VERSION ""

NS_ :

BS_:

BU_:

BO_ 2566587390 NTEHEA: 200 Vector__XXX
 SG_ NOxTEAtvtLtERTB1Tt : 0|32@1+ (1,0) [0|4211081215] "s" Vector__XXX
 SG_ NOxTrkngEngnAtvtLftmEngnRnTmBn2 : 32|32@1+ (1,0) [0|4211081215] "s" Vector__XXX
 SG_ NOxTrkngEngnAtvtLftmEngnRnTmBn3 : 64|32@1+ (1,0) [0|4211081215] "s" Vector__XXX
 SG_ NOxTrkngEngnAtvtLftmEngnRnTmBn4 : 96|32@1+ (1,0) [0|4211081215] "s" Vector__XXX
 SG_ NOxTrkngEngnAtvtLftmEngnRnTmBn5 : 128|32@1+ (1,0) [0|4211081215] "s" Vector__XXX
 SG_ NOxTrkngEngnAtvtLftmEngnRnTmBn6 : 160|32@1+ (1,0) [0|4211081215] "s" Vector__XXX
 SG_ NOxTrkngEngnAtvtLftmEngnRnTmBn7 : 192|32@1+ (1,0) [0|4211081215] "s" Vector__XXX
 SG_ NOxTrkngEngnAtvtLftmEngnRnTmBn8 : 224|32@1+ (1,0) [0|4211081215] "s" Vector__XXX
 SG_ NOxTrkngEngnAtvtLftmEngnRnTmBn9 : 256|32@1+ (1,0) [0|4211081215] "s" Vector__XXX
 SG_ NOxTEAtvtLtERTB10 : 288|32@1+ (1,0) [0|4211081215] "s" Vector__XXX
 SG_ NOxTEAtvtLtERTB11 : 320|32@1+ (1,0) [0|4211081215] "s" Vector__XXX
 SG_ NOxTEAtvtLtERTB12 : 352|32@1+ (1,0) [0|4211081215] "s" Vector__XXX
 SG_ NOxTEAtvtLtERTB13 : 384|32@1+ (1,0) [0|4211081215] "s" Vector__XXX
 SG_ NOxTEAtvtLtERTB14 : 416|32@1+ (1,0) [0|4211081215] "s" Vector__XXX
 SG_ NOxTEAtvtLtERTB15NTEBIN : 448|32@1+ (1,0) [0|4211081215] "s" Vector__XXX
 SG_ NOxTEAtvtLtERTB16RB : 480|32@1+ (1,0) [0|4211081215] "s" Vector__XXX
 SG_ NOxTEAtvtLtERTB17MILOB : 512|32@1+ (1,0) [0|4211081215] "s" Vector__XXX

BO_ 2566587646 NTVMEA: 200 Vector__XXX
 SG_ NOxTEAtvtLtVDstB1Tt : 0|32@1+ (5,0) [0|21055406075] "m" Vector__XXX
 SG_ NOxTrkngEngnAtvtLftmVhlDstnBn2 : 32|32@1+ (5,0) [0|21055406075] "m" Vector__XXX
 SG_ NOxTrkngEngnAtvtLftmVhlDstnBn3 : 64|32@1+ (5,0) [0|21055406075] "m" Vector__XXX
 SG_ NOxTrkngEngnAtvtLftmVhlDstnBn4 : 96|32@1+ (5,0) [0|21055406075] "m" Vector__XXX
 SG_ NOxTrkngEngnAtvtLftmVhlDstnBn5 : 128|32@1+ (5,0) [0|21055406075] "m" Vector__XXX
 SG_ NOxTrkngEngnAtvtLftmVhlDstnBn6 : 160|32@1+ (5,0) [0|21055406075] "m" Vector__XXX
 SG_ NOxTrkngEngnAtvtLftmVhlDstnBn7 : 192|32@1+ (5,0) [0|21055406075] "m" Vector__XXX
 SG_ NOxTrkngEngnAtvtLftmVhlDstnBn8 : 224|32@1+ (5,0) [0|21055406075] "m" Vector__XXX
 SG_ NOxTrkngEngnAtvtLftmVhlDstnBn9 : 256|32@1+ (5,0) [0|21055406075] "m" Vector__XXX
 SG_ NOxTrkngEngnAtvtLftmVhlDstnBn10 : 288|32@1+ (5,0) [0|21055406075] "m" Vector__XXX
 SG_ NOxTrkngEngnAtvtLftmVhlDstnBn11 : 320|32@1+ (5,0) [0|21055406075] "m" Vector__XXX
 SG_ NOxTrkngEngnAtvtLftmVhlDstnBn12 : 352|32@1+ (5,0) [0|21055406075] "m" Vector__XXX
 SG_ NOxTrkngEngnAtvtLftmVhlDstnBn13 : 384|32@1+ (5,0) [0|21055406075] "m" Vector__XXX
 SG_ NOxTrkngEngnAtvtLftmVhlDstnBn14 : 416|32@1+ (5,0) [0|21055406075] "m" Vector__XXX
 SG_ NOxTEAtvtLtVDstB15NTEBIN : 448|32@1+ (5,0) [0|21055406075] "m" Vector__XXX
 SG_ NOxTEAtvtLtVDstB16RB : 480|32@1+ (5,0) [0|21055406075] "m" Vector__XXX
 SG_ NOxTEAtvtLtVDstB17MILOB : 512|32@1+ (5,0) [0|21055406075] "m" Vector__XXX

BO_ 2566587902 NTEEEA: 200 Vector__XXX
 SG_ NOxTEAtvtLtEOtptEB1Tt : 0|32@1+ (1,0) [0|4211081215] "kWh" Vector__XXX
 SG_ NOxTEAtvtLtEOtptEB2 : 32|32@1+ (1,0) [0|4211081215] "kWh" Vector__XXX
 SG_ NOxTEAtvtLtEOtptEB3 : 64|32@1+ (1,0) [0|4211081215] "kWh" Vector__XXX
 SG_ NOxTEAtvtLtEOtptEB4 : 96|32@1+ (1,0) [0|4211081215] "kWh" Vector__XXX
 SG_ NOxTEAtvtLtEOtptEB5 : 128|32@1+ (1,0) [0|4211081215] "kWh" Vector__XXX
 SG_ NOxTEAtvtLtEOtptEB6 : 160|32@1+ (1,0) [0|4211081215] "kWh" Vector__XXX
 SG_ NOxTEAtvtLtEOtptEB7 : 192|32@1+ (1,0) [0|4211081215] "kWh" Vector__XXX
 SG_ NOxTEAtvtLtEOtptEB8 : 224|32@1+ (1,0) [0|4211081215] "kWh" Vector__XXX
 SG_ NOxTEAtvtLtEOtptEB9 : 256|32@1+ (1,0) [0|4211081215] "kWh" Vector__XXX
 SG_ NOxTEAtvtLtEOtptEB10 : 288|32@1+ (1,0) [0|4211081215] "kWh" Vector__XXX
 SG_ NOxTEAtvtLtEOtptEB11 : 320|32@1+ (1,0) [0|4211081215] "kWh" Vector__XXX
 SG_ NOxTEAtvtLtEOtptEB12 : 352|32@1+ (1,0) [0|4211081215] "kWh" Vector__XXX
 SG_ NOxTEAtvtLtEOtptEB13 : 384|32@1+ (1,0) [0|4211081215] "kWh" Vector__XXX
 SG_ NOxTEAtvtLtEOtptEB14 : 416|32@1+ (1,0) [0|4211081215] "kWh" Vector__XXX
 SG_ NOxTEAtvtLtEOtptEB15NTEBIN : 448|32@1+ (1,0) [0|4211081215] "kWh" Vector__XXX
 SG_ NOxTEAtvtLtEOtptEB16RB : 480|32@1+ (1,0) [0|4211081215] "kWh" Vector__XXX
 SG_ NOxTEAtvtLtEOtptEB17MILOB : 512|32@1+ (1,0) [0|4211081215] "kWh" Vector__XXX

BO_ 2566588158 NTFCV: 200 Vector__XXX
 SG_ NOxTVdNOxLtFCsptB1Tt : 0|32@1+ (0.05,0) [0|210554060.75] "l" Vector__XXX
 SG_ NOxTrkngVldNOxLftmFlCnsmptnBn2 : 32|32@1+ (0.05,0) [0|210554060.75] "l" Vector__XXX
 SG_ NOxTrkngVldNOxLftmFlCnsmptnBn3 : 64|32@1+ (0.05,0) [0|210554060.75] "l" Vector__XXX
 SG_ NOxTrkngVldNOxLftmFlCnsmptnBn4 : 96|32@1+ (0.05,0) [0|210554060.75] "l" Vector__XXX
 SG_ NOxTrkngVldNOxLftmFlCnsmptnBn5 : 128|32@1+ (0.05,0) [0|210554060.75] "l" Vector__XXX
 SG_ NOxTrkngVldNOxLftmFlCnsmptnBn6 : 160|32@1+ (0.05,0) [0|210554060.75] "l" Vector__XXX
 SG_ NOxTrkngVldNOxLftmFlCnsmptnBn7 : 192|32@1+ (0.05,0) [0|210554060.75] "l" Vector__XXX
 SG_ NOxTrkngVldNOxLftmFlCnsmptnBn8 : 224|32@1+ (0.05,0) [0|210554060.75] "l" Vector__XXX
 SG_ NOxTrkngVldNOxLftmFlCnsmptnBn9 : 256|32@1+ (0.05,0) [0|210554060.75] "l" Vector__XXX
 SG_ NOxTrkngVldNOxLftmFlCnsmptnBn10 : 288|32@1+ (0.05,0) [0|210554060.75] "l" Vector__XXX
 SG_ NOxTrkngVldNOxLftmFlCnsmptnBn11 : 320|32@1+ (0.05,0) [0|210554060.75] "l" Vector__XXX
 SG_ NOxTrkngVldNOxLftmFlCnsmptnBn12 : 352|32@1+ (0.05,0) [0|210554060.75] "l" Vector__XXX
 SG_ NOxTrkngVldNOxLftmFlCnsmptnBn13 : 384|32@1+ (0.05,0) [0|210554060.75] "l" Vector__XXX
 SG_ NOxTrkngVldNOxLftmFlCnsmptnBn14 : 416|32@1+ (0.05,0) [0|210554060.75] "l" Vector__XXX
 SG_ NOxTVdNOxLtFCsptB15NTEBIN : 448|32@1+ (0.05,0) [0|210554060.75] "l" Vector__XXX
 SG_ NOxTVdNOxLtFCsptB16RB : 480|32@1+ (0.05,0) [0|210554060.75] "l" Vector__XXX
 SG_ NOxTVdNOxLtFCsptB17MILOB : 512|32@1+ (0.05,0) [0|210554060.75] "l" Vector__XXX

BO_ 2566588414 NTEHV: 200 Vector__XXX
 SG_ NOxTVdNOxLtERTB1Tt : 0|32@1+ (1,0) [0|4211081215] "s" Vector__XXX
 SG_ NOxTrkngVldNOxLftmEngnRnTmBn2 : 32|32@1+ (1,0) [0|4211081215] "s" Vector__XXX
 SG_ NOxTrkngVldNOxLftmEngnRnTmBn3 : 64|32@1+ (1,0) [0|4211081215] "s" Vector__XXX
 SG_ NOxTrkngVldNOxLftmEngnRnTmBn4 : 96|32@1+ (1,0) [0|4211081215] "s" Vector__XXX
 SG_ NOxTrkngVldNOxLftmEngnRnTmBn5 : 128|32@1+ (1,0) [0|4211081215] "s" Vector__XXX
 SG_ NOxTrkngVldNOxLftmEngnRnTmBn6 : 160|32@1+ (1,0) [0|4211081215] "s" Vector__XXX
 SG_ NOxTrkngVldNOxLftmEngnRnTmBn7 : 192|32@1+ (1,0) [0|4211081215] "s" Vector__XXX
 SG_ NOxTrkngVldNOxLftmEngnRnTmBn8 : 224|32@1+ (1,0) [0|4211081215] "s" Vector__XXX
 SG_ NOxTrkngVldNOxLftmEngnRnTmBn9 : 256|32@1+ (1,0) [0|4211081215] "s" Vector__XXX
 SG_ NOxTrkngVldNOxLftmEngnRnTmBn10 : 288|32@1+ (1,0) [0|4211081215] "s" Vector__XXX
 SG_ NOxTrkngVldNOxLftmEngnRnTmBn11 : 320|32@1+ (1,0) [0|4211081215] "s" Vector__XXX
 SG_ NOxTrkngVldNOxLftmEngnRnTmBn12 : 352|32@1+ (1,0) [0|4211081215] "s" Vector__XXX
 SG_ NOxTrkngVldNOxLftmEngnRnTmBn13 : 384|32@1+ (1,0) [0|4211081215] "s" Vector__XXX
 SG_ NOxTrkngVldNOxLftmEngnRnTmBn14 : 416|32@1+ (1,0) [0|4211081215] "s" Vector__XXX
 SG_ NOxTVdNOxLtERTB15NTEBIN : 448|32@1+ (1,0) [0|4211081215] "s" Vector__XXX
 SG_ NOxTVdNOxLtERTB16RB : 480|32@1+ (1,0) [0|4211081215] "s" Vector__XXX
 SG_ NOxTVdNOxLtERTB17MILOB : 512|32@1+ (1,0) [0|4211081215] "s" Vector__XXX

BO_ 2566588670 NTVMV: 200 Vector__XXX
 SG_ NOxTrkngVldNOxLftmVhlDstnBn1Ttl : 0|32@1+ (5,0) [0|21055406075] "m" Vector__XXX
 SG_ NOxTrkngVldNOxLftmVhlDstnBn2 : 32|32@1+ (5,0) [0|21055406075] "m" Vector__XXX
 SG_ NOxTrkngVldNOxLftmVhlDstnBn3 : 64|32@1+ (5,0) [0|21055406075] "m" Vector__XXX
 SG_ NOxTrkngVldNOxLftmVhlDstnBn4 : 96|32@1+ (5,0) [0|21055406075] "m" Vector__XXX
 SG_ NOxTrkngVldNOxLftmVhlDstnBn5 : 128|32@1+ (5,0) [0|21055406075] "m" Vector__XXX
 SG_ NOxTrkngVldNOxLftmVhlDstnBn6 : 160|32@1+ (5,0) [0|21055406075] "m" Vector__XXX
 SG_ NOxTrkngVldNOxLftmVhlDstnBn7 : 192|32@1+ (5,0) [0|21055406075] "m" Vector__XXX
 SG_ NOxTrkngVldNOxLftmVhlDstnBn8 : 224|32@1+ (5,0) [0|21055406075] "m" Vector__XXX
 SG_ NOxTrkngVldNOxLftmVhlDstnBn9 : 256|32@1+ (5,0) [0|21055406075] "m" Vector__XXX
 SG_ NOxTrkngVldNOxLftmVhlDstnBn10 : 288|32@1+ (5,0) [0|21055406075] "m" Vector__XXX
 SG_ NOxTrkngVldNOxLftmVhlDstnBn11 : 320|32@1+ (5,0) [0|21055406075] "m" Vector__XXX
 SG_ NOxTrkngVldNOxLftmVhlDstnBn12 : 352|32@1+ (5,0) [0|21055406075] "m" Vector__XXX
 SG_ NOxTrkngVldNOxLftmVhlDstnBn13 : 384|32@1+ (5,0) [0|21055406075] "m" Vector__XXX
 SG_ NOxTrkngVldNOxLftmVhlDstnBn14 : 416|32@1+ (5,0) [0|21055406075] "m" Vector__XXX
 SG_ NOxTVdNOxLtVDstB15NTEBIN : 448|32@1+ (5,0) [0|21055406075] "m" Vector__XXX
 SG_ NOxTVdNOxLtVDstB16RB : 480|32@1+ (5,0) [0|21055406075] "m" Vector__XXX
 SG_ NOxTVdNOxLtVDstB17MILOB : 512|32@1+ (5,0) [0|21055406075] "m" Vector__XXX

BO_ 2566588926 NTEEV: 200 Vector__XXX
 SG_ NOxTVdNOxLtEOtptEB1Tt : 0|32@1+ (1,0) [0|4211081215] "kWh" Vector__XXX
 SG_ NOxTVdNOxLtEOtptEB2 : 32|32@1+ (1,0) [0|4211081215] "kWh" Vector__XXX
 SG_ NOxTVdNOxLtEOtptEB3 : 64|32@1+ (1,0) [0|4211081215] "kWh" Vector__XXX
 SG_ NOxTVdNOxLtEOtptEB4 : 96|32@1+ (1,0) [0|4211081215] "kWh" Vector__XXX
 SG_ NOxTVdNOxLtEOtptEB5 : 128|32@1+ (1,0) [0|4211081215] "kWh" Vector__XXX
 SG_ NOxTVdNOxLtEOtptEB6 : 160|32@1+ (1,0) [0|4211081215] "kWh" Vector__XXX
 SG_ NOxTVdNOxLtEOtptEB7 : 192|32@1+ (1,0) [0|4211081215] "kWh" Vector__XXX
 SG_ NOxTVdNOxLtEOtptEB8 : 224|32@1+ (1,0) [0|4211081215] "kWh" Vector__XXX
 SG_ NOxTVdNOxLtEOtptEB9 : 256|32@1+ (1,0) [0|4211081215] "kWh" Vector__XXX
 SG_ NOxTVdNOxLtEOtptEB10 : 288|32@1+ (1,0) [0|4211081215] "kWh" Vector__XXX
 SG_ NOxTVdNOxLtEOtptEB11 : 320|32@1+ (1,0) [0|4211081215] "kWh" Vector__XXX
 SG_ NOxTVdNOxLtEOtptEB12 : 352|32@1+ (1,0) [0|4211081215] "kWh" Vector__XXX
 SG_ NOxTVdNOxLtEOtptEB13 : 384|32@1+ (1,0) [0|4211081215] "kWh" Vector__XXX
 SG_ NOxTVdNOxLtEOtptEB14 : 416|32@1+ (1,0) [0|4211081215] "kWh" Vector__XXX
 SG_ NOxTVdNOxLtEOtptEB15NTEBIN : 448|32@1+ (1,0) [0|4211081215] "kWh" Vector__XXX
 SG_ NOxTVdNOxLtEOtptEB16RB : 480|32@1+ (1,0) [0|4211081215] "kWh" Vector__XXX
 SG_ NOxTVdNOxLtEOtptEB17MILOB : 512|32@1+ (1,0) [0|4211081215] "kWh" Vector__XXX

BO_ 2566589182 NTENV: 200 Vector__XXX
 SG_ NOxTVdNOxLtEOtNOxMssB1Tt : 0|32@1+ (1,0) [0|4211081215] "g" Vector__XXX
 SG_ NOxTVdNOxLtEOtNOxMssB2 : 32|32@1+ (1,0) [0|4211081215] "g" Vector__XXX
 SG_ NOxTVdNOxLtEOtNOxMssB3 : 64|32@1+ (1,0) [0|4211081215] "g" Vector__XXX
 SG_ NOxTVdNOxLtEOtNOxMssB4 : 96|32@1+ (1,0) [0|4211081215] "g" Vector__XXX
 SG_ NOxTVdNOxLtEOtNOxMssB5 : 128|32@1+ (1,0) [0|4211081215] "g" Vector__XXX
 SG_ NOxTVdNOxLtEOtNOxMssB6 : 160|32@1+ (1,0) [0|4211081215] "g" Vector__XXX
 SG_ NOxTVdNOxLtEOtNOxMssB7 : 192|32@1+ (1,0) [0|4211081215] "g" Vector__XXX
 SG_ NOxTVdNOxLtEOtNOxMssB8 : 224|32@1+ (1,0) [0|4211081215] "g" Vector__XXX
 SG_ NOxTVdNOxLtEOtNOxMssB9 : 256|32@1+ (1,0) [0|4211081215] "g" Vector__XXX
 SG_ NOxTVdNOxLtEOtNOxMssB10 : 288|32@1+ (1,0) [0|4211081215] "g" Vector__XXX
 SG_ NOxTVdNOxLtEOtNOxMssB11 : 320|32@1+ (1,0) [0|4211081215] "g" Vector__XXX
 SG_ NOxTVdNOxLtEOtNOxMssB12 : 352|32@1+ (1,0) [0|4211081215] "g" Vector__XXX
 SG_ NOxTVdNOxLtEOtNOxMssB13 : 384|32@1+ (1,0) [0|4211081215] "g" Vector__XXX
 SG_ NOxTVdNOxLtEOtNOxMssB14 : 416|32@1+ (1,0) [0|4211081215] "g" Vector__XXX
 SG_ NOxTVdNOxLtEOtNOxMssB15NTEBIN : 448|32@1+ (1,0) [0|4211081215] "g" Vector__XXX
 SG_ NOxTVdNOxLtEOtNOxMssB16RB : 480|32@1+ (1,0) [0|4211081215] "g" Vector__XXX
 SG_ NOxTVdNOxLtEOtNOxMssB17MILOB : 512|32@1+ (1,0) [0|4211081215] "g" Vector__XXX

BO_ 2566589438 NTSNV: 200 Vector__XXX
 SG_ NOxTVdNOxLtSstOtNOxMssB1Tt : 0|32@1+ (1,0) [0|4211081215] "g" Vector__XXX
 SG_ NOxTVdNOxLtSstOtNOxMssB2 : 32|32@1+ (1,0) [0|4211081215] "g" Vector__XXX
 SG_ NOxTVdNOxLtSstOtNOxMssB3 : 64|32@1+ (1,0) [0|4211081215] "g" Vector__XXX
 SG_ NOxTVdNOxLtSstOtNOxMssB4 : 96|32@1+ (1,0) [0|4211081215] "g" Vector__XXX
 SG_ NOxTVdNOxLtSstOtNOxMssB5 : 128|32@1+ (1,0) [0|4211081215] "g" Vector__XXX
 SG_ NOxTVdNOxLtSstOtNOxMssB6 : 160|32@1+ (1,0) [0|4211081215] "g" Vector__XXX
 SG_ NOxTVdNOxLtSstOtNOxMssB7 : 192|32@1+ (1,0) [0|4211081215] "g" Vector__XXX
 SG_ NOxTVdNOxLtSstOtNOxMssB8 : 224|32@1+ (1,0) [0|4211081215] "g" Vector__XXX
 SG_ NOxTVdNOxLtSstOtNOxMssB9 : 256|32@1+ (1,0) [0|4211081215] "g" Vector__XXX
 SG_ NOxTVdNOxLtSstOtNOxMssB10 : 288|32@1+ (1,0) [0|4211081215] "g" Vector__XXX
 SG_ NOxTVdNOxLtSstOtNOxMssB11 : 320|32@1+ (1,0) [0|4211081215] "g" Vector__XXX
 SG_ NOxTVdNOxLtSstOtNOxMssB12 : 352|32@1+ (1,0) [0|4211081215] "g" Vector__XXX
 SG_ NOxTVdNOxLtSstOtNOxMssB13 : 384|32@1+ (1,0) [0|4211081215] "g" Vector__XXX
 SG_ NOxTVdNOxLtSstOtNOxMssB14 : 416|32@1+ (1,0) [0|4211081215] "g" Vector__XXX
 SG_ NOxTVdNOxLtSstOtNOxMssB15NTEBIN : 448|32@1+ (1,0) [0|4211081215] "g" Vector__XXX
 SG_ NOxTVdNOxLtSstOtNOxMssB16RB : 480|32@1+ (1,0) [0|4211081215] "g" Vector__XXX
 SG_ NOxTVdNOxLtSstOtNOxMssB17MILOB : 512|32@1+ (1,0) [0|4211081215] "g" Vector__XXX

BO_ 2566589694 NTFCS: 200 Vector__XXX
 SG_ NOxTStd100HFCsptB1Tt : 0|16@1+ (0.5,0) [0|32127.5] "l" Vector__XXX
 SG_ NOxTrkngStrd100HrFlCnsmptnBn2 : 16|16@1+ (0.5,0) [0|32127.5] "l" Vector__XXX
 SG_ NOxTrkngStrd100HrFlCnsmptnBn3 : 32|16@1+ (0.5,0) [0|32127.5] "l" Vector__XXX
 SG_ NOxTrkngStrd100HrFlCnsmptnBn4 : 48|16@1+ (0.5,0) [0|32127.5] "l" Vector__XXX
 SG_ NOxTrkngStrd100HrFlCnsmptnBn5 : 64|16@1+ (0.5,0) [0|32127.5] "l" Vector__XXX
 SG_ NOxTrkngStrd100HrFlCnsmptnBn6 : 80|16@1+ (0.5,0) [0|32127.5] "l" Vector__XXX
 SG_ NOxTrkngStrd100HrFlCnsmptnBn7 : 96|16@1+ (0.5,0) [0|32127.5] "l" Vector__XXX
 SG_ NOxTrkngStrd100HrFlCnsmptnBn8 : 112|16@1+ (0.5,0) [0|32127.5] "l" Vector__XXX
 SG_ NOxTrkngStrd100HrFlCnsmptnBn9 : 128|16@1+ (0.5,0) [0|32127.5] "l" Vector__XXX
 SG_ NOxTrkngStrd100HrFlCnsmptnBn10 : 144|16@1+ (0.5,0) [0|32127.5] "l" Vector__XXX
 SG_ NOxTrkngStrd100HrFlCnsmptnBn11 : 160|16@1+ (0.5,0) [0|32127.5] "l" Vector__XXX
 SG_ NOxTrkngStrd100HrFlCnsmptnBn12 : 176|16@1+ (0.5,0) [0|32127.5] "l" Vector__XXX
 SG_ NOxTrkngStrd100HrFlCnsmptnBn13 : 192|16@1+ (0.5,0) [0|32127.5] "l" Vector__XXX
 SG_ NOxTrkngStrd100HrFlCnsmptnBn14 : 208|16@1+ (0.5,0) [0|32127.5] "l" Vector__XXX
 SG_ NOxTStd100HFCsptB15NTEBIN : 224|16@1+ (0.5,0) [0|32127.5] "l" Vector__XXX
 SG_ NOxTStd100HFCsptB16RB : 240|16@1+ (0.5,0) [0|32127.5] "l" Vector__XXX
 SG_ NOxTStd100HFCsptB17MILOB : 256|16@1+ (0.5,0) [0|32127.5] "l" Vector__XXX

BO_ 2566589950 NTEHS: 200 Vector__XXX
 SG_ NOxTrkngStrd100HrEngnRnTmBn1Ttl : 0|16@1+ (10,0) [0|642550] "s" Vector__XXX
 SG_ NOxTrkngStrd100HrEngnRnTmBn2 : 16|16@1+ (10,0) [0|642550] "s" Vector__XXX
 SG_ NOxTrkngStrd100HrEngnRnTmBn3 : 32|16@1+ (10,0) [0|642550] "s" Vector__XXX
 SG_ NOxTrkngStrd100HrEngnRnTmBn4 : 48|16@1+ (10,0) [0|642550] "s" Vector__XXX
 SG_ NOxTrkngStrd100HrEngnRnTmBn5 : 64|16@1+ (10,0) [0|642550] "s" Vector__XXX
 SG_ NOxTrkngStrd100HrEngnRnTmBn6 : 80|16@1+ (10,0) [0|642550] "s" Vector__XXX
 SG_ NOxTrkngStrd100HrEngnRnTmBn7 : 96|16@1+ (10,0) [0|642550] "s" Vector__XXX
 SG_ NOxTrkngStrd100HrEngnRnTmBn8 : 112|16@1+ (10,0) [0|642550] "s" Vector__XXX
 SG_ NOxTrkngStrd100HrEngnRnTmBn9 : 128|16@1+ (10,0) [0|642550] "s" Vector__XXX
 SG_ NOxTrkngStrd100HrEngnRnTmBn10 : 144|16@1+ (10,0) [0|642550] "s" Vector__XXX
 SG_ NOxTrkngStrd100HrEngnRnTmBn11 : 160|16@1+ (10,0) [0|642550] "s" Vector__XXX
 SG_ NOxTrkngStrd100HrEngnRnTmBn12 : 176|16@1+ (10,0) [0|642550] "s" Vector__XXX
 SG_ NOxTrkngStrd100HrEngnRnTmBn13 : 192|16@1+ (10,0) [0|642550] "s" Vector__XXX
 SG_ NOxTrkngStrd100HrEngnRnTmBn14 : 208|16@1+ (10,0) [0|642550] "s" Vector__XXX
 SG_ NOxTStd100HERTB15NTEBIN : 224|16@1+ (10,0) [0|642550] "s" Vector__XXX
 SG_ NOxTStd100HERTB16RB : 240|16@1+ (10,0) [0|642550] "s" Vector__XXX
 SG_ NOxTStd100HERTB17MILOB : 256|16@1+ (10,0) [0|642550] "s" Vector__XXX

BO_ 2566590206 NTVMS: 200 Vector__XXX
 SG_ NOxTrkngStrd100HrVhlDstnBn1Ttl : 0|16@1+ (0.25,0) [0|16063.75] "km" Vector__XXX
 SG_ NOxTrkngStrd100HrVhlDstnBn2 : 16|16@1+ (0.25,0) [0|16063.75] "km" Vector__XXX
 SG_ NOxTrkngStrd100HrVhlDstnBn3 : 32|16@1+ (0.25,0) [0|16063.75] "km" Vector__XXX
 SG_ NOxTrkngStrd100HrVhlDstnBn4 : 48|16@1+ (0.25,0) [0|16063.75] "km" Vector__XXX
 SG_ NOxTrkngStrd100HrVhlDstnBn5 : 64|16@1+ (0.25,0) [0|16063.75] "km" Vector__XXX
 SG_ NOxTrkngStrd100HrVhlDstnBn6 : 80|16@1+ (0.25,0) [0|16063.75] "km" Vector__XXX
 SG_ NOxTrkngStrd100HrVhlDstnBn7 : 96|16@1+ (0.25,0) [0|16063.75] "km" Vector__XXX
 SG_ NOxTrkngStrd100HrVhlDstnBn8 : 112|16@1+ (0.25,0) [0|16063.75] "km" Vector__XXX
 SG_ NOxTrkngStrd100HrVhlDstnBn9 : 128|16@1+ (0.25,0) [0|16063.75] "km" Vector__XXX
 SG_ NOxTrkngStrd100HrVhlDstnBn10 : 144|16@1+ (0.25,0) [0|16063.75] "km" Vector__XXX
 SG_ NOxTrkngStrd100HrVhlDstnBn11 : 160|16@1+ (0.25,0) [0|16063.75] "km" Vector__XXX
 SG_ NOxTrkngStrd100HrVhlDstnBn12 : 176|16@1+ (0.25,0) [0|16063.75] "km" Vector__XXX
 SG_ NOxTrkngStrd100HrVhlDstnBn13 : 192|16@1+ (0.25,0) [0|16063.75] "km" Vector__XXX
 SG_ NOxTrkngStrd100HrVhlDstnBn14 : 208|16@1+ (0.25,0) [0|16063.75] "km" Vector__XXX
 SG_ NOxTStd100HVDstB15NTEBIN : 224|16@1+ (0.25,0) [0|16063.75] "km" Vector__XXX
 SG_ NOxTStd100HVDstB16RB : 240|16@1+ (0.25,0) [0|16063.75] "km" Vector__XXX
 SG_ NOxTStd100HVDstB17MILOB : 256|16@1+ (0.25,0) [0|16063.75] "km" Vector__XXX

BO_ 2566590462 NTEES: 200 Vector__XXX
 SG_ NOxTStd100HEOtptEB1Tt : 0|16@1+ (1,0) [0|64255] "kWh" Vector__XXX
 SG_ NOxTStd100HEOtptEB2 : 16|16@1+ (1,0) [0|64255] "kWh" Vector__XXX
 SG_ NOxTStd100HEOtptEB3 : 32|16@1+ (1,0) [0|64255] "kWh" Vector__XXX
 SG_ NOxTStd100HEOtptEB4 : 48|16@1+ (1,0) [0|64255] "kWh" Vector__XXX
 SG_ NOxTStd100HEOtptEB5 : 64|16@1+ (1,0) [0|64255] "kWh" Vector__XXX
 SG_ NOxTStd100HEOtptEB6 : 80|16@1+ (1,0) [0|64255] "kWh" Vector__XXX
 SG_ NOxTStd100HEOtptEB7 : 96|16@1+ (1,0) [0|64255] "kWh" Vector__XXX
 SG_ NOxTStd100HEOtptEB8 : 112|16@1+ (1,0) [0|64255] "kWh" Vector__XXX
 SG_ NOxTStd100HEOtptEB9 : 128|16@1+ (1,0) [0|64255] "kWh" Vector__XXX
 SG_ NOxTStd100HEOtptEB10 : 144|16@1+ (1,0) [0|64255] "kWh" Vector__XXX
 SG_ NOxTStd100HEOtptEB11 : 160|16@1+ (1,0) [0|64255] "kWh" Vector__XXX
 SG_ NOxTStd100HEOtptEB12 : 176|16@1+ (1,0) [0|64255] "kWh" Vector__XXX
 SG_ NOxTStd100HEOtptEB13 : 192|16@1+ (1,0) [0|64255] "kWh" Vector__XXX
 SG_ NOxTStd100HEOtptEB14 : 208|16@1+ (1,0) [0|64255] "kWh" Vector__XXX
 SG_ NOxTStd100HEOtptEB15NTEBIN : 224|16@1+ (1,0) [0|64255] "kWh" Vector__XXX
 SG_ NOxTStd100HEOtptEB16RB : 240|16@1+ (1,0) [0|64255] "kWh" Vector__XXX
 SG_ NOxTStd100HEOtptEB17MILOB : 256|16@1+ (1,0) [0|64255] "kWh" Vector__XXX

BO_ 2566590718 NTENS: 200 Vector__XXX
 SG_ NOxTStd100HEOtNOxMssB1Tt : 0|32@1+ (0.0005,0) [0|2105540.6075] "g" Vector__XXX
 SG_ NOxTStd100HEOtNOxMssB2 : 32|32@1+ (0.0005,0) [0|2105540.6075] "g" Vector__XXX
 SG_ NOxTStd100HEOtNOxMssB3 : 64|32@1+ (0.0005,0) [0|2105540.6075] "g" Vector__XXX
 SG_ NOxTStd100HEOtNOxMssB4 : 96|32@1+ (0.0005,0) [0|2105540.6075] "g" Vector__XXX
 SG_ NOxTStd100HEOtNOxMssB5 : 128|32@1+ (0.0005,0) [0|2105540.6075] "g" Vector__XXX
 SG_ NOxTStd100HEOtNOxMssB6 : 160|32@1+ (0.0005,0) [0|2105540.6075] "g" Vector__XXX
 SG_ NOxTStd100HEOtNOxMssB7 : 192|32@1+ (0.0005,0) [0|2105540.6075] "g" Vector__XXX
 SG_ NOxTStd100HEOtNOxMssB8 : 224|32@1+ (0.0005,0) [0|2105540.6075] "g" Vector__XXX
 SG_ NOxTStd100HEOtNOxMssB9 : 256|32@1+ (0.0005,0) [0|2105540.6075] "g" Vector__XXX
 SG_ NOxTStd100HEOtNOxMssB10 : 288|32@1+ (0.0005,0) [0|2105540.6075] "g" Vector__XXX
 SG_ NOxTStd100HEOtNOxMssB11 : 320|32@1+ (0.0005,0) [0|2105540.6075] "g" Vector__XXX
 SG_ NOxTStd100HEOtNOxMssB12 : 352|32@1+ (0.0005,0) [0|2105540.6075] "g" Vector__XXX
 SG_ NOxTStd100HEOtNOxMssB13 : 384|32@1+ (0.0005,0) [0|2105540.6075] "g" Vector__XXX
 SG_ NOxTStd100HEOtNOxMssB14 : 416|32@1+ (0.0005,0) [0|2105540.6075] "g" Vector__XXX
 SG_ NOxTStd100HEOtNOxMssB15NTEBIN : 448|32@1+ (0.0005,0) [0|2105540.6075] "g" Vector__XXX
 SG_ NOxTStd100HEOtNOxMssB16RB : 480|32@1+ (0.0005,0) [0|2105540.6075] "g" Vector__XXX
 SG_ NOxTStd100HEOtNOxMssB17MILOB : 512|32@1+ (0.0005,0) [0|2105540.6075] "g" Vector__XXX

BO_ 2566590974 NTSNS: 200 Vector__XXX
 SG_ NOxTStd100HSstOtNOxMssB1Tt : 0|32@1+ (0.0002,0) [0|842216.243] "g" Vector__XXX
 SG_ NOxTStd100HSstOtNOxMssB2 : 32|32@1+ (0.0002,0) [0|842216.243] "g" Vector__XXX
 SG_ NOxTStd100HSstOtNOxMssB3 : 64|32@1+ (0.0002,0) [0|842216.243] "g" Vector__XXX
 SG_ NOxTStd100HSstOtNOxMssB4 : 96|32@1+ (0.0002,0) [0|842216.243] "g" Vector__XXX
 SG_ NOxTStd100HSstOtNOxMssB5 : 128|32@1+ (0.0002,0) [0|842216.243] "g" Vector__XXX
 SG_ NOxTStd100HSstOtNOxMssB6 : 160|32@1+ (0.0002,0) [0|842216.243] "g" Vector__XXX
 SG_ NOxTStd100HSstOtNOxMssB7 : 192|32@1+ (0.0002,0) [0|842216.243] "g" Vector__XXX
 SG_ NOxTStd100HSstOtNOxMssB8 : 224|32@1+ (0.0002,0) [0|842216.243] "g" Vector__XXX
 SG_ NOxTStd100HSstOtNOxMssB9 : 256|32@1+ (0.0002,0) [0|842216.243] "g" Vector__XXX
 SG_ NOxTStd100HSstOtNOxMssB10 : 288|32@1+ (0.0002,0) [0|842216.243] "g" Vector__XXX
 SG_ NOxTStd100HSstOtNOxMssB11 : 320|32@1+ (0.0002,0) [0|842216.243] "g" Vector__XXX
 SG_ NOxTStd100HSstOtNOxMssB12 : 352|32@1+ (0.0002,0) [0|842216.243] "g" Vector__XXX
 SG_ NOxTStd100HSstOtNOxMssB13 : 384|32@1+ (0.0002,0) [0|842216.243] "g" Vector__XXX
 SG_ NOxTStd100HSstOtNOxMssB14 : 416|32@1+ (0.0002,0) [0|842216.243] "g" Vector__XXX
 SG_ NOxTStd100HSstOtNOxMssB15NTEBIN : 448|32@1+ (0.0002,0) [0|842216.243] "g" Vector__XXX
 SG_ NOxTStd100HSstOtNOxMssB16RB : 480|32@1+ (0.0002,0) [0|842216.243] "g" Vector__XXX
 SG_ NOxTStd100HSstOtNOxMssB17MILOB : 512|32@1+ (0.0002,0) [0|842216.243] "g" Vector__XXX

BO_ 2566591230 NTFCA: 200 Vector__XXX
 SG_ NOxTrkngAtv100HrFlCnsmptnBn1Ttl : 0|16@1+ (0.5,0) [0|32127.5] "l" Vector__XXX
 SG_ NOxTrkngAtv100HrFlCnsmptnBn2 : 16|16@1+ (0.5,0) [0|32127.5] "l" Vector__XXX
 SG_ NOxTrkngAtv100HrFlCnsmptnBn3 : 32|16@1+ (0.5,0) [0|32127.5] "l" Vector__XXX
 SG_ NOxTrkngAtv100HrFlCnsmptnBn4 : 48|16@1+ (0.5,0) [0|32127.5] "l" Vector__XXX
 SG_ NOxTrkngAtv100HrFlCnsmptnBn5 : 64|16@1+ (0.5,0) [0|32127.5] "l" Vector__XXX
 SG_ NOxTrkngAtv100HrFlCnsmptnBn6 : 80|16@1+ (0.5,0) [0|32127.5] "l" Vector__XXX
 SG_ NOxTrkngAtv100HrFlCnsmptnBn7 : 96|16@1+ (0.5,0) [0|32127.5] "l" Vector__XXX
 SG_ NOxTrkngAtv100HrFlCnsmptnBn8 : 112|16@1+ (0.5,0) [0|32127.5] "l" Vector__XXX
 SG_ NOxTrkngAtv100HrFlCnsmptnBn9 : 128|16@1+ (0.5,0) [0|32127.5] "l" Vector__XXX
 SG_ NOxTrkngAtv100HrFlCnsmptnBn10 : 144|16@1+ (0.5,0) [0|32127.5] "l" Vector__XXX
 SG_ NOxTrkngAtv100HrFlCnsmptnBn11 : 160|16@1+ (0.5,0) [0|32127.5] "l" Vector__XXX
 SG_ NOxTrkngAtv100HrFlCnsmptnBn12 : 176|16@1+ (0.5,0) [0|32127.5] "l" Vector__XXX
 SG_ NOxTrkngAtv100HrFlCnsmptnBn13 : 192|16@1+ (0.5,0) [0|32127.5] "l" Vector__XXX
 SG_ NOxTrkngAtv100HrFlCnsmptnBn14 : 208|16@1+ (0.5,0) [0|32127.5] "l" Vector__XXX
 SG_ NOxTAtv100HFCsptB15NTEBIN : 224|16@1+ (0.5,0) [0|32127.5] "l" Vector__XXX
 SG_ NOxTAtv100HFCsptB16RB : 240|16@1+ (0.5,0) [0|32127.5] "l" Vector__XXX
 SG_ NOxTAtv100HFCsptB17MILOB : 256|16@1+ (0.5,0) [0|32127.5] "l" Vector__XXX

BO_ 2566591486 NTEHA: 200 Vector__XXX
 SG_ NOxTrkngAtv100HrEngnRnTmBn1Ttl : 0|16@1+ (10,0) [0|642550] "s" Vector__XXX
 SG_ NOxTrkngAtv100HrEngnRnTmBn2 : 16|16@1+ (10,0) [0|642550] "s" Vector__XXX
 SG_ NOxTrkngAtv100HrEngnRnTmBn3 : 32|16@1+ (10,0) [0|642550] "s" Vector__XXX
 SG_ NOxTrkngAtv100HrEngnRnTmBn4 : 48|16@1+ (10,0) [0|642550] "s" Vector__XXX
 SG_ NOxTrkngAtv100HrEngnRnTmBn5 : 64|16@1+ (10,0) [0|642550] "s" Vector__XXX
 SG_ NOxTrkngAtv100HrEngnRnTmBn6 : 80|16@1+ (10,0) [0|642550] "s" Vector__XXX
 SG_ NOxTrkngAtv100HrEngnRnTmBn7 : 96|16@1+ (10,0) [0|642550] "s" Vector__XXX
 SG_ NOxTrkngAtv100HrEngnRnTmBn8 : 112|16@1+ (10,0) [0|642550] "s" Vector__XXX
 SG_ NOxTrkngAtv100HrEngnRnTmBn9 : 128|16@1+ (10,0) [0|642550] "s" Vector__XXX
 SG_ NOxTrkngAtv100HrEngnRnTmBn10 : 144|16@1+ (10,0) [0|642550] "s" Vector__XXX
 SG_ NOxTrkngAtv100HrEngnRnTmBn11 : 160|16@1+ (10,0) [0|642550] "s" Vector__XXX
 SG_ NOxTrkngAtv100HrEngnRnTmBn12 : 176|16@1+ (10,0) [0|642550] "s" Vector__XXX
 SG_ NOxTrkngAtv100HrEngnRnTmBn13 : 192|16@1+ (10,0) [0|642550] "s" Vector__XXX
 SG_ NOxTrkngAtv100HrEngnRnTmBn14 : 208|16@1+ (10,0) [0|642550] "s" Vector__XXX
 SG_ NOxTAtv100HERTB15NTEBIN : 224|16@1+ (10,0) [0|642550] "s" Vector__XXX
 SG_ NOxTAtv100HERTB16RB : 240|16@1+ (10,0) [0|642550] "s" Vector__XXX
 SG_ NOxTAtv100HERTB17MILOB : 256|16@1+ (10,0) [0|642550] "s" Vector__XXX

BO_ 2566591742 NTVMA: 200 Vector__XXX
 SG_ NOxTrkngAtv100HrVhlDstnBn1Ttl : 0|16@1+ (0.25,0) [0|16063.75] "km" Vector__XXX
 SG_ NOxTrkngAtv100HrVhlDstnBn2 : 16|16@1+ (0.25,0) [0|16063.75] "km" Vector__XXX
 SG_ NOxTrkngAtv100HrVhlDstnBn3 : 32|16@1+ (0.25,0) [0|16063.75] "km" Vector__XXX
 SG_ NOxTrkngAtv100HrVhlDstnBn4 : 48|16@1+ (0.25,0) [0|16063.75] "km" Vector__XXX
 SG_ NOxTrkngAtv100HrVhlDstnBn5 : 64|16@1+ (0.25,0) [0|16063.75] "km" Vector__XXX
 SG_ NOxTrkngAtv100HrVhlDstnBn6 : 80|16@1+ (0.25,0) [0|16063.75] "km" Vector__XXX
 SG_ NOxTrkngAtv100HrVhlDstnBn7 : 96|16@1+ (0.25,0) [0|16063.75] "km" Vector__XXX
 SG_ NOxTrkngAtv100HrVhlDstnBn8 : 112|16@1+ (0.25,0) [0|16063.75] "km" Vector__XXX
 SG_ NOxTrkngAtv100HrVhlDstnBn9 : 128|16@1+ (0.25,0) [0|16063.75] "km" Vector__XXX
 SG_ NOxTrkngAtv100HrVhlDstnBn10 : 144|16@1+ (0.25,0) [0|16063.75] "km" Vector__XXX
 SG_ NOxTrkngAtv100HrVhlDstnBn11 : 160|16@1+ (0.25,0) [0|16063.75] "km" Vector__XXX
 SG_ NOxTrkngAtv100HrVhlDstnBn12 : 176|16@1+ (0.25,0) [0|16063.75] "km" Vector__XXX
 SG_ NOxTrkngAtv100HrVhlDstnBn13 : 192|16@1+ (0.25,0) [0|16063.75] "km" Vector__XXX
 SG_ NOxTrkngAtv100HrVhlDstnBn14 : 208|16@1+ (0.25,0) [0|16063.75] "km" Vector__XXX
 SG_ NOxTAtv100HVDstB15NTEBIN : 224|16@1+ (0.25,0) [0|16063.75] "km" Vector__XXX
 SG_ NOxTAtv100HVDstB16RB : 240|16@1+ (0.25,0) [0|16063.75] "km" Vector__XXX
 SG_ NOxTAtv100HVDstB17MILOB : 256|16@1+ (0.25,0) [0|16063.75] "km" Vector__XXX

BO_ 2566591998 NTEEA: 200 Vector__XXX
 SG_ NOxTAtv100HEOtptEB1Tt : 0|16@1+ (1,0) [0|64255] "kWh" Vector__XXX
 SG_ NOxTrkngAtv100HrEngnOtptEnrgBn2 : 16|16@1+ (1,0) [0|64255] "kWh" Vector__XXX
 SG_ NOxTrkngAtv100HrEngnOtptEnrgBn3 : 32|16@1+ (1,0) [0|64255] "kWh" Vector__XXX
 SG_ NOxTrkngAtv100HrEngnOtptEnrgBn4 : 48|16@1+ (1,0) [0|64255] "kWh" Vector__XXX
 SG_ NOxTrkngAtv100HrEngnOtptEnrgBn5 : 64|16@1+ (1,0) [0|64255] "kWh" Vector__XXX
 SG_ NOxTrkngAtv100HrEngnOtptEnrgBn6 : 80|16@1+ (1,0) [0|64255] "kWh" Vector__XXX
 SG_ NOxTrkngAtv100HrEngnOtptEnrgBn7 : 96|16@1+ (1,0) [0|64255] "kWh" Vector__XXX
 SG_ NOxTrkngAtv100HrEngnOtptEnrgBn8 : 112|16@1+ (1,0) [0|64255] "kWh" Vector__XXX
 SG_ NOxTrkngAtv100HrEngnOtptEnrgBn9 : 128|16@1+ (1,0) [0|64255] "kWh" Vector__XXX
 SG_ NOxTAtv100HEOtptEB10 : 144|16@1+ (1,0) [0|64255] "kWh" Vector__XXX
 SG_ NOxTAtv100HEOtptEB11 : 160|16@1+ (1,0) [0|64255] "kWh" Vector__XXX
 SG_ NOxTAtv100HEOtptEB12 : 176|16@1+ (1,0) [0|64255] "kWh" Vector__XXX
 SG_ NOxTAtv100HEOtptEB13 : 192|16@1+ (1,0) [0|64255] "kWh" Vector__XXX
 SG_ NOxTAtv100HEOtptEB14 : 208|16@1+ (1,0) [0|64255] "kWh" Vector__XXX
 SG_ NOxTAtv100HEOtptEB15NTEBIN : 224|16@1+ (1,0) [0|64255] "kWh" Vector__XXX
 SG_ NOxTAtv100HEOtptEB16RB : 240|16@1+ (1,0) [0|64255] "kWh" Vector__XXX
 SG_ NOxTAtv100HEOtptEB17MILOB : 256|16@1+ (1,0) [0|64255] "kWh" Vector__XXX

BO_ 2566592254 NTENA: 200 Vector__XXX
 SG_ NOxTAtv100HEOtNOxMssB1Tt : 0|32@1+ (0.0005,0) [0|2105540.6075] "g" Vector__XXX
 SG_ NOxTrkngAtv100HrEngnOtNOxMssBn2 : 32|32@1+ (0.0005,0) [0|2105540.6075] "g" Vector__XXX
 SG_ NOxTrkngAtv100HrEngnOtNOxMssBn3 : 64|32@1+ (0.0005,0) [0|2105540.6075] "g" Vector__XXX
 SG_ NOxTrkngAtv100HrEngnOtNOxMssBn4 : 96|32@1+ (0.0005,0) [0|2105540.6075] "g" Vector__XXX
 SG_ NOxTrkngAtv100HrEngnOtNOxMssBn5 : 128|32@1+ (0.0005,0) [0|2105540.6075] "g" Vector__XXX
 SG_ NOxTrkngAtv100HrEngnOtNOxMssBn6 : 160|32@1+ (0.0005,0) [0|2105540.6075] "g" Vector__XXX
 SG_ NOxTrkngAtv100HrEngnOtNOxMssBn7 : 192|32@1+ (0.0005,0) [0|2105540.6075] "g" Vector__XXX
 SG_ NOxTrkngAtv100HrEngnOtNOxMssBn8 : 224|32@1+ (0.0005,0) [0|2105540.6075] "g" Vector__XXX
 SG_ NOxTrkngAtv100HrEngnOtNOxMssBn9 : 256|32@1+ (0.0005,0) [0|2105540.6075] "g" Vector__XXX
 SG_ NOxTAtv100HEOtNOxMssB10 : 288|32@1+ (0.0005,0) [0|2105540.6075] "g" Vector__XXX
 SG_ NOxTAtv100HEOtNOxMssB11 : 320|32@1+ (0.0005,0) [0|2105540.6075] "g" Vector__XXX
 SG_ NOxTAtv100HEOtNOxMssB12 : 352|32@1+ (0.0005,0) [0|2105540.6075] "g" Vector__XXX
 SG_ NOxTAtv100HEOtNOxMssB13 : 384|32@1+ (0.0005,0) [0|2105540.6075] "g" Vector__XXX
 SG_ NOxTAtv100HEOtNOxMssB14 : 416|32@1+ (0.0005,0) [0|2105540.6075] "g" Vector__XXX
 SG_ NOxTAtv100HEOtNOxMssB15NTEBIN : 448|32@1+ (0.0005,0) [0|2105540.6075] "g" Vector__XXX
 SG_ NOxTAtv100HEOtNOxMssB16RB : 480|32@1+ (0.0005,0) [0|2105540.6075] "g" Vector__XXX
 SG_ NOxTAtv100HEOtNOxMssB17MILOB : 512|32@1+ (0.0005,0) [0|2105540.6075] "g" Vector__XXX

BO_ 2566592510 NTSNA: 200 Vector__XXX
 SG_ NOxTAtv100HSstOtNOxMssB1Tt : 0|32@1+ (0.0002,0) [0|842216.243] "g" Vector__XXX
 SG_ NOxTrkngAtv100HrSstmOtNOxMssBn2 : 32|32@1+ (0.0002,0) [0|842216.243] "g" Vector__XXX
 SG_ NOxTrkngAtv100HrSstmOtNOxMssBn3 : 64|32@1+ (0.0002,0) [0|842216.243] "g" Vector__XXX
 SG_ NOxTrkngAtv100HrSstmOtNOxMssBn4 : 96|32@1+ (0.0002,0) [0|842216.243] "g" Vector__XXX
 SG_ NOxTrkngAtv100HrSstmOtNOxMssBn5 : 128|32@1+ (0.0002,0) [0|842216.243] "g" Vector__XXX
 SG_ NOxTrkngAtv100HrSstmOtNOxMssBn6 : 160|32@1+ (0.0002,0) [0|842216.243] "g" Vector__XXX
 SG_ NOxTrkngAtv100HrSstmOtNOxMssBn7 : 192|32@1+ (0.0002,0) [0|842216.243] "g" Vector__XXX
 SG_ NOxTrkngAtv100HrSstmOtNOxMssBn8 : 224|32@1+ (0.0002,0) [0|842216.243] "g" Vector__XXX
 SG_ NOxTrkngAtv100HrSstmOtNOxMssBn9 : 256|32@1+ (0.0002,0) [0|842216.243] "g" Vector__XXX
 SG_ NOxTAtv100HSstOtNOxMssB10 : 288|32@1+ (0.0002,0) [0|842216.243] "g" Vector__XXX
 SG_ NOxTAtv100HSstOtNOxMssB11 : 320|32@1+ (0.0002,0) [0|842216.243] "g" Vector__XXX
 SG_ NOxTAtv100HSstOtNOxMssB12 : 352|32@1+ (0.0002,0) [0|842216.243] "g" Vector__XXX
 SG_ NOxTAtv100HSstOtNOxMssB13 : 384|32@1+ (0.0002,0) [0|842216.243] "g" Vector__XXX
 SG_ NOxTAtv100HSstOtNOxMssB14 : 416|32@1+ (0.0002,0) [0|842216.243] "g" Vector__XXX
 SG_ NOxTAtv100HSstOtNOxMssB15NTEBIN : 448|32@1+ (0.0002,0) [0|842216.243] "g" Vector__XXX
 SG_ NOxTAtv100HSstOtNOxMssB16RB : 480|32@1+ (0.0002,0) [0|842216.243] "g" Vector__XXX
 SG_ NOxTAtv100HSstOtNOxMssB17MILOB : 512|32@1+ (0.0002,0) [0|842216.243] "g" Vector__XXX

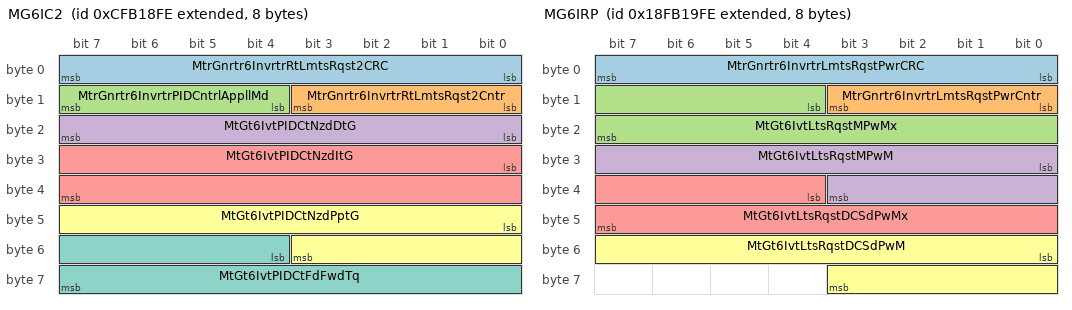
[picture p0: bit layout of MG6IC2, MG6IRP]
BO_ 2365266174 MG6IC2: 8 Vector__XXX
 SG_ MtrGnrtr6InvrtrRtLmtsRqst2CRC : 0|8@1+ (1,0) [0|255] "count" Vector__XXX
 SG_ MtrGnrtr6InvrtrRtLmtsRqst2Cntr : 8|4@1+ (1,0) [0|15] "" Vector__XXX
 SG_ MtrGnrtr6InvrtrPIDCntrlAppllMd : 12|4@1+ (1,0) [0|15] "" Vector__XXX
 SG_ MtGt6IvtPIDCtNzdDtG : 16|8@1+ (11689,0) [0|7.8125] "%/(%/s)" Vector__XXX
 SG_ MtGt6IvtPIDCtNzdItG : 24|16@1+ (23377,0) [0|1003.984375] "%/(%/s)" Vector__XXX
 SG_ MtGt6IvtPIDCtNzdPptG : 40|12@1+ (42370,0) [0|250.9375] "%/%" Vector__XXX
 SG_ MtGt6IvtPIDCtFdFwdTq : 52|12@1+ (42370,-125) [-125|125.9375] "%" Vector__XXX

BO_ 2566593022 MG6IRP: 8 Vector__XXX
 SG_ MtrGnrtr6InvrtrLmtsRqstPwrCRC : 0|8@1+ (1,0) [0|255] "count" Vector__XXX
 SG_ MtrGnrtr6InvrtrLmtsRqstPwrCntr : 8|4@1+ (1,0) [0|15] "" Vector__XXX
 SG_ MtGt6IvtLtsRqstMPwMx : 12|12@1+ (42370,-125) [-125|125.9375] "%" Vector__XXX
 SG_ MtGt6IvtLtsRqstMPwM : 24|12@1+ (42370,-125) [-125|125.9375] "%" Vector__XXX
 SG_ MtGt6IvtLtsRqstDCSdPwMx : 36|12@1+ (42370,-125) [-125|125.9375] "%" Vector__XXX
 SG_ MtGt6IvtLtsRqstDCSdPwM : 48|12@1+ (42370,-125) [-125|125.9375] "%" Vector__XXX

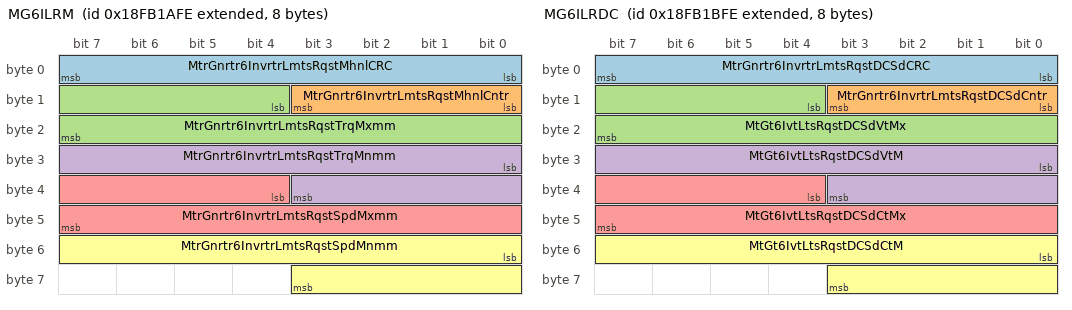
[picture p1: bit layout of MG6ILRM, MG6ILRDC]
BO_ 2566593278 MG6ILRM: 8 Vector__XXX
 SG_ MtrGnrtr6InvrtrLmtsRqstMhnlCRC : 0|8@1+ (1,0) [0|255] "count" Vector__XXX
 SG_ MtrGnrtr6InvrtrLmtsRqstMhnlCntr : 8|4@1+ (1,0) [0|15] "" Vector__XXX
 SG_ MtrGnrtr6InvrtrLmtsRqstTrqMxmm : 12|12@1+ (42370,-125) [-125|125.9375] "%" Vector__XXX
 SG_ MtrGnrtr6InvrtrLmtsRqstTrqMnmm : 24|12@1+ (42370,-125) [-125|125.9375] "%" Vector__XXX
 SG_ MtrGnrtr6InvrtrLmtsRqstSpdMxmm : 36|12@1+ (42370,-125) [-125|125.9375] "%" Vector__XXX
 SG_ MtrGnrtr6InvrtrLmtsRqstSpdMnmm : 48|12@1+ (42370,-125) [-125|125.9375] "%" Vector__XXX

BO_ 2566593534 MG6ILRDC: 8 Vector__XXX
 SG_ MtrGnrtr6InvrtrLmtsRqstDCSdCRC : 0|8@1+ (1,0) [0|255] "count" Vector__XXX
 SG_ MtrGnrtr6InvrtrLmtsRqstDCSdCntr : 8|4@1+ (1,0) [0|15] "" Vector__XXX
 SG_ MtGt6IvtLtsRqstDCSdVtMx : 12|12@1+ (42370,-125) [-125|125.9375] "%" Vector__XXX
 SG_ MtGt6IvtLtsRqstDCSdVtM : 24|12@1+ (42370,-125) [-125|125.9375] "%" Vector__XXX
 SG_ MtGt6IvtLtsRqstDCSdCtMx : 36|12@1+ (42370,-125) [-125|125.9375] "%" Vector__XXX
 SG_ MtGt6IvtLtsRqstDCSdCtM : 48|12@1+ (42370,-125) [-125|125.9375] "%" Vector__XXX

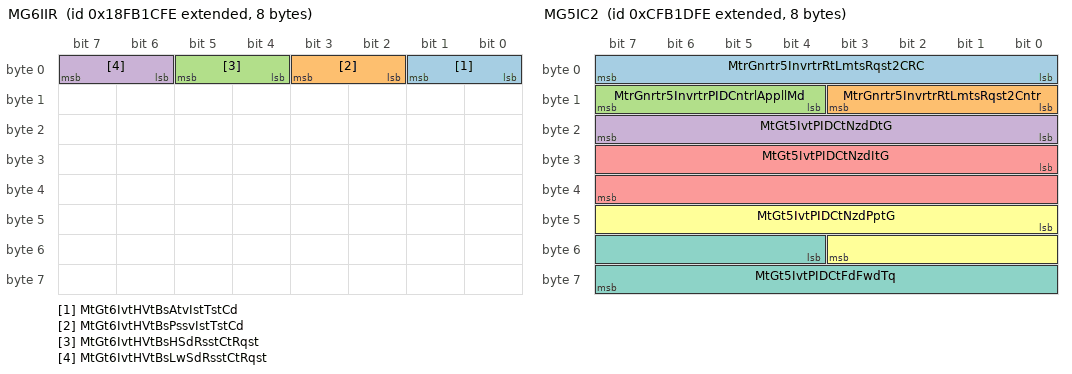
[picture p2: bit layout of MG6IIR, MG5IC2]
BO_ 2566593790 MG6IIR: 8 Vector__XXX
 SG_ MtGt6IvtHVtBsAtvIstTstCd : 0|2@1+ (1,0) [0|3] "" Vector__XXX
 SG_ MtGt6IvtHVtBsPssvIstTstCd : 2|2@1+ (1,0) [0|3] "" Vector__XXX
 SG_ MtGt6IvtHVtBsHSdRsstCtRqst : 4|2@1+ (1,0) [0|3] "" Vector__XXX
 SG_ MtGt6IvtHVtBsLwSdRsstCtRqst : 6|2@1+ (1,0) [0|3] "" Vector__XXX

BO_ 2365267454 MG5IC2: 8 Vector__XXX
 SG_ MtrGnrtr5InvrtrRtLmtsRqst2CRC : 0|8@1+ (1,0) [0|255] "count" Vector__XXX
 SG_ MtrGnrtr5InvrtrRtLmtsRqst2Cntr : 8|4@1+ (1,0) [0|15] "" Vector__XXX
 SG_ MtrGnrtr5InvrtrPIDCntrlAppllMd : 12|4@1+ (1,0) [0|15] "" Vector__XXX
 SG_ MtGt5IvtPIDCtNzdDtG : 16|8@1+ (11689,0) [0|7.8125] "%/(%/s)" Vector__XXX
 SG_ MtGt5IvtPIDCtNzdItG : 24|16@1+ (23377,0) [0|1003.984375] "%/(%/s)" Vector__XXX
 SG_ MtGt5IvtPIDCtNzdPptG : 40|12@1+ (42370,0) [0|250.9375] "%/%" Vector__XXX
 SG_ MtGt5IvtPIDCtFdFwdTq : 52|12@1+ (42370,-125) [-125|125.9375] "%" Vector__XXX

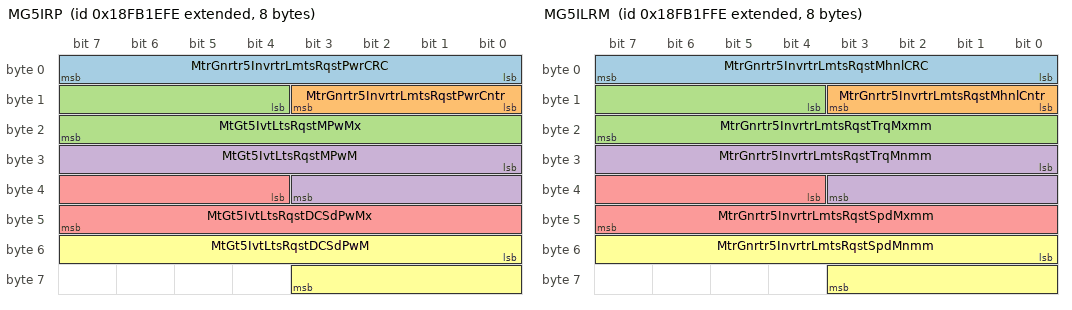
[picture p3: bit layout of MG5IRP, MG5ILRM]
BO_ 2566594302 MG5IRP: 8 Vector__XXX
 SG_ MtrGnrtr5InvrtrLmtsRqstPwrCRC : 0|8@1+ (1,0) [0|255] "count" Vector__XXX
 SG_ MtrGnrtr5InvrtrLmtsRqstPwrCntr : 8|4@1+ (1,0) [0|15] "" Vector__XXX
 SG_ MtGt5IvtLtsRqstMPwMx : 12|12@1+ (42370,-125) [-125|125.9375] "%" Vector__XXX
 SG_ MtGt5IvtLtsRqstMPwM : 24|12@1+ (42370,-125) [-125|125.9375] "%" Vector__XXX
 SG_ MtGt5IvtLtsRqstDCSdPwMx : 36|12@1+ (42370,-125) [-125|125.9375] "%" Vector__XXX
 SG_ MtGt5IvtLtsRqstDCSdPwM : 48|12@1+ (42370,-125) [-125|125.9375] "%" Vector__XXX

BO_ 2566594558 MG5ILRM: 8 Vector__XXX
 SG_ MtrGnrtr5InvrtrLmtsRqstMhnlCRC : 0|8@1+ (1,0) [0|255] "count" Vector__XXX
 SG_ MtrGnrtr5InvrtrLmtsRqstMhnlCntr : 8|4@1+ (1,0) [0|15] "" Vector__XXX
 SG_ MtrGnrtr5InvrtrLmtsRqstTrqMxmm : 12|12@1+ (42370,-125) [-125|125.9375] "%" Vector__XXX
 SG_ MtrGnrtr5InvrtrLmtsRqstTrqMnmm : 24|12@1+ (42370,-125) [-125|125.9375] "%" Vector__XXX
 SG_ MtrGnrtr5InvrtrLmtsRqstSpdMxmm : 36|12@1+ (42370,-125) [-125|125.9375] "%" Vector__XXX
 SG_ MtrGnrtr5InvrtrLmtsRqstSpdMnmm : 48|12@1+ (42370,-125) [-125|125.9375] "%" Vector__XXX

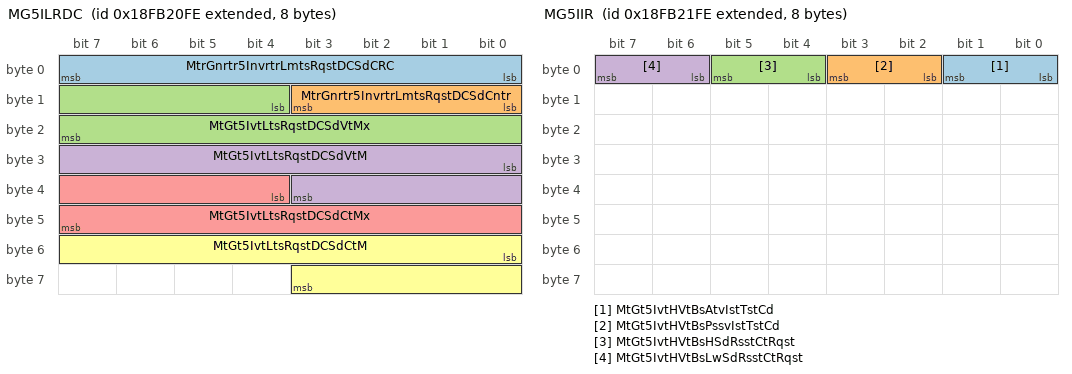
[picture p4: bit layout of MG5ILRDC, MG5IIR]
BO_ 2566594814 MG5ILRDC: 8 Vector__XXX
 SG_ MtrGnrtr5InvrtrLmtsRqstDCSdCRC : 0|8@1+ (1,0) [0|255] "count" Vector__XXX
 SG_ MtrGnrtr5InvrtrLmtsRqstDCSdCntr : 8|4@1+ (1,0) [0|15] "" Vector__XXX
 SG_ MtGt5IvtLtsRqstDCSdVtMx : 12|12@1+ (42370,-125) [-125|125.9375] "%" Vector__XXX
 SG_ MtGt5IvtLtsRqstDCSdVtM : 24|12@1+ (42370,-125) [-125|125.9375] "%" Vector__XXX
 SG_ MtGt5IvtLtsRqstDCSdCtMx : 36|12@1+ (42370,-125) [-125|125.9375] "%" Vector__XXX
 SG_ MtGt5IvtLtsRqstDCSdCtM : 48|12@1+ (42370,-125) [-125|125.9375] "%" Vector__XXX

BO_ 2566595070 MG5IIR: 8 Vector__XXX
 SG_ MtGt5IvtHVtBsAtvIstTstCd : 0|2@1+ (1,0) [0|3] "" Vector__XXX
 SG_ MtGt5IvtHVtBsPssvIstTstCd : 2|2@1+ (1,0) [0|3] "" Vector__XXX
 SG_ MtGt5IvtHVtBsHSdRsstCtRqst : 4|2@1+ (1,0) [0|3] "" Vector__XXX
 SG_ MtGt5IvtHVtBsLwSdRsstCtRqst : 6|2@1+ (1,0) [0|3] "" Vector__XXX

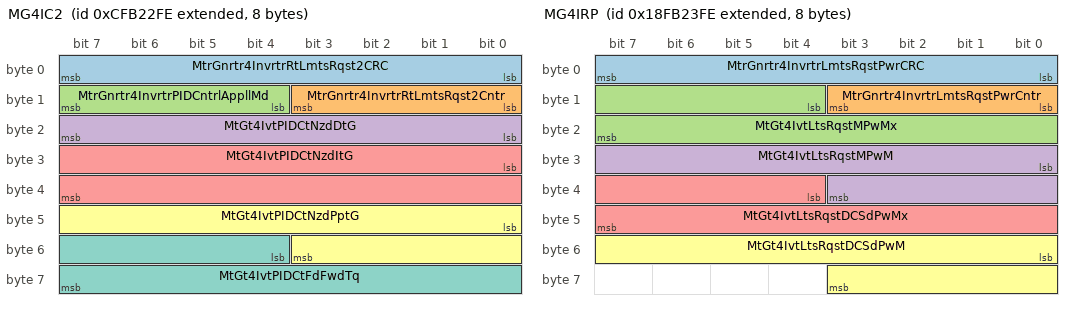
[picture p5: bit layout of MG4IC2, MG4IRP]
BO_ 2365268734 MG4IC2: 8 Vector__XXX
 SG_ MtrGnrtr4InvrtrRtLmtsRqst2CRC : 0|8@1+ (1,0) [0|255] "count" Vector__XXX
 SG_ MtrGnrtr4InvrtrRtLmtsRqst2Cntr : 8|4@1+ (1,0) [0|15] "" Vector__XXX
 SG_ MtrGnrtr4InvrtrPIDCntrlAppllMd : 12|4@1+ (1,0) [0|15] "" Vector__XXX
 SG_ MtGt4IvtPIDCtNzdDtG : 16|8@1+ (11689,0) [0|7.8125] "%/(%/s)" Vector__XXX
 SG_ MtGt4IvtPIDCtNzdItG : 24|16@1+ (23377,0) [0|1003.984375] "%/(%/s)" Vector__XXX
 SG_ MtGt4IvtPIDCtNzdPptG : 40|12@1+ (42370,0) [0|250.9375] "%/%" Vector__XXX
 SG_ MtGt4IvtPIDCtFdFwdTq : 52|12@1+ (42370,-125) [-125|125.9375] "%" Vector__XXX

BO_ 2566595582 MG4IRP: 8 Vector__XXX
 SG_ MtrGnrtr4InvrtrLmtsRqstPwrCRC : 0|8@1+ (1,0) [0|255] "count" Vector__XXX
 SG_ MtrGnrtr4InvrtrLmtsRqstPwrCntr : 8|4@1+ (1,0) [0|15] "" Vector__XXX
 SG_ MtGt4IvtLtsRqstMPwMx : 12|12@1+ (42370,-125) [-125|125.9375] "%" Vector__XXX
 SG_ MtGt4IvtLtsRqstMPwM : 24|12@1+ (42370,-125) [-125|125.9375] "%" Vector__XXX
 SG_ MtGt4IvtLtsRqstDCSdPwMx : 36|12@1+ (42370,-125) [-125|125.9375] "%" Vector__XXX
 SG_ MtGt4IvtLtsRqstDCSdPwM : 48|12@1+ (42370,-125) [-125|125.9375] "%" Vector__XXX

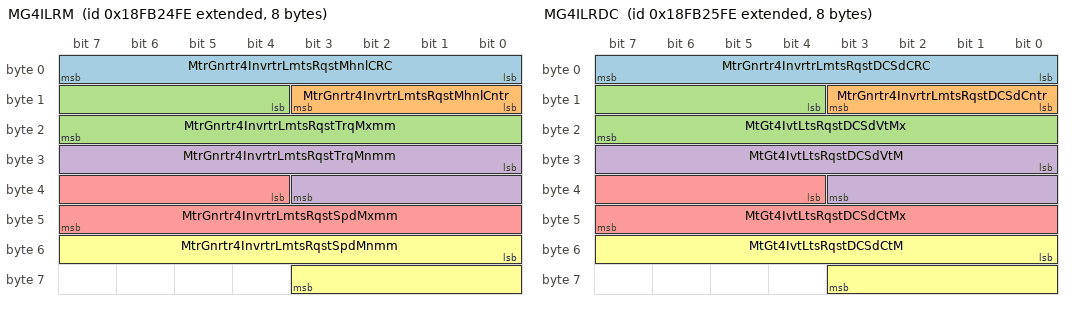
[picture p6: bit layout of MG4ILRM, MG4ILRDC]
BO_ 2566595838 MG4ILRM: 8 Vector__XXX
 SG_ MtrGnrtr4InvrtrLmtsRqstMhnlCRC : 0|8@1+ (1,0) [0|255] "count" Vector__XXX
 SG_ MtrGnrtr4InvrtrLmtsRqstMhnlCntr : 8|4@1+ (1,0) [0|15] "" Vector__XXX
 SG_ MtrGnrtr4InvrtrLmtsRqstTrqMxmm : 12|12@1+ (42370,-125) [-125|125.9375] "%" Vector__XXX
 SG_ MtrGnrtr4InvrtrLmtsRqstTrqMnmm : 24|12@1+ (42370,-125) [-125|125.9375] "%" Vector__XXX
 SG_ MtrGnrtr4InvrtrLmtsRqstSpdMxmm : 36|12@1+ (42370,-125) [-125|125.9375] "%" Vector__XXX
 SG_ MtrGnrtr4InvrtrLmtsRqstSpdMnmm : 48|12@1+ (42370,-125) [-125|125.9375] "%" Vector__XXX

BO_ 2566596094 MG4ILRDC: 8 Vector__XXX
 SG_ MtrGnrtr4InvrtrLmtsRqstDCSdCRC : 0|8@1+ (1,0) [0|255] "count" Vector__XXX
 SG_ MtrGnrtr4InvrtrLmtsRqstDCSdCntr : 8|4@1+ (1,0) [0|15] "" Vector__XXX
 SG_ MtGt4IvtLtsRqstDCSdVtMx : 12|12@1+ (42370,-125) [-125|125.9375] "%" Vector__XXX
 SG_ MtGt4IvtLtsRqstDCSdVtM : 24|12@1+ (42370,-125) [-125|125.9375] "%" Vector__XXX
 SG_ MtGt4IvtLtsRqstDCSdCtMx : 36|12@1+ (42370,-125) [-125|125.9375] "%" Vector__XXX
 SG_ MtGt4IvtLtsRqstDCSdCtM : 48|12@1+ (42370,-125) [-125|125.9375] "%" Vector__XXX

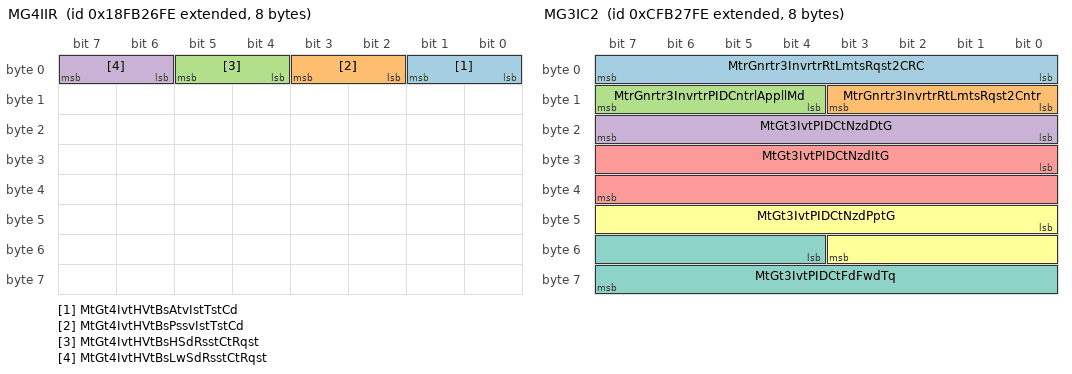
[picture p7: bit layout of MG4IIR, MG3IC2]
BO_ 2566596350 MG4IIR: 8 Vector__XXX
 SG_ MtGt4IvtHVtBsAtvIstTstCd : 0|2@1+ (1,0) [0|3] "" Vector__XXX
 SG_ MtGt4IvtHVtBsPssvIstTstCd : 2|2@1+ (1,0) [0|3] "" Vector__XXX
 SG_ MtGt4IvtHVtBsHSdRsstCtRqst : 4|2@1+ (1,0) [0|3] "" Vector__XXX
 SG_ MtGt4IvtHVtBsLwSdRsstCtRqst : 6|2@1+ (1,0) [0|3] "" Vector__XXX

BO_ 2365270014 MG3IC2: 8 Vector__XXX
 SG_ MtrGnrtr3InvrtrRtLmtsRqst2CRC : 0|8@1+ (1,0) [0|255] "count" Vector__XXX
 SG_ MtrGnrtr3InvrtrRtLmtsRqst2Cntr : 8|4@1+ (1,0) [0|15] "" Vector__XXX
 SG_ MtrGnrtr3InvrtrPIDCntrlAppllMd : 12|4@1+ (1,0) [0|15] "" Vector__XXX
 SG_ MtGt3IvtPIDCtNzdDtG : 16|8@1+ (11689,0) [0|7.8125] "%/(%/s)" Vector__XXX
 SG_ MtGt3IvtPIDCtNzdItG : 24|16@1+ (23377,0) [0|1003.984375] "%/(%/s)" Vector__XXX
 SG_ MtGt3IvtPIDCtNzdPptG : 40|12@1+ (42370,0) [0|250.9375] "%/%" Vector__XXX
 SG_ MtGt3IvtPIDCtFdFwdTq : 52|12@1+ (42370,-125) [-125|125.9375] "%" Vector__XXX

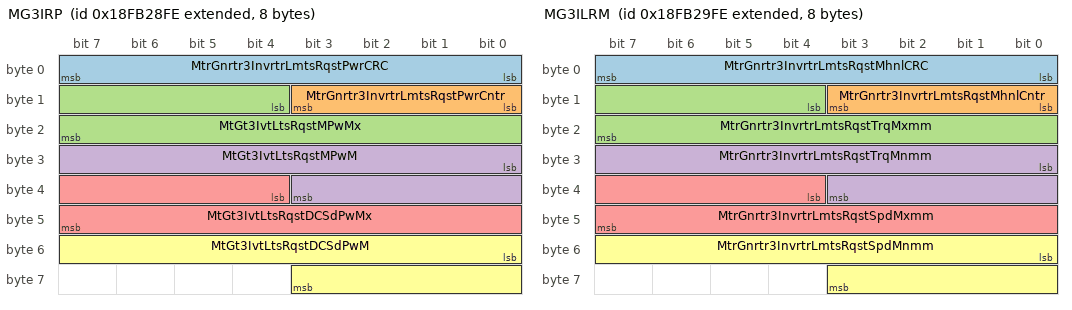
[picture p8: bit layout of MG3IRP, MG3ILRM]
BO_ 2566596862 MG3IRP: 8 Vector__XXX
 SG_ MtrGnrtr3InvrtrLmtsRqstPwrCRC : 0|8@1+ (1,0) [0|255] "count" Vector__XXX
 SG_ MtrGnrtr3InvrtrLmtsRqstPwrCntr : 8|4@1+ (1,0) [0|15] "" Vector__XXX
 SG_ MtGt3IvtLtsRqstMPwMx : 12|12@1+ (42370,-125) [-125|125.9375] "%" Vector__XXX
 SG_ MtGt3IvtLtsRqstMPwM : 24|12@1+ (42370,-125) [-125|125.9375] "%" Vector__XXX
 SG_ MtGt3IvtLtsRqstDCSdPwMx : 36|12@1+ (42370,-125) [-125|125.9375] "%" Vector__XXX
 SG_ MtGt3IvtLtsRqstDCSdPwM : 48|12@1+ (42370,-125) [-125|125.9375] "%" Vector__XXX

BO_ 2566597118 MG3ILRM: 8 Vector__XXX
 SG_ MtrGnrtr3InvrtrLmtsRqstMhnlCRC : 0|8@1+ (1,0) [0|255] "count" Vector__XXX
 SG_ MtrGnrtr3InvrtrLmtsRqstMhnlCntr : 8|4@1+ (1,0) [0|15] "" Vector__XXX
 SG_ MtrGnrtr3InvrtrLmtsRqstTrqMxmm : 12|12@1+ (42370,-125) [-125|125.9375] "%" Vector__XXX
 SG_ MtrGnrtr3InvrtrLmtsRqstTrqMnmm : 24|12@1+ (42370,-125) [-125|125.9375] "%" Vector__XXX
 SG_ MtrGnrtr3InvrtrLmtsRqstSpdMxmm : 36|12@1+ (42370,-125) [-125|125.9375] "%" Vector__XXX
 SG_ MtrGnrtr3InvrtrLmtsRqstSpdMnmm : 48|12@1+ (42370,-125) [-125|125.9375] "%" Vector__XXX

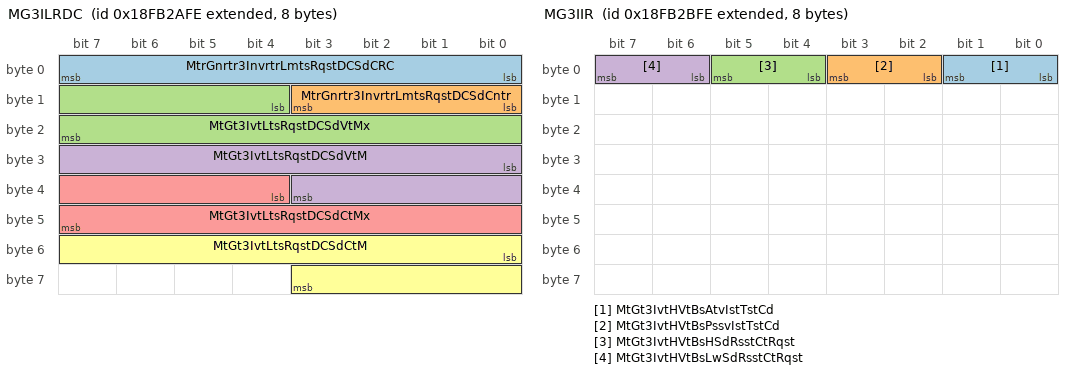
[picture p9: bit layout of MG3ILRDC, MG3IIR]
BO_ 2566597374 MG3ILRDC: 8 Vector__XXX
 SG_ MtrGnrtr3InvrtrLmtsRqstDCSdCRC : 0|8@1+ (1,0) [0|255] "count" Vector__XXX
 SG_ MtrGnrtr3InvrtrLmtsRqstDCSdCntr : 8|4@1+ (1,0) [0|15] "" Vector__XXX
 SG_ MtGt3IvtLtsRqstDCSdVtMx : 12|12@1+ (42370,-125) [-125|125.9375] "%" Vector__XXX
 SG_ MtGt3IvtLtsRqstDCSdVtM : 24|12@1+ (42370,-125) [-125|125.9375] "%" Vector__XXX
 SG_ MtGt3IvtLtsRqstDCSdCtMx : 36|12@1+ (42370,-125) [-125|125.9375] "%" Vector__XXX
 SG_ MtGt3IvtLtsRqstDCSdCtM : 48|12@1+ (42370,-125) [-125|125.9375] "%" Vector__XXX

BO_ 2566597630 MG3IIR: 8 Vector__XXX
 SG_ MtGt3IvtHVtBsAtvIstTstCd : 0|2@1+ (1,0) [0|3] "" Vector__XXX
 SG_ MtGt3IvtHVtBsPssvIstTstCd : 2|2@1+ (1,0) [0|3] "" Vector__XXX
 SG_ MtGt3IvtHVtBsHSdRsstCtRqst : 4|2@1+ (1,0) [0|3] "" Vector__XXX
 SG_ MtGt3IvtHVtBsLwSdRsstCtRqst : 6|2@1+ (1,0) [0|3] "" Vector__XXX

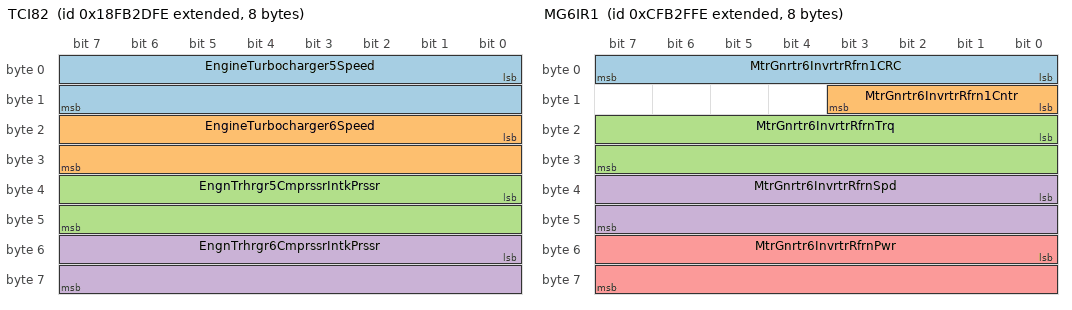
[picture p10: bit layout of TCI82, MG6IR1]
BO_ 2566598142 TCI82: 8 Vector__XXX
 SG_ EngineTurbocharger5Speed : 0|16@1+ (4,0) [0|257020] "rpm" Vector__XXX
 SG_ EngineTurbocharger6Speed : 16|16@1+ (4,0) [0|257020] "rpm" Vector__XXX
 SG_ EngnTrhrgr5CmprssrIntkPrssr : 32|16@1+ (0.0078125,-250) [-250|251.99] "kPa" Vector__XXX
 SG_ EngnTrhrgr6CmprssrIntkPrssr : 48|16@1+ (0.0078125,-250) [-250|251.99] "kPa" Vector__XXX

BO_ 2566598398 WINCH2: 8 Vector__XXX
 SG_ WinchLifetimeRevolutionCounter : 0|32@1+ (1,0) [0|4211081215] "count" Vector__XXX

BO_ 2365272062 MG6IR1: 8 Vector__XXX
 SG_ MtrGnrtr6InvrtrRfrn1CRC : 0|8@1+ (1,0) [0|255] "count" Vector__XXX
 SG_ MtrGnrtr6InvrtrRfrn1Cntr : 8|4@1+ (1,0) [0|15] "" Vector__XXX
 SG_ MtrGnrtr6InvrtrRfrnTrq : 16|16@1+ (0.5,0) [0|32127.5] "Nm" Vector__XXX
 SG_ MtrGnrtr6InvrtrRfrnSpd : 32|16@1+ (4,0) [0|257020] "rpm" Vector__XXX
 SG_ MtrGnrtr6InvrtrRfrnPwr : 48|16@1+ (0.0625,0) [0|4015.9375] "kW" Vector__XXX

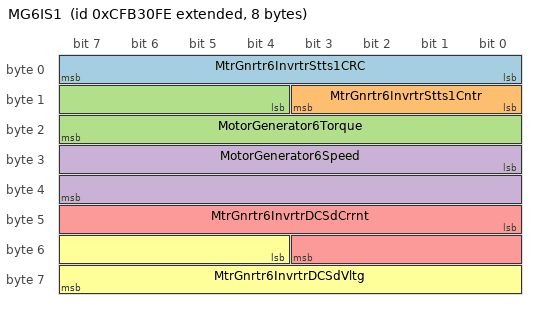
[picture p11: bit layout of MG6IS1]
BO_ 2365272318 MG6IS1: 8 Vector__XXX
 SG_ MtrGnrtr6InvrtrStts1CRC : 0|8@1+ (1,0) [0|255] "count" Vector__XXX
 SG_ MtrGnrtr6InvrtrStts1Cntr : 8|4@1+ (1,0) [0|15] "" Vector__XXX
 SG_ MotorGenerator6Torque : 12|12@1+ (42370,-125) [-125|125.9375] "%" Vector__XXX
 SG_ MotorGenerator6Speed : 24|16@1+ (0.00390625,-125) [-125|125.99609375] "%" Vector__XXX
 SG_ MtrGnrtr6InvrtrDCSdCrrnt : 40|12@1+ (42370,-125) [-125|125.9375] "%" Vector__XXX
 SG_ MtrGnrtr6InvrtrDCSdVltg : 52|12@1+ (42370,-125) [-125|125.9375] "%" Vector__XXX

CM_ BO_ 2566587390 "NOx Tracking Engine Activity Lifetime Engine Run Time Bins ";
CM_ SG_ 2566587390 NOxTEAtvtLtERTB1Tt "NOx Tracking Engine Activity Lifetime Engine Run Time Bin 1 (Total): Accumulated Engine run time regardless of NOx sensor status over the lifetime of the vehicle for Bin 1 [Note Bin 1 is the total of Bins 2-14]";
CM_ SG_ 2566587390 NOxTrkngEngnAtvtLftmEngnRnTmBn2 "NOx Tracking Engine Activity Lifetime Engine Run Time Bin 2 : Accumulated Engine run time regardless of NOx sensor status over the lifetime of the vehicle for Bin 2 [Note Bin 2 is the 'idle' bin]";
CM_ SG_ 2566587390 NOxTrkngEngnAtvtLftmEngnRnTmBn3 "NOx Tracking Engine Activity Lifetime Engine Run Time Bin 3 : Accumulated Engine run time regardless of NOx sensor status over the lifetime of the vehicle for Bin 3. ";
CM_ SG_ 2566587390 NOxTrkngEngnAtvtLftmEngnRnTmBn4 "NOx Tracking Engine Activity Lifetime Engine Run Time Bin 4: Accumulated Engine run time regardless of NOx sensor status over the lifetime of the vehicle for Bin 4.";
CM_ SG_ 2566587390 NOxTrkngEngnAtvtLftmEngnRnTmBn5 "NOx Tracking Engine Activity Lifetime Engine Run Time Bin 5: Accumulated Engine run time regardless of NOx sensor status over the lifetime of the vehicle for Bin 5.";
CM_ SG_ 2566587390 NOxTrkngEngnAtvtLftmEngnRnTmBn6 "NOx Tracking Engine Activity Lifetime Engine Run Time Bin 6: Accumulated Engine run time regardless of NOx sensor status over the lifetime of the vehicle for Bin 6. ";
CM_ SG_ 2566587390 NOxTrkngEngnAtvtLftmEngnRnTmBn7 "NOx Tracking Engine Activity Lifetime Engine Run Time Bin 7: Accumulated Engine run time regardless of NOx sensor status over the lifetime of the vehicle for Bin 7. ";
CM_ SG_ 2566587390 NOxTrkngEngnAtvtLftmEngnRnTmBn8 "NOx Tracking Engine Activity Lifetime Engine Run Time Bin 8: Accumulated Engine run time regardless of NOx sensor status over the lifetime of the vehicle for Bin 8. ";
CM_ SG_ 2566587390 NOxTrkngEngnAtvtLftmEngnRnTmBn9 "NOx Tracking Engine Activity Lifetime Engine Run Time Bin 9: Accumulated Engine run time regardless of NOx sensor status over the lifetime of the vehicle for Bin 9";
CM_ SG_ 2566587390 NOxTEAtvtLtERTB10 "NOx Tracking Engine Activity Lifetime Engine Run Time Bin 10: Accumulated Engine run time regardless of NOx sensor status over the lifetime of the vehicle for Bin 10";
CM_ SG_ 2566587390 NOxTEAtvtLtERTB11 "NOx Tracking Engine Activity Lifetime Engine Run Time Bin 11: Accumulated Engine run time regardless of NOx sensor status over the lifetime of the vehicle for Bin 11";
CM_ SG_ 2566587390 NOxTEAtvtLtERTB12 "NOx Tracking Engine Activity Lifetime Engine Run Time Bin 12: Accumulated Engine run time regardless of NOx sensor status over the lifetime of the vehicle for Bin 12";
CM_ SG_ 2566587390 NOxTEAtvtLtERTB13 "NOx Tracking Engine Activity Lifetime Engine Run Time Bin 13: Accumulated Engine run time regardless of NOx sensor status over the lifetime of the vehicle for Bin 13";
CM_ SG_ 2566587390 NOxTEAtvtLtERTB14 "NOx Tracking Engine Activity Lifetime Engine Run Time Bin 14 : Accumulated Engine run time regardless of NOx sensor status over the lifetime of the vehicle for Bin 14";
CM_ SG_ 2566587390 NOxTEAtvtLtERTB15NTEBIN "NOx Tracking Engine Activity Lifetime Engine Run Time Bin 15 (NTE BIN): Accumulated Engine run time regardless of NOx sensor status over the lifetime of the vehicle for Bin 15 [Note Bin 15 is the NTE Bin]";
CM_ SG_ 2566587390 NOxTEAtvtLtERTB16RB "NOx Tracking Engine Activity Lifetime Engine Run Time Bin 16 (Regen Bin) : Accumulated Engine run time regardless of NOx sensor status over the lifetime of the vehicle for Bin 16 [Note Bin 16 is the Regen Bin]";
CM_ SG_ 2566587390 NOxTEAtvtLtERTB17MILOB "NOx Tracking Engine Activity Lifetime Engine Run Time Bin 17 (MIL On Bin): Accumulated Engine run time regardless of NOx sensor status over the lifetime of the vehicle for Bin 17 [Note Bin 17 is the MIL On Bin].";
CM_ BO_ 2566587646 "NOx Tracking Engine Activity Lifetime Vehicle Distance Bins ";
CM_ SG_ 2566587646 NOxTEAtvtLtVDstB1Tt "NOx Tracking Engine Activity Lifetime Vehicle Distance Bin 1 (Total): Accumulated Vehicle distance regardless of NOx sensor status over the lifetime of the vehicle for Bin 1 [Note Bin 1 is the total of Bins 2-14]";
CM_ SG_ 2566587646 NOxTrkngEngnAtvtLftmVhlDstnBn2 "NOx Tracking Engine Activity Lifetime Vehicle Distance Bin 2 : Accumulated Vehicle distance regardless of NOx sensor status over the lifetime of the vehicle for Bin 2 [Note Bin 2 is the 'idle' bin]";
CM_ SG_ 2566587646 NOxTrkngEngnAtvtLftmVhlDstnBn3 "NOx Tracking Engine Activity Lifetime Vehicle Distance Bin 3 : Accumulated Vehicle distance regardless of NOx sensor status over the lifetime of the vehicle for Bin 3.";
CM_ SG_ 2566587646 NOxTrkngEngnAtvtLftmVhlDstnBn4 "NOx Tracking Engine Activity Lifetime Vehicle Distance Bin 4: Accumulated Vehicle distance regardless of NOx sensor status over the lifetime of the vehicle for Bin 4.";
CM_ SG_ 2566587646 NOxTrkngEngnAtvtLftmVhlDstnBn5 "NOx Tracking Engine Activity Lifetime Vehicle Distance Bin 5: Accumulated Vehicle distance regardless of NOx sensor status over the lifetime of the vehicle for Bin 5.";
CM_ SG_ 2566587646 NOxTrkngEngnAtvtLftmVhlDstnBn6 "NOx Tracking Engine Activity Lifetime Vehicle Distance Bin 6: Accumulated Vehicle distance regardless of NOx sensor status over the lifetime of the vehicle for Bin 6. ";
CM_ SG_ 2566587646 NOxTrkngEngnAtvtLftmVhlDstnBn7 "NOx Tracking Engine Activity Lifetime Vehicle Distance Bin 7: Accumulated Vehicle distance regardless of NOx sensor status over the lifetime of the vehicle for Bin 7. ";
CM_ SG_ 2566587646 NOxTrkngEngnAtvtLftmVhlDstnBn8 "NOx Tracking Engine Activity Lifetime Vehicle Distance Bin 8: Accumulated Vehicle distance regardless of NOx sensor status over the lifetime of the vehicle for Bin 8. ";
CM_ SG_ 2566587646 NOxTrkngEngnAtvtLftmVhlDstnBn9 "NOx Tracking Engine Activity Lifetime Vehicle Distance Bin 9: Accumulated Vehicle distance regardless of NOx sensor status over the lifetime of the vehicle for Bin 9";
CM_ SG_ 2566587646 NOxTrkngEngnAtvtLftmVhlDstnBn10 "NOx Tracking Engine Activity Lifetime Vehicle Distance Bin 10: Accumulated Vehicle distance regardless of NOx sensor status over the lifetime of the vehicle for Bin 10";
CM_ SG_ 2566587646 NOxTrkngEngnAtvtLftmVhlDstnBn11 "NOx Tracking Engine Activity Lifetime Vehicle Distance Bin 11: Accumulated Vehicle distance regardless of NOx sensor status over the lifetime of the vehicle for Bin 11";
CM_ SG_ 2566587646 NOxTrkngEngnAtvtLftmVhlDstnBn12 "NOx Tracking Engine Activity Lifetime Vehicle Distance Bin 12: Accumulated Vehicle distance regardless of NOx sensor status over the lifetime of the vehicle for Bin 12";
CM_ SG_ 2566587646 NOxTrkngEngnAtvtLftmVhlDstnBn13 "NOx Tracking Engine Activity Lifetime Vehicle Distance Bin 13: Accumulated Vehicle distance regardless of NOx sensor status over the lifetime of the vehicle for Bin 13";
CM_ SG_ 2566587646 NOxTrkngEngnAtvtLftmVhlDstnBn14 "NOx Tracking Engine Activity Lifetime Vehicle Distance Bin 14 : Accumulated Vehicle distance regardless of NOx sensor status over the lifetime of the vehicle for Bin 14";
CM_ SG_ 2566587646 NOxTEAtvtLtVDstB15NTEBIN "NOx Tracking Engine Activity Lifetime Vehicle Distance Bin 15 (NTE BIN): Accumulated Vehicle distance regardless of NOx sensor status over the lifetime of the vehicle for Bin 15 [Note Bin 15 is the NTE Bin]";
CM_ SG_ 2566587646 NOxTEAtvtLtVDstB16RB "NOx Tracking Engine Activity Lifetime Vehicle Distance Bin 16 (Regen Bin) : Accumulated Vehicle distance regardless of NOx sensor status over the lifetime of the vehicle for Bin 16 [Note Bin 16 is the Regen Bin]";
CM_ SG_ 2566587646 NOxTEAtvtLtVDstB17MILOB "NOx Tracking Engine Activity Lifetime Vehicle Distance Bin 17 (MIL On Bin): Accumulated Vehicle distance regardless of NOx sensor status over the lifetime of the vehicle for Bin 17 [Note Bin 17 is the MIL On Bin].";
CM_ BO_ 2566587902 "NOx Tracking Engine Activity Lifetime Engine Output Energy Bins ";
CM_ SG_ 2566587902 NOxTEAtvtLtEOtptEB1Tt "NOx Tracking Engine Activity Lifetime Engine Output Energy Bin 1 (Total) : Accumulated Engine output energy regardless of NOx sensor status over the lifetime of the vehicle for Bin 1 [Note Bin 1 is the total of bins 2-14]";
CM_ SG_ 2566587902 NOxTEAtvtLtEOtptEB2 "NOx Tracking Engine Activity Lifetime Engine Output Energy Bin 2 : Accumulated Engine output energy regardless of NOx sensor status over the lifetime of the vehicle for Bin 2 [Note Bin 2 is the 'idle' bin]";
CM_ SG_ 2566587902 NOxTEAtvtLtEOtptEB3 "NOx Tracking Engine Activity Lifetime Engine Output Energy Bin 3 : Accumulated Engine output energy regardless of NOx sensor status over the lifetime of the vehicle for Bin 3.";
CM_ SG_ 2566587902 NOxTEAtvtLtEOtptEB4 "NOx Tracking Engine Activity Lifetime Engine Output Energy Bin 4: Accumulated Engine output energy regardless of NOx sensor status over the lifetime of the vehicle for Bin 4. ";
CM_ SG_ 2566587902 NOxTEAtvtLtEOtptEB5 "NOx Tracking Engine Activity Lifetime Engine Output Energy Bin 5: Accumulated Engine output energy regardless of NOx sensor status over the lifetime of the vehicle for Bin 5.";
CM_ SG_ 2566587902 NOxTEAtvtLtEOtptEB6 "NOx Tracking Engine Activity Lifetime Engine Output Energy Bin 6: Accumulated Engine output energy regardless of NOx sensor status over the lifetime of the vehicle for Bin 6. ";
CM_ SG_ 2566587902 NOxTEAtvtLtEOtptEB7 "NOx Tracking Engine Activity Lifetime Engine Output Energy Bin 7: Accumulated Engine output energy regardless of NOx sensor status over the lifetime of the vehicle for Bin 7. ";
CM_ SG_ 2566587902 NOxTEAtvtLtEOtptEB8 "NOx Tracking Engine Activity Lifetime Engine Output Energy Bin 8: Accumulated Engine output energy regardless of NOx sensor status over the lifetime of the vehicle for Bin 8. ";
CM_ SG_ 2566587902 NOxTEAtvtLtEOtptEB9 "NOx Tracking Engine Activity Lifetime Engine Output Energy Bin 9: Accumulated Engine output energy regardless of NOx sensor status over the lifetime of the vehicle for Bin 9";
CM_ SG_ 2566587902 NOxTEAtvtLtEOtptEB10 "NOx Tracking Engine Activity Lifetime Engine Output Energy Bin 10: Accumulated Engine output energy regardless of NOx sensor status over the lifetime of the vehicle for Bin 10";
CM_ SG_ 2566587902 NOxTEAtvtLtEOtptEB11 "NOx Tracking Engine Activity Lifetime Engine Output Energy Bin 11: Accumulated Engine output energy regardless of NOx sensor status over the lifetime of the vehicle for Bin 11";
CM_ SG_ 2566587902 NOxTEAtvtLtEOtptEB12 "NOx Tracking Engine Activity Lifetime Engine Output Energy Bin 12: Accumulated Engine output energy regardless of NOx sensor status over the lifetime of the vehicle for Bin 12";
CM_ SG_ 2566587902 NOxTEAtvtLtEOtptEB13 "NOx Tracking Engine Activity Lifetime Engine Output Energy Bin 13: Accumulated Engine output energy regardless of NOx sensor status over the lifetime of the vehicle for Bin 13";
CM_ SG_ 2566587902 NOxTEAtvtLtEOtptEB14 "NOx Tracking Engine Activity Lifetime Engine Output Energy Bin 14 : Accumulated Engine output energy regardless of NOx sensor status over the lifetime of the vehicle for Bin 14";
CM_ SG_ 2566587902 NOxTEAtvtLtEOtptEB15NTEBIN "NOx Tracking Engine Activity Lifetime Engine Output Energy Bin 15 (NTE BIN): Accumulated Engine output energy regardless of NOx sensor status over the lifetime of the vehicle for Bin 15 [Note Bin 15 is the NTE Bin]";
CM_ SG_ 2566587902 NOxTEAtvtLtEOtptEB16RB "NOx Tracking Engine Activity Lifetime Engine Output Energy Bin 16 (Regen Bin) : Accumulated Engine output energy regardless of NOx sensor status over the lifetime of the vehicle for Bin 16 [Note Bin 16 is the Regen Bin]";
CM_ SG_ 2566587902 NOxTEAtvtLtEOtptEB17MILOB "NOx Tracking Engine Activity Lifetime Engine Output Energy Bin 17 (MIL On Bin): Accumulated Engine output energy regardless of NOx sensor status over the lifetime of the vehicle for Bin 17 [Note Bin 17 is the MIL On Bin].";
CM_ BO_ 2566588158 "NOx Tracking Valid NOx Lifetime Fuel Consumption Bins ";
CM_ SG_ 2566588158 NOxTVdNOxLtFCsptB1Tt "NOx Tracking Valid NOx Lifetime Fuel Consumption Bin 1 (Total): Accumulated Fuel consumption while all NOx sensors are active over the lifetime of the vehicle for Bin 1 [Note Bin 1 is the total of Bins 2-14]";
CM_ SG_ 2566588158 NOxTrkngVldNOxLftmFlCnsmptnBn2 "NOx Tracking Valid NOx Lifetime Fuel Consumption Bin 2 : Accumulated Fuel consumption while all NOx sensors are active over the lifetime of the vehicle for Bin 2 [Note Bin 2 is the 'idle' bin]";
CM_ SG_ 2566588158 NOxTrkngVldNOxLftmFlCnsmptnBn3 "NOx Tracking Valid NOx Lifetime Fuel Consumption Bin 3 : Accumulated Fuel consumption while all NOx sensors are active over the lifetime of the vehicle for Bin 3. ";
CM_ SG_ 2566588158 NOxTrkngVldNOxLftmFlCnsmptnBn4 "NOx Tracking Valid NOx Lifetime Fuel Consumption Bin 4: Accumulated Fuel consumption while all NOx sensors are active over the lifetime of the vehicle for Bin 4. ";
CM_ SG_ 2566588158 NOxTrkngVldNOxLftmFlCnsmptnBn5 "NOx Tracking Valid NOx Lifetime Fuel Consumption Bin 5: Accumulated Fuel consumption while all NOx sensors are active over the lifetime of the vehicle for Bin 5.";
CM_ SG_ 2566588158 NOxTrkngVldNOxLftmFlCnsmptnBn6 "NOx Tracking Valid NOx Lifetime Fuel Consumption Bin 6: Accumulated Fuel consumption while all NOx sensors are active over the lifetime of the vehicle for Bin 6. ";
CM_ SG_ 2566588158 NOxTrkngVldNOxLftmFlCnsmptnBn7 "NOx Tracking Valid NOx Lifetime Fuel Consumption Bin 7: Accumulated Fuel consumption while all NOx sensors are active over the lifetime of the vehicle for Bin 7. ";
CM_ SG_ 2566588158 NOxTrkngVldNOxLftmFlCnsmptnBn8 "NOx Tracking Valid NOx Lifetime Fuel Consumption Bin 8: Accumulated Fuel consumption while all NOx sensors are active over the lifetime of the vehicle for Bin 8. ";
CM_ SG_ 2566588158 NOxTrkngVldNOxLftmFlCnsmptnBn9 "NOx Tracking Valid NOx Lifetime Fuel Consumption Bin 9: Accumulated Fuel consumption while all NOx sensors are active over the lifetime of the vehicle for Bin 9";
CM_ SG_ 2566588158 NOxTrkngVldNOxLftmFlCnsmptnBn10 "NOx Tracking Valid NOx Lifetime Fuel Consumption Bin 10: Accumulated Fuel consumption while all NOx sensors are active over the lifetime of the vehicle for Bin 10";
CM_ SG_ 2566588158 NOxTrkngVldNOxLftmFlCnsmptnBn11 "NOx Tracking Valid NOx Lifetime Fuel Consumption Bin 11: Accumulated Fuel consumption while all NOx sensors are active over the lifetime of the vehicle for Bin 11";
CM_ SG_ 2566588158 NOxTrkngVldNOxLftmFlCnsmptnBn12 "NOx Tracking Valid NOx Lifetime Fuel Consumption Bin 12: Accumulated Fuel consumption while all NOx sensors are active over the lifetime of the vehicle for Bin 12";
CM_ SG_ 2566588158 NOxTrkngVldNOxLftmFlCnsmptnBn13 "NOx Tracking Valid NOx Lifetime Fuel Consumption Bin 13: Accumulated Fuel consumption while all NOx sensors are active over the lifetime of the vehicle for Bin 13";
CM_ SG_ 2566588158 NOxTrkngVldNOxLftmFlCnsmptnBn14 "NOx Tracking Valid NOx Lifetime Fuel Consumption Bin 14 : Accumulated Fuel consumption while all NOx sensors are active over the lifetime of the vehicle for Bin 14";
CM_ SG_ 2566588158 NOxTVdNOxLtFCsptB15NTEBIN "NOx Tracking Valid NOx Lifetime Fuel Consumption Bin 15 (NTE BIN) : Accumulated Fuel consumption while all NOx sensors are active over the lifetime of the vehicle for Bin 15 [Note Bin 15 is the NTE Bin]";
CM_ SG_ 2566588158 NOxTVdNOxLtFCsptB16RB "NOx Tracking Valid NOx Lifetime Fuel Consumption Bin 16 (Regen Bin) : Accumulated Fuel consumption while all NOx sensors are active over the lifetime of the vehicle for Bin 16 [Note Bin 16 is the Regen Bin]";
CM_ SG_ 2566588158 NOxTVdNOxLtFCsptB17MILOB "NOx Tracking Valid NOx Lifetime Fuel Consumption Bin 17 (MIL On Bin) : Accumulated Fuel consumption while all NOx sensors are active over the lifetime of the vehicle for Bin 17 [Note Bin 17 is the MIL On Bin]";
CM_ BO_ 2566588414 "NOx Tracking Valid NOx Lifetime Engine Run Time Bins ";
CM_ SG_ 2566588414 NOxTVdNOxLtERTB1Tt "NOx Tracking Valid NOx Lifetime Engine Run Time Bin 1 (Total): Accumulated Engine run time while all NOx sensors are active over the lifetime of the vehicle for Bin 1 [Note Bin 1 is the total of Bins 2-14]";
CM_ SG_ 2566588414 NOxTrkngVldNOxLftmEngnRnTmBn2 "NOx Tracking Valid NOx Lifetime Engine Run Time Bin 2 : Accumulated Engine run time while all NOx sensors are active over the lifetime of the vehicle for Bin 2 [Note Bin 2 is the 'idle' bin]";
CM_ SG_ 2566588414 NOxTrkngVldNOxLftmEngnRnTmBn3 "NOx Tracking Valid NOx Lifetime Engine Run Time Bin 3 : Accumulated Engine run time while all NOx sensors are active over the lifetime of the vehicle for Bin 3. ";
CM_ SG_ 2566588414 NOxTrkngVldNOxLftmEngnRnTmBn4 "NOx Tracking Valid NOx Lifetime Engine Run Time Bin 4: Accumulated Engine run time while all NOx sensors are active over the lifetime of the vehicle for Bin 4.";
CM_ SG_ 2566588414 NOxTrkngVldNOxLftmEngnRnTmBn5 "NOx Tracking Valid NOx Lifetime Engine Run Time Bin 5: Accumulated Engine run time while all NOx sensors are active over the lifetime of the vehicle for Bin 5.";
CM_ SG_ 2566588414 NOxTrkngVldNOxLftmEngnRnTmBn6 "NOx Tracking Valid NOx Lifetime Engine Run Time Bin 6: Accumulated Engine run time while all NOx sensors are active over the lifetime of the vehicle for Bin 6. ";
CM_ SG_ 2566588414 NOxTrkngVldNOxLftmEngnRnTmBn7 "NOx Tracking Valid NOx Lifetime Engine Run Time Bin 7: Accumulated Engine run time while all NOx sensors are active over the lifetime of the vehicle for Bin 7. ";
CM_ SG_ 2566588414 NOxTrkngVldNOxLftmEngnRnTmBn8 "NOx Tracking Valid NOx Lifetime Engine Run Time Bin 8: Accumulated Engine run time while all NOx sensors are active over the lifetime of the vehicle for Bin 8. ";
CM_ SG_ 2566588414 NOxTrkngVldNOxLftmEngnRnTmBn9 "NOx Tracking Valid NOx Lifetime Engine Run Time Bin 9: Accumulated Engine run time while all NOx sensors are active over the lifetime of the vehicle for Bin 9";
CM_ SG_ 2566588414 NOxTrkngVldNOxLftmEngnRnTmBn10 "NOx Tracking Valid NOx Lifetime Engine Run Time Bin 10: Accumulated Engine run time while all NOx sensors are active over the lifetime of the vehicle for Bin 10";
CM_ SG_ 2566588414 NOxTrkngVldNOxLftmEngnRnTmBn11 "NOx Tracking Valid NOx Lifetime Engine Run Time Bin 11: Accumulated Engine run time while all NOx sensors are active over the lifetime of the vehicle for Bin 11";
CM_ SG_ 2566588414 NOxTrkngVldNOxLftmEngnRnTmBn12 "NOx Tracking Valid NOx Lifetime Engine Run Time Bin 12: Accumulated Engine run time while all NOx sensors are active over the lifetime of the vehicle for Bin 12";
CM_ SG_ 2566588414 NOxTrkngVldNOxLftmEngnRnTmBn13 "NOx Tracking Valid NOx Lifetime Engine Run Time Bin 13: Accumulated Engine run time while all NOx sensors are active over the lifetime of the vehicle for Bin 13";
CM_ SG_ 2566588414 NOxTrkngVldNOxLftmEngnRnTmBn14 "NOx Tracking Valid NOx Lifetime Engine Run Time Bin 14 : Accumulated Engine run time while all NOx sensors are active over the lifetime of the vehicle for Bin 14";
CM_ SG_ 2566588414 NOxTVdNOxLtERTB15NTEBIN "NOx Tracking Valid NOx Lifetime Engine Run Time Bin 15 (NTE BIN) : Accumulated Engine run time while all NOx sensors are active over the lifetime of the vehicle for Bin 15 [Note Bin 15 is the NTE Bin]";
CM_ SG_ 2566588414 NOxTVdNOxLtERTB16RB "NOx Tracking Valid NOx Lifetime Engine Run Time Bin 16 (Regen Bin) : Accumulated Engine run time while all NOx sensors are active over the lifetime of the vehicle for Bin 16 [Note Bin 16 is the Regen Bin]";
CM_ SG_ 2566588414 NOxTVdNOxLtERTB17MILOB "NOx Tracking Valid NOx Lifetime Engine Run Time Bin 17 (MIL On Bin) : Accumulated Engine run time while all NOx sensors are active over the lifetime of the vehicle for Bin 17 [Note Bin 17 is the MIL On Bin]";
CM_ BO_ 2566588670 "NOx Tracking Valid NOx Lifetime Vehicle Distance Bins ";
CM_ SG_ 2566588670 NOxTrkngVldNOxLftmVhlDstnBn1Ttl "NOx Tracking Valid NOx Lifetime Vehicle Distance Bin 1 (Total): Accumulated Vehicle distance while all NOx sensors are active over the lifetime of the vehicle for Bin 1 [Note Bin 1 is the total of Bins 2-14]";
CM_ SG_ 2566588670 NOxTrkngVldNOxLftmVhlDstnBn2 "NOx Tracking Valid NOx Lifetime Vehicle Distance Bin 2 : Accumulated Vehicle distance while all NOx sensors are active over the lifetime of the vehicle for Bin 2 [Note Bin 2 is the 'idle' bin]";
CM_ SG_ 2566588670 NOxTrkngVldNOxLftmVhlDstnBn3 "NOx Tracking Valid NOx Lifetime Vehicle Distance Bin 3 : Accumulated Vehicle distance while all NOx sensors are active over the lifetime of the vehicle for Bin 3. ";
CM_ SG_ 2566588670 NOxTrkngVldNOxLftmVhlDstnBn4 "NOx Tracking Valid NOx Lifetime Vehicle Distance Bin 4: Accumulated Vehicle distance while all NOx sensors are active over the lifetime of the vehicle for Bin 4.";
CM_ SG_ 2566588670 NOxTrkngVldNOxLftmVhlDstnBn5 "NOx Tracking Valid NOx Lifetime Vehicle Distance Bin 5: Accumulated Vehicle distance while all NOx sensors are active over the lifetime of the vehicle for Bin 5.";
CM_ SG_ 2566588670 NOxTrkngVldNOxLftmVhlDstnBn6 "NOx Tracking Valid NOx Lifetime Vehicle Distance Bin 6: Accumulated Vehicle distance while all NOx sensors are active over the lifetime of the vehicle for Bin 6. ";
CM_ SG_ 2566588670 NOxTrkngVldNOxLftmVhlDstnBn7 "NOx Tracking Valid NOx Lifetime Vehicle Distance Bin 7: Accumulated Vehicle distance while all NOx sensors are active over the lifetime of the vehicle for Bin 7. ";
CM_ SG_ 2566588670 NOxTrkngVldNOxLftmVhlDstnBn8 "NOx Tracking Valid NOx Lifetime Vehicle Distance Bin 8: Accumulated Vehicle distance while all NOx sensors are active over the lifetime of the vehicle for Bin 8. ";
CM_ SG_ 2566588670 NOxTrkngVldNOxLftmVhlDstnBn9 "NOx Tracking Valid NOx Lifetime Vehicle Distance Bin 9: Accumulated Vehicle distance while all NOx sensors are active over the lifetime of the vehicle for Bin 9";
CM_ SG_ 2566588670 NOxTrkngVldNOxLftmVhlDstnBn10 "NOx Tracking Valid NOx Lifetime Vehicle Distance Bin 10: Accumulated Vehicle distance while all NOx sensors are active over the lifetime of the vehicle for Bin 10";
CM_ SG_ 2566588670 NOxTrkngVldNOxLftmVhlDstnBn11 "NOx Tracking Valid NOx Lifetime Vehicle Distance Bin 11: Accumulated Vehicle distance while all NOx sensors are active over the lifetime of the vehicle for Bin 11";
CM_ SG_ 2566588670 NOxTrkngVldNOxLftmVhlDstnBn12 "NOx Tracking Valid NOx Lifetime Vehicle Distance Bin 12: Accumulated Vehicle distance while all NOx sensors are active over the lifetime of the vehicle for Bin 12";
CM_ SG_ 2566588670 NOxTrkngVldNOxLftmVhlDstnBn13 "NOx Tracking Valid NOx Lifetime Vehicle Distance Bin 13: Accumulated Vehicle distance while all NOx sensors are active over the lifetime of the vehicle for Bin 13";
CM_ SG_ 2566588670 NOxTrkngVldNOxLftmVhlDstnBn14 "NOx Tracking Valid NOx Lifetime Vehicle Distance Bin 14 : Accumulated Vehicle distance while all NOx sensors are active over the lifetime of the vehicle for Bin 14";
CM_ SG_ 2566588670 NOxTVdNOxLtVDstB15NTEBIN "NOx Tracking Valid NOx Lifetime Vehicle Distance Bin 15 (NTE BIN) : Accumulated Vehicle distance while all NOx sensors are active over the lifetime of the vehicle for Bin 15 [Note Bin 15 is the NTE Bin]";
CM_ SG_ 2566588670 NOxTVdNOxLtVDstB16RB "NOx Tracking Valid NOx Lifetime Vehicle Distance Bin 16 (Regen Bin) : Accumulated Vehicle distance while all NOx sensors are active over the lifetime of the vehicle for Bin 16 [Note Bin 16 is the Regen Bin]";
CM_ SG_ 2566588670 NOxTVdNOxLtVDstB17MILOB "NOx Tracking Valid NOx Lifetime Vehicle Distance Bin 17 (MIL On Bin) : Accumulated Vehicle distance while all NOx sensors are active over the lifetime of the vehicle for Bin 17 [Note Bin 17 is the MIL On Bin]";
CM_ BO_ 2566588926 "NOx Tracking Valid NOx Lifetime Engine Output Energy Bins ";
CM_ SG_ 2566588926 NOxTVdNOxLtEOtptEB1Tt "NOx Tracking Valid NOx Lifetime Engine Output Energy Bin 1 (Total): Accumulated Engine output energy while all NOx sensors are active over the lifetime of the vehicle for Bin 1 [Note Bin 1 is the total of Bins 2-14]";
CM_ SG_ 2566588926 NOxTVdNOxLtEOtptEB2 "NOx Tracking Valid NOx Lifetime Engine Output Energy Bin 2 : Accumulated Engine output energy while all NOx sensors are active over the lifetime of the vehicle for Bin 2 [Note Bin 2 is the 'idle' bin]";
CM_ SG_ 2566588926 NOxTVdNOxLtEOtptEB3 "NOx Tracking Valid NOx Lifetime Engine Output Energy Bin 3 : Accumulated Engine output energy while all NOx sensors are active over the lifetime of the vehicle for Bin 3.";
CM_ SG_ 2566588926 NOxTVdNOxLtEOtptEB4 "NOx Tracking Valid NOx Lifetime Engine Output Energy Bin 4: Accumulated Engine output energy while all NOx sensors are active over the lifetime of the vehicle for Bin 4. ";
CM_ SG_ 2566588926 NOxTVdNOxLtEOtptEB5 "NOx Tracking Valid NOx Lifetime Engine Output Energy Bin 5: Accumulated Engine output energy while all NOx sensors are active over the lifetime of the vehicle for Bin 5.";
CM_ SG_ 2566588926 NOxTVdNOxLtEOtptEB6 "NOx Tracking Valid NOx Lifetime Engine Output Energy Bin 6: Accumulated Engine output energy while all NOx sensors are active over the lifetime of the vehicle for Bin 6. ";
CM_ SG_ 2566588926 NOxTVdNOxLtEOtptEB7 "NOx Tracking Valid NOx Lifetime Engine Output Energy Bin 7: Accumulated Engine output energy while all NOx sensors are active over the lifetime of the vehicle for Bin 7. ";
CM_ SG_ 2566588926 NOxTVdNOxLtEOtptEB8 "NOx Tracking Valid NOx Lifetime Engine Output Energy Bin 8: Accumulated Engine output energy while all NOx sensors are active over the lifetime of the vehicle for Bin 8. ";
CM_ SG_ 2566588926 NOxTVdNOxLtEOtptEB9 "NOx Tracking Valid NOx Lifetime Engine Output Energy Bin 9: Accumulated Engine output energy while all NOx sensors are active over the lifetime of the vehicle for Bin 9";
CM_ SG_ 2566588926 NOxTVdNOxLtEOtptEB10 "NOx Tracking Valid NOx Lifetime Engine Output Energy Bin 10: Accumulated Engine output energy while all NOx sensors are active over the lifetime of the vehicle for Bin 10";
CM_ SG_ 2566588926 NOxTVdNOxLtEOtptEB11 "NOx Tracking Valid NOx Lifetime Engine Output Energy Bin 11: Accumulated Engine output energy while all NOx sensors are active over the lifetime of the vehicle for Bin 11";
CM_ SG_ 2566588926 NOxTVdNOxLtEOtptEB12 "NOx Tracking Valid NOx Lifetime Engine Output Energy Bin 12: Accumulated Engine output energy while all NOx sensors are active over the lifetime of the vehicle for Bin 12";
CM_ SG_ 2566588926 NOxTVdNOxLtEOtptEB13 "NOx Tracking Valid NOx Lifetime Engine Output Energy Bin 13: Accumulated Engine output energy while all NOx sensors are active over the lifetime of the vehicle for Bin 13";
CM_ SG_ 2566588926 NOxTVdNOxLtEOtptEB14 "NOx Tracking Valid NOx Lifetime Engine Output Energy Bin 14 : Accumulated Engine output energy while all NOx sensors are active over the lifetime of the vehicle for Bin 14";
CM_ SG_ 2566588926 NOxTVdNOxLtEOtptEB15NTEBIN "NOx Tracking Valid NOx Lifetime Engine Output Energy Bin 15 (NTE BIN) : Accumulated Engine output energy while all NOx sensors are active over the lifetime of the vehicle for Bin 15 [Note Bin 15 is the NTE Bin]";
CM_ SG_ 2566588926 NOxTVdNOxLtEOtptEB16RB "NOx Tracking Valid NOx Lifetime Engine Output Energy Bin 16 (Regen Bin) : Accumulated Engine output energy while all NOx sensors are active over the lifetime of the vehicle for Bin 16 [Note Bin 16 is the Regen Bin]";
CM_ SG_ 2566588926 NOxTVdNOxLtEOtptEB17MILOB "NOx Tracking Valid NOx Lifetime Engine Output Energy Bin 17 (MIL On Bin) : Accumulated Engine output energy while all NOx sensors are active over the lifetime of the vehicle for Bin 17 [Note Bin 17 is the MIL On Bin]";
CM_ BO_ 2566589182 "NOx Tracking Valid NOx Lifetime Engine Out NOx Mass Bins ";
CM_ SG_ 2566589182 NOxTVdNOxLtEOtNOxMssB1Tt "NOx Tracking Valid NOx Lifetime Engine Out NOx Mass Bin 1 (Total): Accumulated Engine out NOx mass while all NOx sensors are active over the lifetime of the vehicle for Bin 1 [Note Bin 1 is the total of Bins 2-14]";
CM_ SG_ 2566589182 NOxTVdNOxLtEOtNOxMssB2 "NOx Tracking Valid NOx Lifetime Engine Out NOx Mass Bin 2 : Accumulated Engine out NOx mass while all NOx sensors are active over the lifetime of the vehicle for Bin 2 [Note Bin 2 is the 'idle' bin]";
CM_ SG_ 2566589182 NOxTVdNOxLtEOtNOxMssB3 "NOx Tracking Valid NOx Lifetime Engine Out NOx Mass Bin 3 : Accumulated Engine out NOx mass while all NOx sensors are active over the lifetime of the vehicle for Bin 3. ";
CM_ SG_ 2566589182 NOxTVdNOxLtEOtNOxMssB4 "NOx Tracking Valid NOx Lifetime Engine Out NOx Mass Bin 4: Accumulated Engine out NOx mass while all NOx sensors are active over the lifetime of the vehicle for Bin 4. ";
CM_ SG_ 2566589182 NOxTVdNOxLtEOtNOxMssB5 "NOx Tracking Valid NOx Lifetime Engine Out NOx Mass Bin 5: Accumulated Engine out NOx mass while all NOx sensors are active over the lifetime of the vehicle for Bin 5.";
CM_ SG_ 2566589182 NOxTVdNOxLtEOtNOxMssB6 "NOx Tracking Valid NOx Lifetime Engine Out NOx Mass Bin 6: Accumulated Engine out NOx mass while all NOx sensors are active over the lifetime of the vehicle for Bin 6. ";
CM_ SG_ 2566589182 NOxTVdNOxLtEOtNOxMssB7 "NOx Tracking Valid NOx Lifetime Engine Out NOx Mass Bin 7: Accumulated Engine out NOx mass while all NOx sensors are active over the lifetime of the vehicle for Bin 7. ";
CM_ SG_ 2566589182 NOxTVdNOxLtEOtNOxMssB8 "NOx Tracking Valid NOx Lifetime Engine Out NOx Mass Bin 8: Accumulated Engine out NOx mass while all NOx sensors are active over the lifetime of the vehicle for Bin 8. ";
CM_ SG_ 2566589182 NOxTVdNOxLtEOtNOxMssB9 "NOx Tracking Valid NOx Lifetime Engine Out NOx Mass Bin 9: Accumulated Engine out NOx mass while all NOx sensors are active over the lifetime of the vehicle for Bin 9";
CM_ SG_ 2566589182 NOxTVdNOxLtEOtNOxMssB10 "NOx Tracking Valid NOx Lifetime Engine Out NOx Mass Bin 10: Accumulated Engine out NOx mass while all NOx sensors are active over the lifetime of the vehicle for Bin 10";
CM_ SG_ 2566589182 NOxTVdNOxLtEOtNOxMssB11 "NOx Tracking Valid NOx Lifetime Engine Out NOx Mass Bin 11: Accumulated Engine out NOx mass while all NOx sensors are active over the lifetime of the vehicle for Bin 11";
CM_ SG_ 2566589182 NOxTVdNOxLtEOtNOxMssB12 "NOx Tracking Valid NOx Lifetime Engine Out NOx Mass Bin 12: Accumulated Engine out NOx mass while all NOx sensors are active over the lifetime of the vehicle for Bin 12";
CM_ SG_ 2566589182 NOxTVdNOxLtEOtNOxMssB13 "NOx Tracking Valid NOx Lifetime Engine Out NOx Mass Bin 13: Accumulated Engine out NOx mass while all NOx sensors are active over the lifetime of the vehicle for Bin 13";
CM_ SG_ 2566589182 NOxTVdNOxLtEOtNOxMssB14 "NOx Tracking Valid NOx Lifetime Engine Out NOx Mass Bin 14 : Accumulated Engine out NOx mass while all NOx sensors are active over the lifetime of the vehicle for Bin 14";
CM_ SG_ 2566589182 NOxTVdNOxLtEOtNOxMssB15NTEBIN "NOx Tracking Valid NOx Lifetime Engine Out NOx Mass Bin 15 (NTE BIN) : Accumulated Engine out NOx mass while all NOx sensors are active over the lifetime of the vehicle for Bin 15 [Note Bin 15 is the NTE Bin]";
CM_ SG_ 2566589182 NOxTVdNOxLtEOtNOxMssB16RB "NOx Tracking Valid NOx Lifetime Engine Out NOx Mass Bin 16 (Regen Bin) : Accumulated Engine out NOx mass while all NOx sensors are active over the lifetime of the vehicle for Bin 16 [Note Bin 16 is the Regen Bin]";
CM_ SG_ 2566589182 NOxTVdNOxLtEOtNOxMssB17MILOB "NOx Tracking Valid NOx Lifetime Engine Out NOx Mass Bin 17 (MIL On Bin): Accumulated Engine out NOx mass while all NOx sensors are active over the lifetime of the vehicle for Bin 17 [Note Bin 17 is the MIL On Bin]";
CM_ BO_ 2566589438 "NOx Tracking Valid NOx Lifetime System Out NOx Mass Bins ";
CM_ SG_ 2566589438 NOxTVdNOxLtSstOtNOxMssB1Tt "NOx Tracking Valid NOx Lifetime System Out NOx Mass Bin 1 (Total): Accumulated system out [SCR outlet] NOx mass while all NOx sensors are active over the lifetime of the vehicle for Bin 1 [Note Bin 1 is the total of Bins 2-14]";
CM_ SG_ 2566589438 NOxTVdNOxLtSstOtNOxMssB2 "NOx Tracking Valid NOx Lifetime System Out NOx Mass Bin 2 : Accumulated system out [SCR outlet] NOx mass while all NOx sensors are active over the lifetime of the vehicle for Bin 2 [Note Bin 2 is the 'idle' bin]";
CM_ SG_ 2566589438 NOxTVdNOxLtSstOtNOxMssB3 "NOx Tracking Valid NOx Lifetime System Out NOx Mass Bin 3 : Accumulated system out [SCR outlet] NOx mass while all NOx sensors are active over the lifetime of the vehicle for Bin 3. ";
CM_ SG_ 2566589438 NOxTVdNOxLtSstOtNOxMssB4 "NOx Tracking Valid NOx Lifetime System Out NOx Mass Bin 4: Accumulated system out [SCR outlet] NOx mass while all NOx sensors are active over the lifetime of the vehicle for Bin 4.";
CM_ SG_ 2566589438 NOxTVdNOxLtSstOtNOxMssB5 "NOx Tracking Valid NOx Lifetime System Out NOx Mass Bin 5: Accumulated system out [SCR outlet] NOx mass while all NOx sensors are active over the lifetime of the vehicle for Bin 5.";
CM_ SG_ 2566589438 NOxTVdNOxLtSstOtNOxMssB6 "NOx Tracking Valid NOx Lifetime System Out NOx Mass Bin 6: Accumulated system out [SCR outlet] NOx mass while all NOx sensors are active over the lifetime of the vehicle for Bin 6. ";
CM_ SG_ 2566589438 NOxTVdNOxLtSstOtNOxMssB7 "NOx Tracking Valid NOx Lifetime System Out NOx Mass Bin 7: Accumulated system out [SCR outlet] NOx mass while all NOx sensors are active over the lifetime of the vehicle for Bin 7. ";
CM_ SG_ 2566589438 NOxTVdNOxLtSstOtNOxMssB8 "NOx Tracking Valid NOx Lifetime System Out NOx Mass Bin 8: Accumulated system out [SCR outlet] NOx mass while all NOx sensors are active over the lifetime of the vehicle for Bin 8. ";
CM_ SG_ 2566589438 NOxTVdNOxLtSstOtNOxMssB9 "NOx Tracking Valid NOx Lifetime System Out NOx Mass Bin 9: Accumulated system out [SCR outlet] NOx mass while all NOx sensors are active over the lifetime of the vehicle for Bin 9";
CM_ SG_ 2566589438 NOxTVdNOxLtSstOtNOxMssB10 "NOx Tracking Valid NOx Lifetime System Out NOx Mass Bin 10: Accumulated system out [SCR outlet] NOx mass while all NOx sensors are active over the lifetime of the vehicle for Bin 10 ";
CM_ SG_ 2566589438 NOxTVdNOxLtSstOtNOxMssB11 "NOx Tracking Valid NOx Lifetime System Out NOx Mass Bin 11: Accumulated system out [SCR outlet] NOx mass while all NOx sensors are active over the lifetime of the vehicle for Bin 11";
CM_ SG_ 2566589438 NOxTVdNOxLtSstOtNOxMssB12 "NOx Tracking Valid NOx Lifetime System Out NOx Mass Bin 12: Accumulated system out [SCR outlet] NOx mass while all NOx sensors are active over the lifetime of the vehicle for Bin 12";
CM_ SG_ 2566589438 NOxTVdNOxLtSstOtNOxMssB13 "NOx Tracking Valid NOx Lifetime System Out NOx Mass Bin 13: Accumulated system out [SCR outlet] NOx mass while all NOx sensors are active over the lifetime of the vehicle for Bin 13";
CM_ SG_ 2566589438 NOxTVdNOxLtSstOtNOxMssB14 "NOx Tracking Valid NOx Lifetime System Out NOx Mass Bin 14 : Accumulated system out [SCR outlet] NOx mass while all NOx sensors are active over the lifetime of the vehicle for Bin 14";
CM_ SG_ 2566589438 NOxTVdNOxLtSstOtNOxMssB15NTEBIN "NOx Tracking Valid NOx Lifetime System Out NOx Mass Bin 15 (NTE BIN) : Accumulated system out [SCR outlet] NOx mass while all NOx sensors are active over the lifetime of the vehicle for Bin 15 [Note Bin 15 is the Regen Bin]";
CM_ SG_ 2566589438 NOxTVdNOxLtSstOtNOxMssB16RB "NOx Tracking Valid NOx Lifetime System Out NOx Mass Bin 16 (Regen Bin) : Accumulated system out [SCR outlet] NOx mass while all NOx sensors are active over the lifetime of the vehicle for Bin 16 [Note Bin 16 is the Regen Bin]";
CM_ SG_ 2566589438 NOxTVdNOxLtSstOtNOxMssB17MILOB "NOx Tracking Valid NOx Lifetime System Out NOx Mass Bin 17 (MIL On Bin) : Accumulated system out [SCR outlet] NOx mass while all NOx sensors are active over the lifetime of the vehicle for Bin 17 [Note Bin 17 is the MIL On Bin]";
CM_ BO_ 2566589694 "NOx Tracking Stored 100 Hour Fuel Consumption Bins ";
CM_ SG_ 2566589694 NOxTStd100HFCsptB1Tt "NOx Tracking Stored 100 Hour Fuel Consumption Bin 1 (Total): Accumulated Fuel consumption while all NOx sensors are active over the prior 100 hour period for Bin 1 [Note Bin 1 is the total of Bins 2-14]";
CM_ SG_ 2566589694 NOxTrkngStrd100HrFlCnsmptnBn2 "NOx Tracking Stored 100 Hour Fuel Consumption Bin 2 : Accumulated Fuel consumption while all NOx sensors are active over the prior 100 hour period for Bin 2 [Note Bin 2 is the 'idle' bin]";
CM_ SG_ 2566589694 NOxTrkngStrd100HrFlCnsmptnBn3 "NOx Tracking Stored 100 Hour Fuel Consumption Bin 3 : Accumulated Fuel consumption while all NOx sensors are active over the prior 100 hour period for Bin 3. ";
CM_ SG_ 2566589694 NOxTrkngStrd100HrFlCnsmptnBn4 "NOx Tracking Stored 100 Hour Fuel Consumption Bin 4: Accumulated Fuel consumption while all NOx sensors are active over the prior 100 hour period for Bin 4. ";
CM_ SG_ 2566589694 NOxTrkngStrd100HrFlCnsmptnBn5 "NOx Tracking Stored 100 Hour Fuel Consumption Bin 5: Accumulated Fuel consumption while all NOx sensors are active over the prior 100 hour period for Bin 5.";
CM_ SG_ 2566589694 NOxTrkngStrd100HrFlCnsmptnBn6 "NOx Tracking Stored 100 Hour Fuel Consumption Bin 6: Accumulated Fuel consumption while all NOx sensors are active over the prior 100 hour period for Bin 6. ";
CM_ SG_ 2566589694 NOxTrkngStrd100HrFlCnsmptnBn7 "NOx Tracking Stored 100 Hour Fuel Consumption Bin 7: Accumulated Fuel consumption while all NOx sensors are active over the prior 100 hour period for Bin 7. ";
CM_ SG_ 2566589694 NOxTrkngStrd100HrFlCnsmptnBn8 "NOx Tracking Stored 100 Hour Fuel Consumption Bin 8: Accumulated Fuel consumption while all NOx sensors are active over the prior 100 hour period for Bin 8. ";
CM_ SG_ 2566589694 NOxTrkngStrd100HrFlCnsmptnBn9 "NOx Tracking Stored 100 Hour Fuel Consumption Bin 9: Accumulated Fuel consumption while all NOx sensors are active over the prior 100 hour period for Bin 9";
CM_ SG_ 2566589694 NOxTrkngStrd100HrFlCnsmptnBn10 "NOx Tracking Stored 100 Hour Fuel Consumption Bin 10: Accumulated Fuel consumption while all NOx sensors are active over the prior 100 hour period for Bin 10";
CM_ SG_ 2566589694 NOxTrkngStrd100HrFlCnsmptnBn11 "NOx Tracking Stored 100 Hour Fuel Consumption Bin 11: Accumulated Fuel consumption while all NOx sensors are active over the prior 100 hour period for Bin 11";
CM_ SG_ 2566589694 NOxTrkngStrd100HrFlCnsmptnBn12 "NOx Tracking Stored 100 Hour Fuel Consumption Bin 12: Accumulated Fuel consumption while all NOx sensors are active over the prior 100 hour period for Bin 12";
CM_ SG_ 2566589694 NOxTrkngStrd100HrFlCnsmptnBn13 "NOx Tracking Stored 100 Hour Fuel Consumption Bin 13: Accumulated Fuel consumption while all NOx sensors are active over the prior 100 hour period for Bin 13";
CM_ SG_ 2566589694 NOxTrkngStrd100HrFlCnsmptnBn14 "NOx Tracking Stored 100 Hour Fuel Consumption Bin 14 : Accumulated Fuel consumption while all NOx sensors are active over the prior 100 hour period for Bin 14";
CM_ SG_ 2566589694 NOxTStd100HFCsptB15NTEBIN "NOx Tracking Stored 100 Hour Fuel Consumption Bin 15 (NTE BIN) : Accumulated Fuel consumption while all NOx sensors are active over the prior 100 hour period for Bin 15 [Note Bin 15 is the NTE Bin]";
CM_ SG_ 2566589694 NOxTStd100HFCsptB16RB "NOx Tracking Stored 100 Hour Fuel Consumption Bin 16 (Regen Bin) : Accumulated Fuel consumption while all NOx sensors are active over the prior 100 hour period for Bin 16 [Note Bin 16 is the Regen Bin]";
CM_ SG_ 2566589694 NOxTStd100HFCsptB17MILOB "NOx Tracking Stored 100 Hour Fuel Consumption Bin 17 (MIL On Bin) : Accumulated Fuel consumption while all NOx sensors are active over the prior 100 hour period for Bin 17 [Note Bin 17 is the MIL On Bin]";
CM_ BO_ 2566589950 "NOx Tracking Stored 100 Hour Engine Run Time Bins ";
CM_ SG_ 2566589950 NOxTrkngStrd100HrEngnRnTmBn1Ttl "NOx Tracking Stored 100 Hour Engine Run Time Bin 1 (Total): Accumulated Engine run time while all NOx sensors are active over the prior 100 hour period for Bin 1 [Note Bin 1 is the total of Bins 2-14]";
CM_ SG_ 2566589950 NOxTrkngStrd100HrEngnRnTmBn2 "NOx Tracking Stored 100 Hour Engine Run Time Bin 2 : Accumulated Engine run time while all NOx sensors are active over the prior 100 hour period for Bin 2 [Note Bin 2 is the 'idle' bin]";
CM_ SG_ 2566589950 NOxTrkngStrd100HrEngnRnTmBn3 "NOx Tracking Stored 100 Hour Engine Run Time Bin 3 : Accumulated Engine run time while all NOx sensors are active over the prior 100 hour period for Bin 3.";
CM_ SG_ 2566589950 NOxTrkngStrd100HrEngnRnTmBn4 "NOx Tracking Stored 100 Hour Engine Run Time Bin 4: Accumulated Engine run time while all NOx sensors are active over the prior 100 hour period for Bin 4.";
CM_ SG_ 2566589950 NOxTrkngStrd100HrEngnRnTmBn5 "NOx Tracking Stored 100 Hour Engine Run Time Bin 5: Accumulated Engine run time while all NOx sensors are active over the prior 100 hour period for Bin 5.";
CM_ SG_ 2566589950 NOxTrkngStrd100HrEngnRnTmBn6 "NOx Tracking Stored 100 Hour Engine Run Time Bin 6: Accumulated Engine run time while all NOx sensors are active over the prior 100 hour period for Bin 6. ";
CM_ SG_ 2566589950 NOxTrkngStrd100HrEngnRnTmBn7 "NOx Tracking Stored 100 Hour Engine Run Time Bin 7: Accumulated Engine run time while all NOx sensors are active over the prior 100 hour period for Bin 7. ";
CM_ SG_ 2566589950 NOxTrkngStrd100HrEngnRnTmBn8 "NOx Tracking Stored 100 Hour Engine Run Time Bin 8: Accumulated Engine run time while all NOx sensors are active over the prior 100 hour period for Bin 8. ";
CM_ SG_ 2566589950 NOxTrkngStrd100HrEngnRnTmBn9 "NOx Tracking Stored 100 Hour Engine Run Time Bin 9: Accumulated Engine run time while all NOx sensors are active over the prior 100 hour period for Bin 9";
CM_ SG_ 2566589950 NOxTrkngStrd100HrEngnRnTmBn10 "NOx Tracking Stored 100 Hour Engine Run Time Bin 10: Accumulated Engine run time while all NOx sensors are active over the prior 100 hour period for Bin 10";
CM_ SG_ 2566589950 NOxTrkngStrd100HrEngnRnTmBn11 "NOx Tracking Stored 100 Hour Engine Run Time Bin 11: Accumulated Engine run time while all NOx sensors are active over the prior 100 hour period for Bin 11";
CM_ SG_ 2566589950 NOxTrkngStrd100HrEngnRnTmBn12 "NOx Tracking Stored 100 Hour Engine Run Time Bin 12: Accumulated Engine run time while all NOx sensors are active over the prior 100 hour period for Bin 12";
CM_ SG_ 2566589950 NOxTrkngStrd100HrEngnRnTmBn13 "NOx Tracking Stored 100 Hour Engine Run Time Bin 13: Accumulated Engine run time while all NOx sensors are active over the prior 100 hour period for Bin 13";
CM_ SG_ 2566589950 NOxTrkngStrd100HrEngnRnTmBn14 "NOx Tracking Stored 100 Hour Engine Run Time Bin 14 : Accumulated Engine run time while all NOx sensors are active over the prior 100 hour period for Bin 14";
CM_ SG_ 2566589950 NOxTStd100HERTB15NTEBIN "NOx Tracking Stored 100 Hour Engine Run Time Bin 15 (NTE BIN) : Accumulated Engine run time while all NOx sensors are active over the prior 100 hour period for Bin 15 [Note Bin 15 is the NTE Bin]";
CM_ SG_ 2566589950 NOxTStd100HERTB16RB "NOx Tracking Stored 100 Hour Engine Run Time Bin 16 (Regen Bin) : Accumulated Engine run time while all NOx sensors are active over the prior 100 hour period for Bin 16 [Note Bin 16 is the Regen Bin]";
CM_ SG_ 2566589950 NOxTStd100HERTB17MILOB "NOx Tracking Stored 100 Hour Engine Run Time Bin 17 (MIL On Bin) : Accumulated Engine run time while all NOx sensors are active over the prior 100 hour period for Bin 17 [Note Bin 17 is the MIL On Bin]";
CM_ BO_ 2566590206 "NOx Tracking Stored 100 Hour Vehicle Distance Bins ";
CM_ SG_ 2566590206 NOxTrkngStrd100HrVhlDstnBn1Ttl "NOx Tracking Stored 100 Hour Vehicle Distance Bin 1 (Total): Accumulated Vehicle distance while all NOx sensors are active over the prior 100 hour period for Bin 1 [Note Bin 1 is the total of Bins 2-14]";
CM_ SG_ 2566590206 NOxTrkngStrd100HrVhlDstnBn2 "NOx Tracking Stored 100 Hour Vehicle Distance Bin 2 : Accumulated Vehicle distance while all NOx sensors are active over the prior 100 hour period for Bin 2 [Note Bin 2 is the 'idle' bin]";
CM_ SG_ 2566590206 NOxTrkngStrd100HrVhlDstnBn3 "NOx Tracking Stored 100 Hour Vehicle Distance Bin 3 : Accumulated Vehicle distance while all NOx sensors are active over the prior 100 hour period for Bin 3.";
CM_ SG_ 2566590206 NOxTrkngStrd100HrVhlDstnBn4 "NOx Tracking Stored 100 Hour Vehicle Distance Bin 4: Accumulated Vehicle distance while all NOx sensors are active over the prior 100 hour period for Bin 4.";
CM_ SG_ 2566590206 NOxTrkngStrd100HrVhlDstnBn5 "NOx Tracking Stored 100 Hour Vehicle Distance Bin 5: Accumulated Vehicle distance while all NOx sensors are active over the prior 100 hour period for Bin 5.";
CM_ SG_ 2566590206 NOxTrkngStrd100HrVhlDstnBn6 "NOx Tracking Stored 100 Hour Vehicle Distance Bin 6: Accumulated Vehicle distance while all NOx sensors are active over the prior 100 hour period for Bin 6. ";
CM_ SG_ 2566590206 NOxTrkngStrd100HrVhlDstnBn7 "NOx Tracking Stored 100 Hour Vehicle Distance Bin 7: Accumulated Vehicle distance while all NOx sensors are active over the prior 100 hour period for Bin 7. ";
CM_ SG_ 2566590206 NOxTrkngStrd100HrVhlDstnBn8 "NOx Tracking Stored 100 Hour Vehicle Distance Bin 8: Accumulated Vehicle distance while all NOx sensors are active over the prior 100 hour period for Bin 8. ";
CM_ SG_ 2566590206 NOxTrkngStrd100HrVhlDstnBn9 "NOx Tracking Stored 100 Hour Vehicle Distance Bin 9: Accumulated Vehicle distance while all NOx sensors are active over the prior 100 hour period for Bin 9";
CM_ SG_ 2566590206 NOxTrkngStrd100HrVhlDstnBn10 "NOx Tracking Stored 100 Hour Vehicle Distance Bin 10: Accumulated Vehicle distance while all NOx sensors are active over the prior 100 hour period for Bin 10";
CM_ SG_ 2566590206 NOxTrkngStrd100HrVhlDstnBn11 "NOx Tracking Stored 100 Hour Vehicle Distance Bin 11: Accumulated Vehicle distance while all NOx sensors are active over the prior 100 hour period for Bin 11";
CM_ SG_ 2566590206 NOxTrkngStrd100HrVhlDstnBn12 "NOx Tracking Stored 100 Hour Vehicle Distance Bin 12: Accumulated Vehicle distance while all NOx sensors are active over the prior 100 hour period for Bin 12";
CM_ SG_ 2566590206 NOxTrkngStrd100HrVhlDstnBn13 "NOx Tracking Stored 100 Hour Vehicle Distance Bin 13: Accumulated Vehicle distance while all NOx sensors are active over the prior 100 hour period for Bin 13";
CM_ SG_ 2566590206 NOxTrkngStrd100HrVhlDstnBn14 "NOx Tracking Stored 100 Hour Vehicle Distance Bin 14 : Accumulated Vehicle distance while all NOx sensors are active over the prior 100 hour period for Bin 14";
CM_ SG_ 2566590206 NOxTStd100HVDstB15NTEBIN "NOx Tracking Stored 100 Hour Vehicle Distance Bin 15 (NTE BIN) : Accumulated Vehicle distance while all NOx sensors are active over the prior 100 hour period for Bin 15 [Note Bin 15 is the NTE Bin]";
CM_ SG_ 2566590206 NOxTStd100HVDstB16RB "NOx Tracking Stored 100 Hour Vehicle Distance Bin 16 (Regen Bin) : Accumulated Vehicle distance while all NOx sensors are active over the prior 100 hour period for Bin 16 [Note Bin 16 is the Regen Bin]";
CM_ SG_ 2566590206 NOxTStd100HVDstB17MILOB "NOx Tracking Stored 100 Hour Vehicle Distance Bin 17 (MIL On Bin) : Accumulated Vehicle distance while all NOx sensors are active over the prior 100 hour period for Bin 17 [Note Bin 17 is the MIL ON Bin]";
CM_ BO_ 2566590462 "NOx Tracking Stored 100 Hour Engine Output Energy Bins ";
CM_ SG_ 2566590462 NOxTStd100HEOtptEB1Tt "NOx Tracking Stored 100 Hour Engine Output Energy Bin 1 (Total): Accumulated Engine output energy while all NOx sensors are active over the prior 100 hour period for Bin 1 [Note Bin 1 is the total of Bins 2-14]";
CM_ SG_ 2566590462 NOxTStd100HEOtptEB2 "NOx Tracking Stored 100 Hour Engine Output Energy Bin 2 : Accumulated Engine output energy while all NOx sensors are active over the prior 100 hour period for Bin 2 [Note Bin 2 is the 'idle' bin]";
CM_ SG_ 2566590462 NOxTStd100HEOtptEB3 "NOx Tracking Stored 100 Hour Engine Output Energy Bin 3 : Accumulated Engine output energy while all NOx sensors are active over the prior 100 hour period for Bin 3. ";
CM_ SG_ 2566590462 NOxTStd100HEOtptEB4 "NOx Tracking Stored 100 Hour Engine Output Energy Bin 4: Accumulated Engine output energy while all NOx sensors are active over the prior 100 hour period for Bin 4.";
CM_ SG_ 2566590462 NOxTStd100HEOtptEB5 "NOx Tracking Stored 100 Hour Engine Output Energy Bin 5: Accumulated Engine output energy while all NOx sensors are active over the prior 100 hour period for Bin 5.";
CM_ SG_ 2566590462 NOxTStd100HEOtptEB6 "NOx Tracking Stored 100 Hour Engine Output Energy Bin 6: Accumulated Engine output energy while all NOx sensors are active over the prior 100 hour period for Bin 6. ";
CM_ SG_ 2566590462 NOxTStd100HEOtptEB7 "NOx Tracking Stored 100 Hour Engine Output Energy Bin 7: Accumulated Engine output energy while all NOx sensors are active over the prior 100 hour period for Bin 7. ";
CM_ SG_ 2566590462 NOxTStd100HEOtptEB8 "NOx Tracking Stored 100 Hour Engine Output Energy Bin 8: Accumulated Engine output energy while all NOx sensors are active over the prior 100 hour period for Bin 8. ";
CM_ SG_ 2566590462 NOxTStd100HEOtptEB9 "NOx Tracking Stored 100 Hour Engine Output Energy Bin 9: Accumulated Engine output energy while all NOx sensors are active over the prior 100 hour period for Bin 9";
CM_ SG_ 2566590462 NOxTStd100HEOtptEB10 "NOx Tracking Stored 100 Hour Engine Output Energy Bin 10: Accumulated Engine output energy while all NOx sensors are active over the prior 100 hour period for Bin 10";
CM_ SG_ 2566590462 NOxTStd100HEOtptEB11 "NOx Tracking Stored 100 Hour Engine Output Energy Bin 11: Accumulated Engine output energy while all NOx sensors are active over the prior 100 hour period for Bin 11";
CM_ SG_ 2566590462 NOxTStd100HEOtptEB12 "NOx Tracking Stored 100 Hour Engine Output Energy Bin 12: Accumulated Engine output energy while all NOx sensors are active over the prior 100 hour period for Bin 12";
CM_ SG_ 2566590462 NOxTStd100HEOtptEB13 "NOx Tracking Stored 100 Hour Engine Output Energy Bin 13: Accumulated Engine output energy while all NOx sensors are active over the prior 100 hour period for Bin 13";
CM_ SG_ 2566590462 NOxTStd100HEOtptEB14 "NOx Tracking Stored 100 Hour Engine Output Energy Bin 14 : Accumulated Engine output energy while all NOx sensors are active over the prior 100 hour period for Bin 14";
CM_ SG_ 2566590462 NOxTStd100HEOtptEB15NTEBIN "NOx Tracking Stored 100 Hour Engine Output Energy Bin 15 (NTE BIN) : Accumulated Engine output energy while all NOx sensors are active over the prior 100 hour period for Bin 15 [Note Bin 15 is the NTE Bin]";
CM_ SG_ 2566590462 NOxTStd100HEOtptEB16RB "NOx Tracking Stored 100 Hour Engine Output Energy Bin 16 (Regen Bin) : Accumulated Engine output energy while all NOx sensors are active over the prior 100 hour period for Bin 16 [Note Bin 16 is the Regen Bin]";
CM_ SG_ 2566590462 NOxTStd100HEOtptEB17MILOB "NOx Tracking Stored 100 Hour Engine Output Energy Bin 17 (MIL On Bin) : Accumulated Engine output energy while all NOx sensors are active over the prior 100 hour period for Bin 17 [Note Bin 17 is the MIL On Bin]";
CM_ BO_ 2566590718 "NOx Tracking Stored 100 Hour Engine Out NOx Mass Bins ";
CM_ SG_ 2566590718 NOxTStd100HEOtNOxMssB1Tt "NOx Tracking Stored 100 Hour Engine Out NOx Mass Bin 1 (Total): Accumulated Engine out NOx mass while all NOx sensors are active over the prior 100 hour period for Bin 1 [Note Bin 1 is the total of Bins 2-14]";
CM_ SG_ 2566590718 NOxTStd100HEOtNOxMssB2 "NOx Tracking Stored 100 Hour Engine Out NOx Mass Bin 2 : Accumulated Engine out NOx mass while all NOx sensors are active over the prior 100 hour period for Bin 2 [Note Bin 2 is the 'idle' bin]";
CM_ SG_ 2566590718 NOxTStd100HEOtNOxMssB3 "NOx Tracking Stored 100 Hour Engine Out NOx Mass Bin 3 : Accumulated Engine out NOx mass while all NOx sensors are active over the prior 100 hour period for Bin 3. ";
CM_ SG_ 2566590718 NOxTStd100HEOtNOxMssB4 "NOx Tracking Stored 100 Hour Engine Out NOx Mass Bin 4: Accumulated Engine out NOx mass while all NOx sensors are active over the prior 100 hour period for Bin 4.";
CM_ SG_ 2566590718 NOxTStd100HEOtNOxMssB5 "NOx Tracking Stored 100 Hour Engine Out NOx Mass Bin 5: Accumulated Engine out NOx mass while all NOx sensors are active over the prior 100 hour period for Bin 5.";
CM_ SG_ 2566590718 NOxTStd100HEOtNOxMssB6 "NOx Tracking Stored 100 Hour Engine Out NOx Mass Bin 6: Accumulated Engine out NOx mass while all NOx sensors are active over the prior 100 hour period for Bin 6. ";
CM_ SG_ 2566590718 NOxTStd100HEOtNOxMssB7 "NOx Tracking Stored 100 Hour Engine Out NOx Mass Bin 7: Accumulated Engine out NOx mass while all NOx sensors are active over the prior 100 hour period for Bin 7. ";
CM_ SG_ 2566590718 NOxTStd100HEOtNOxMssB8 "NOx Tracking Stored 100 Hour Engine Out NOx Mass Bin 8: Accumulated Engine out NOx mass while all NOx sensors are active over the prior 100 hour period for Bin 8. ";
CM_ SG_ 2566590718 NOxTStd100HEOtNOxMssB9 "NOx Tracking Stored 100 Hour Engine Out NOx Mass Bin 9: Accumulated Engine out NOx mass while all NOx sensors are active over the prior 100 hour period for Bin 9";
CM_ SG_ 2566590718 NOxTStd100HEOtNOxMssB10 "NOx Tracking Stored 100 Hour Engine Out NOx Mass Bin 10: Accumulated Engine out NOx mass while all NOx sensors are active over the prior 100 hour period for Bin 10";
CM_ SG_ 2566590718 NOxTStd100HEOtNOxMssB11 "NOx Tracking Stored 100 Hour Engine Out NOx Mass Bin 11: Accumulated Engine out NOx mass while all NOx sensors are active over the prior 100 hour period for Bin 11";
CM_ SG_ 2566590718 NOxTStd100HEOtNOxMssB12 "NOx Tracking Stored 100 Hour Engine Out NOx Mass Bin 12: Accumulated Engine out NOx mass while all NOx sensors are active over the prior 100 hour period for Bin 12";
CM_ SG_ 2566590718 NOxTStd100HEOtNOxMssB13 "NOx Tracking Stored 100 Hour Engine Out NOx Mass Bin 13: Accumulated Engine out NOx mass while all NOx sensors are active over the prior 100 hour period for Bin 13";
CM_ SG_ 2566590718 NOxTStd100HEOtNOxMssB14 "NOx Tracking Stored 100 Hour Engine Out NOx Mass Bin 14 : Accumulated Engine out NOx mass while all NOx sensors are active over the prior 100 hour period for Bin 14";
CM_ SG_ 2566590718 NOxTStd100HEOtNOxMssB15NTEBIN "NOx Tracking Stored 100 Hour Engine Out NOx Mass Bin 15 (NTE BIN) : Accumulated Engine out NOx mass while all NOx sensors are active over the prior 100 hour period for Bin 15 [Note Bin 15 is the NTE Bin]";
CM_ SG_ 2566590718 NOxTStd100HEOtNOxMssB16RB "NOx Tracking Stored 100 Hour Engine Out NOx Mass Bin 16 (Regen Bin) : Accumulated Engine out NOx mass while all NOx sensors are active over the prior 100 hour period for Bin 16 [Note Bin 16 is the Regen Bin]";
CM_ SG_ 2566590718 NOxTStd100HEOtNOxMssB17MILOB "NOx Tracking Stored 100 Hour Engine Out NOx Mass Bin 17 (MIL On Bin) : Accumulated Engine out NOx mass while all NOx sensors are active over the prior 100 hour period for Bin 17 [Note Bin 17 is the Mil On Bin]";
CM_ BO_ 2566590974 "NOx Tracking Stored 100 Hour System Out NOx Mass Bins ";
CM_ SG_ 2566590974 NOxTStd100HSstOtNOxMssB1Tt "NOx Tracking Stored 100 Hour System Out NOx Mass Bin 1 (Total): Accumulated system out [SCR outlet] NOx mass while all NOx sensors are active over the prior 100 hour period for Bin 1 [Note Bin 1 is the total of Bins 2-14]";
CM_ SG_ 2566590974 NOxTStd100HSstOtNOxMssB2 "NOx Tracking Stored 100 Hour System Out NOx Mass Bin 2 : Accumulated system out [SCR outlet] NOx mass while all NOx sensors are active over the prior 100 hour period for Bin 2 [Note Bin 2 is the 'idle' bin]";
CM_ SG_ 2566590974 NOxTStd100HSstOtNOxMssB3 "NOx Tracking Stored 100 Hour System Out NOx Mass Bin 3 : Accumulated system out [SCR outlet] NOx mass while all NOx sensors are active over the prior 100 hour period for Bin 3.";
CM_ SG_ 2566590974 NOxTStd100HSstOtNOxMssB4 "NOx Tracking Stored 100 Hour System Out NOx Mass Bin 4: Accumulated system out [SCR outlet] NOx mass while all NOx sensors are active over the prior 100 hour period for Bin 4.";
CM_ SG_ 2566590974 NOxTStd100HSstOtNOxMssB5 "NOx Tracking Stored 100 Hour System Out NOx Mass Bin 5: Accumulated system out [SCR outlet] NOx mass while all NOx sensors are active over the prior 100 hour period for Bin 5.";
CM_ SG_ 2566590974 NOxTStd100HSstOtNOxMssB6 "NOx Tracking Stored 100 Hour System Out NOx Mass Bin 6: Accumulated system out [SCR outlet] NOx mass while all NOx sensors are active over the prior 100 hour period for Bin 6. ";
CM_ SG_ 2566590974 NOxTStd100HSstOtNOxMssB7 "NOx Tracking Stored 100 Hour System Out NOx Mass Bin 7: Accumulated system out [SCR outlet] NOx mass while all NOx sensors are active over the prior 100 hour period for Bin 7. ";
CM_ SG_ 2566590974 NOxTStd100HSstOtNOxMssB8 "NOx Tracking Stored 100 Hour System Out NOx Mass Bin 8: Accumulated system out [SCR outlet] NOx mass while all NOx sensors are active over the prior 100 hour period for Bin 8. ";
CM_ SG_ 2566590974 NOxTStd100HSstOtNOxMssB9 "NOx Tracking Stored 100 Hour System Out NOx Mass Bin 9: Accumulated system out [SCR outlet] NOx mass while all NOx sensors are active over the prior 100 hour period for Bin 9";
CM_ SG_ 2566590974 NOxTStd100HSstOtNOxMssB10 "NOx Tracking Stored 100 Hour System Out NOx Mass Bin 10: Accumulated system out [SCR outlet] NOx mass while all NOx sensors are active over the prior 100 hour period for Bin 10 ";
CM_ SG_ 2566590974 NOxTStd100HSstOtNOxMssB11 "NOx Tracking Stored 100 Hour System Out NOx Mass Bin 11: Accumulated system out [SCR outlet] NOx mass while all NOx sensors are active over the prior 100 hour period for Bin 11";
CM_ SG_ 2566590974 NOxTStd100HSstOtNOxMssB12 "NOx Tracking Stored 100 Hour System Out NOx Mass Bin 12: Accumulated system out [SCR outlet] NOx mass while all NOx sensors are active over the prior 100 hour period for Bin 12";
CM_ SG_ 2566590974 NOxTStd100HSstOtNOxMssB13 "NOx Tracking Stored 100 Hour System Out NOx Mass Bin 13: Accumulated system out [SCR outlet] NOx mass while all NOx sensors are active over the prior 100 hour period for Bin 13";
CM_ SG_ 2566590974 NOxTStd100HSstOtNOxMssB14 "NOx Tracking Stored 100 Hour System Out NOx Mass Bin 14 : Accumulated system out [SCR outlet] NOx mass while all NOx sensors are active over the prior 100 hour period for Bin 14";
CM_ SG_ 2566590974 NOxTStd100HSstOtNOxMssB15NTEBIN "NOx Tracking Stored 100 Hour System Out NOx Mass Bin 15 (NTE BIN) : Accumulated system out [SCR outlet] NOx mass while all NOx sensors are active over the prior 100 hour period for Bin 15 [Note Bin 15 is the Regen Bin]";
CM_ SG_ 2566590974 NOxTStd100HSstOtNOxMssB16RB "NOx Tracking Stored 100 Hour System Out NOx Mass Bin 16 (Regen Bin) : Accumulated system out [SCR outlet] NOx mass while all NOx sensors are active over the prior 100 hour period for Bin 16 [Note Bin 16 is the Regen Bin]";
CM_ SG_ 2566590974 NOxTStd100HSstOtNOxMssB17MILOB "NOx Tracking Stored 100 Hour System Out NOx Mass Bin 17 (MIL On Bin) : Accumulated system out [SCR outlet] NOx mass while all NOx sensors are active over the prior 100 hour period for Bin 17 [Note Bin 17 is the MIL On Bin]";
CM_ BO_ 2566591230 "NOx Tracking Active 100 Hour Fuel Consumption Bins ";
CM_ SG_ 2566591230 NOxTrkngAtv100HrFlCnsmptnBn1Ttl "NOx Tracking Active 100 Hour Fuel Consumption Bin 1 (Total): Accumulated Fuel consumption while all NOx sensors are active over the current 100 hour block for Bin 1 [Note Bin 1 is the total of Bins 2-14]";
CM_ SG_ 2566591230 NOxTrkngAtv100HrFlCnsmptnBn2 "NOx Tracking Active 100 Hour Fuel Consumption Bin 2 : Accumulated Fuel consumption while all NOx sensors are active over the current 100 hour block for Bin 2 [Note Bin 2 is the 'idle' bin]";
CM_ SG_ 2566591230 NOxTrkngAtv100HrFlCnsmptnBn3 "NOx Tracking Active 100 Hour Fuel Consumption Bin 3 : Accumulated Fuel consumption while all NOx sensors are active over the current 100 hour block for Bin 3.";
CM_ SG_ 2566591230 NOxTrkngAtv100HrFlCnsmptnBn4 "NOx Tracking Active 100 Hour Fuel Consumption Bin 4: Accumulated Fuel consumption while all NOx sensors are active over the current 100 hour block for Bin 4.";
CM_ SG_ 2566591230 NOxTrkngAtv100HrFlCnsmptnBn5 "NOx Tracking Active 100 Hour Fuel Consumption Bin 5: Accumulated Fuel consumption while all NOx sensors are active over the current 100 hour block for Bin 5.";
CM_ SG_ 2566591230 NOxTrkngAtv100HrFlCnsmptnBn6 "NOx Tracking Active 100 Hour Fuel Consumption Bin 6: Accumulated Fuel consumption while all NOx sensors are active over the current 100 hour block for Bin 6. ";
CM_ SG_ 2566591230 NOxTrkngAtv100HrFlCnsmptnBn7 "NOx Tracking Active 100 Hour Fuel Consumption Bin 7: Accumulated Fuel consumption while all NOx sensors are active over the current 100 hour block for Bin 7. ";
CM_ SG_ 2566591230 NOxTrkngAtv100HrFlCnsmptnBn8 "NOx Tracking Active 100 Hour Fuel Consumption Bin 8: Accumulated Fuel consumption while all NOx sensors are active over the current 100 hour block for Bin 8. ";
CM_ SG_ 2566591230 NOxTrkngAtv100HrFlCnsmptnBn9 "NOx Tracking Active 100 Hour Fuel Consumption Bin 9: Accumulated Fuel consumption while all NOx sensors are active over the current 100 hour block for Bin 9";
CM_ SG_ 2566591230 NOxTrkngAtv100HrFlCnsmptnBn10 "NOx Tracking Active 100 Hour Fuel Consumption Bin 10: Accumulated Fuel consumption while all NOx sensors are active over the current 100 hour block for Bin 10";
CM_ SG_ 2566591230 NOxTrkngAtv100HrFlCnsmptnBn11 "NOx Tracking Active 100 Hour Fuel Consumption Bin 11: Accumulated Fuel consumption while all NOx sensors are active over the current 100 hour block for Bin 11";
CM_ SG_ 2566591230 NOxTrkngAtv100HrFlCnsmptnBn12 "NOx Tracking Active 100 Hour Fuel Consumption Bin 12: Accumulated Fuel consumption while all NOx sensors are active over the current 100 hour block for Bin 12";
CM_ SG_ 2566591230 NOxTrkngAtv100HrFlCnsmptnBn13 "NOx Tracking Active 100 Hour Fuel Consumption Bin 13: Accumulated Fuel consumption while all NOx sensors are active over the current 100 hour block for Bin 13";
CM_ SG_ 2566591230 NOxTrkngAtv100HrFlCnsmptnBn14 "NOx Tracking Active 100 Hour Fuel Consumption Bin 14 : Accumulated Fuel consumption while all NOx sensors are active over the current 100 hour block for Bin 14";
CM_ SG_ 2566591230 NOxTAtv100HFCsptB15NTEBIN "NOx Tracking Active 100 Hour Fuel Consumption Bin 15 (NTE BIN) : Accumulated Fuel consumption while all NOx sensors are active over the current 100 hour block for Bin 15 [Note Bin 15 is the NTE Bin]";
CM_ SG_ 2566591230 NOxTAtv100HFCsptB16RB "NOx Tracking Active 100 Hour Fuel Consumption Bin 16 (Regen Bin) : Accumulated Fuel consumption while all NOx sensors are active over the current 100 hour block for Bin 16 [Note Bin 16 is the Regen Bin]";
CM_ SG_ 2566591230 NOxTAtv100HFCsptB17MILOB "NOx Tracking Active 100 Hour Fuel Consumption Bin 17 (MIL On Bin) : Accumulated Fuel consumption while all NOx sensors are active over the current 100 hour block for Bin 17 [Note Bin 17 is the Mil On Bin]";
CM_ BO_ 2566591486 "NOx Tracking Active 100 Hour Engine Run Time Bins ";
CM_ SG_ 2566591486 NOxTrkngAtv100HrEngnRnTmBn1Ttl "NOx Tracking Active 100 Hour Engine Run Time Bin 1 (Total): Accumulated Engine run time while all NOx sensors are active over the current 100 hour block for Bin 1 [Note Bin 1 is the total of Bins 2-14]";
CM_ SG_ 2566591486 NOxTrkngAtv100HrEngnRnTmBn2 "NOx Tracking Active 100 Hour Engine Run Time Bin 2 : Accumulated Engine run time while all NOx sensors are active over the current 100 hour block for Bin 2 [Note Bin 2 is the 'idle' bin]";
CM_ SG_ 2566591486 NOxTrkngAtv100HrEngnRnTmBn3 "NOx Tracking Active 100 Hour Engine Run Time Bin 3 : Accumulated Engine run time while all NOx sensors are active over the current 100 hour block for Bin 3. ";
CM_ SG_ 2566591486 NOxTrkngAtv100HrEngnRnTmBn4 "NOx Tracking Active 100 Hour Engine Run Time Bin 4: Accumulated Engine run time while all NOx sensors are active over the current 100 hour block for Bin 4. ";
CM_ SG_ 2566591486 NOxTrkngAtv100HrEngnRnTmBn5 "NOx Tracking Active 100 Hour Engine Run Time Bin 5: Accumulated Engine run time while all NOx sensors are active over the current 100 hour block for Bin 5.";
CM_ SG_ 2566591486 NOxTrkngAtv100HrEngnRnTmBn6 "NOx Tracking Active 100 Hour Engine Run Time Bin 6: Accumulated Engine run time while all NOx sensors are active over the current 100 hour block for Bin 6. ";
CM_ SG_ 2566591486 NOxTrkngAtv100HrEngnRnTmBn7 "NOx Tracking Active 100 Hour Engine Run Time Bin 7: Accumulated Engine run time while all NOx sensors are active over the current 100 hour block for Bin 7. ";
CM_ SG_ 2566591486 NOxTrkngAtv100HrEngnRnTmBn8 "NOx Tracking Active 100 Hour Engine Run Time Bin 8: Accumulated Engine run time while all NOx sensors are active over the current 100 hour block for Bin 8. ";
CM_ SG_ 2566591486 NOxTrkngAtv100HrEngnRnTmBn9 "NOx Tracking Active 100 Hour Engine Run Time Bin 9: Accumulated Engine run time while all NOx sensors are active over the current 100 hour block for Bin 9";
CM_ SG_ 2566591486 NOxTrkngAtv100HrEngnRnTmBn10 "NOx Tracking Active 100 Hour Engine Run Time Bin 10: Accumulated Engine run time while all NOx sensors are active over the current 100 hour block for Bin 10";
CM_ SG_ 2566591486 NOxTrkngAtv100HrEngnRnTmBn11 "NOx Tracking Active 100 Hour Engine Run Time Bin 11: Accumulated Engine run time while all NOx sensors are active over the current 100 hour block for Bin 11";
CM_ SG_ 2566591486 NOxTrkngAtv100HrEngnRnTmBn12 "NOx Tracking Active 100 Hour Engine Run Time Bin 12: Accumulated Engine run time while all NOx sensors are active over the current 100 hour block for Bin 12";
CM_ SG_ 2566591486 NOxTrkngAtv100HrEngnRnTmBn13 "NOx Tracking Active 100 Hour Engine Run Time Bin 13: Accumulated Engine run time while all NOx sensors are active over the current 100 hour block for Bin 13";
CM_ SG_ 2566591486 NOxTrkngAtv100HrEngnRnTmBn14 "NOx Tracking Active 100 Hour Engine Run Time Bin 14 : Accumulated Engine run time while all NOx sensors are active over the current 100 hour block for Bin 14";
CM_ SG_ 2566591486 NOxTAtv100HERTB15NTEBIN "NOx Tracking Active 100 Hour Engine Run Time Bin 15 (NTE BIN) : Accumulated Engine run time while all NOx sensors are active over the current 100 hour block for Bin 15 [Note Bin 15 is the NTE Bin]";
CM_ SG_ 2566591486 NOxTAtv100HERTB16RB "NOx Tracking Active 100 Hour Engine Run Time Bin 16 (Regen Bin) : Accumulated Engine run time while all NOx sensors are active over the current 100 hour block for Bin 16 [Note Bin 16 is the Regen Bin]";
CM_ SG_ 2566591486 NOxTAtv100HERTB17MILOB "NOx Tracking Active 100 Hour Engine Run Time Bin 17 (MIL On Bin) : Accumulated Engine run time while all NOx sensors are active over the current 100 hour block for Bin 17 [Note Bin 17 is the MIL On Bin]";
CM_ BO_ 2566591742 "NOx Tracking Active 100 Hour Vehicle Distance Bins ";
CM_ SG_ 2566591742 NOxTrkngAtv100HrVhlDstnBn1Ttl "NOx Tracking Active 100 Hour Vehicle Distance Bin 1 (Total): Accumulated Vehicle distance while all NOx sensors are active over the current 100 hour block for Bin 1 [Note Bin 1 is the total of Bins 2-14]";
CM_ SG_ 2566591742 NOxTrkngAtv100HrVhlDstnBn2 "NOx Tracking Active 100 Hour Vehicle Distance Bin 2 : Accumulated Vehicle distance while all NOx sensors are active over the current 100 hour block for Bin 2 [Note Bin 2 is the 'idle' bin]";
CM_ SG_ 2566591742 NOxTrkngAtv100HrVhlDstnBn3 "NOx Tracking Active 100 Hour Vehicle Distance Bin 3 : Accumulated Vehicle distance while all NOx sensors are active over the current 100 hour block for Bin 3.";
CM_ SG_ 2566591742 NOxTrkngAtv100HrVhlDstnBn4 "NOx Tracking Active 100 Hour Vehicle Distance Bin 4: Accumulated Vehicle distance while all NOx sensors are active over the current 100 hour block for Bin 4. ";
CM_ SG_ 2566591742 NOxTrkngAtv100HrVhlDstnBn5 "NOx Tracking Active 100 Hour Vehicle Distance Bin 5: Accumulated Vehicle distance while all NOx sensors are active over the current 100 hour block for Bin 5.";
CM_ SG_ 2566591742 NOxTrkngAtv100HrVhlDstnBn6 "NOx Tracking Active 100 Hour Vehicle Distance Bin 6: Accumulated Vehicle distance while all NOx sensors are active over the current 100 hour block for Bin 6. ";
CM_ SG_ 2566591742 NOxTrkngAtv100HrVhlDstnBn7 "NOx Tracking Active 100 Hour Vehicle Distance Bin 7: Accumulated Vehicle distance while all NOx sensors are active over the current 100 hour block for Bin 7. ";
CM_ SG_ 2566591742 NOxTrkngAtv100HrVhlDstnBn8 "NOx Tracking Active 100 Hour Vehicle Distance Bin 8: Accumulated Vehicle distance while all NOx sensors are active over the current 100 hour block for Bin 8. ";
CM_ SG_ 2566591742 NOxTrkngAtv100HrVhlDstnBn9 "NOx Tracking Active 100 Hour Vehicle Distance Bin 9: Accumulated Vehicle distance while all NOx sensors are active over the current 100 hour block for Bin 9";
CM_ SG_ 2566591742 NOxTrkngAtv100HrVhlDstnBn10 "NOx Tracking Active 100 Hour Vehicle Distance Bin 10: Accumulated Vehicle distance while all NOx sensors are active over the current 100 hour block for Bin 10";
CM_ SG_ 2566591742 NOxTrkngAtv100HrVhlDstnBn11 "NOx Tracking Active 100 Hour Vehicle Distance Bin 11: Accumulated Vehicle distance while all NOx sensors are active over the current 100 hour block for Bin 11";
CM_ SG_ 2566591742 NOxTrkngAtv100HrVhlDstnBn12 "NOx Tracking Active 100 Hour Vehicle Distance Bin 12: Accumulated Vehicle distance while all NOx sensors are active over the current 100 hour block for Bin 12";
CM_ SG_ 2566591742 NOxTrkngAtv100HrVhlDstnBn13 "NOx Tracking Active 100 Hour Vehicle Distance Bin 13: Accumulated Vehicle distance while all NOx sensors are active over the current 100 hour block for Bin 13";
CM_ SG_ 2566591742 NOxTrkngAtv100HrVhlDstnBn14 "NOx Tracking Active 100 Hour Vehicle Distance Bin 14 : Accumulated Vehicle distance while all NOx sensors are active over the current 100 hour block for Bin 14";
CM_ SG_ 2566591742 NOxTAtv100HVDstB15NTEBIN "NOx Tracking Active 100 Hour Vehicle Distance Bin 15 (NTE BIN) : Accumulated Vehicle distance while all NOx sensors are active over the current 100 hour block for Bin 15 [Note Bin 15 is the NTE Bin]";
CM_ SG_ 2566591742 NOxTAtv100HVDstB16RB "NOx Tracking Active 100 Hour Vehicle Distance Bin 16 (Regen Bin) : Accumulated Vehicle distance while all NOx sensors are active over the current 100 hour block for Bin 16 [Note Bin 16 is the Regen Bin]";
CM_ SG_ 2566591742 NOxTAtv100HVDstB17MILOB "NOx Tracking Active 100 Hour Vehicle Distance Bin 17 (MIL On Bin) : Accumulated Vehicle distance while all NOx sensors are active over the current 100 hour block for Bin 17 [Note Bin 17 is the Mil On Bin]";
CM_ BO_ 2566591998 "NOx Tracking Active 100 Hour Engine Output Energy Bins ";
CM_ SG_ 2566591998 NOxTAtv100HEOtptEB1Tt "NOx Tracking Active 100 Hour Engine Output Energy Bin 1 (Total): Accumulated Engine output energy while all NOx sensors are active over the current 100 hour block for Bin 1 [Note Bin 1 is the total of Bins 2-14]";
CM_ SG_ 2566591998 NOxTrkngAtv100HrEngnOtptEnrgBn2 "NOx Tracking Active 100 Hour Engine Output Energy Bin 2 : Accumulated Engine output energy while all NOx sensors are active over the current 100 hour block for Bin 2 [Note Bin 2 is the 'idle' bin]";
CM_ SG_ 2566591998 NOxTrkngAtv100HrEngnOtptEnrgBn3 "NOx Tracking Active 100 Hour Engine Output Energy Bin 3 : Accumulated Engine output energy while all NOx sensors are active over the current 100 hour block for Bin 3. ";
CM_ SG_ 2566591998 NOxTrkngAtv100HrEngnOtptEnrgBn4 "NOx Tracking Active 100 Hour Engine Output Energy Bin 4: Accumulated Engine output energy while all NOx sensors are active over the current 100 hour block for Bin 4.";
CM_ SG_ 2566591998 NOxTrkngAtv100HrEngnOtptEnrgBn5 "NOx Tracking Active 100 Hour Engine Output Energy Bin 5: Accumulated Engine output energy while all NOx sensors are active over the current 100 hour block for Bin 5.";
CM_ SG_ 2566591998 NOxTrkngAtv100HrEngnOtptEnrgBn6 "NOx Tracking Active 100 Hour Engine Output Energy Bin 6: Accumulated Engine output energy while all NOx sensors are active over the current 100 hour block for Bin 6. ";
CM_ SG_ 2566591998 NOxTrkngAtv100HrEngnOtptEnrgBn7 "NOx Tracking Active 100 Hour Engine Output Energy Bin 7: Accumulated Engine output energy while all NOx sensors are active over the current 100 hour block for Bin 7. ";
CM_ SG_ 2566591998 NOxTrkngAtv100HrEngnOtptEnrgBn8 "NOx Tracking Active 100 Hour Engine Output Energy Bin 8: Accumulated Engine output energy while all NOx sensors are active over the current 100 hour block for Bin 8. ";
CM_ SG_ 2566591998 NOxTrkngAtv100HrEngnOtptEnrgBn9 "NOx Tracking Active 100 Hour Engine Output Energy Bin 9: Accumulated Engine output energy while all NOx sensors are active over the current 100 hour block for Bin 9";
CM_ SG_ 2566591998 NOxTAtv100HEOtptEB10 "NOx Tracking Active 100 Hour Engine Output Energy Bin 10: Accumulated Engine output energy while all NOx sensors are active over the current 100 hour block for Bin 10";
CM_ SG_ 2566591998 NOxTAtv100HEOtptEB11 "NOx Tracking Active 100 Hour Engine Output Energy Bin 11: Accumulated Engine output energy while all NOx sensors are active over the current 100 hour block for Bin 11";
CM_ SG_ 2566591998 NOxTAtv100HEOtptEB12 "NOx Tracking Active 100 Hour Engine Output Energy Bin 12: Accumulated Engine output energy while all NOx sensors are active over the current 100 hour block for Bin 12";
CM_ SG_ 2566591998 NOxTAtv100HEOtptEB13 "NOx Tracking Active 100 Hour Engine Output Energy Bin 13: Accumulated Engine output energy while all NOx sensors are active over the current 100 hour block for Bin 13";
CM_ SG_ 2566591998 NOxTAtv100HEOtptEB14 "NOx Tracking Active 100 Hour Engine Output Energy Bin 14 : Accumulated Engine output energy while all NOx sensors are active over the current 100 hour block for Bin 14";
CM_ SG_ 2566591998 NOxTAtv100HEOtptEB15NTEBIN "NOx Tracking Active 100 Hour Engine Output Energy Bin 15 (NTE BIN) : Accumulated Engine output energy while all NOx sensors are active over the current 100 hour block for Bin 15 [Note Bin 15 is the NTE Bin]";
CM_ SG_ 2566591998 NOxTAtv100HEOtptEB16RB "NOx Tracking Active 100 Hour Engine Output Energy Bin 16 (Regen Bin) : Accumulated Engine output energy while all NOx sensors are active over the current 100 hour block for Bin 16 [Note Bin 16 is the Regen Bin]";
CM_ SG_ 2566591998 NOxTAtv100HEOtptEB17MILOB "NOx Tracking Active 100 Hour Engine Output Energy Bin 17 (MIL On Bin) : Accumulated Engine output energy while all NOx sensors are active over the current 100 hour block for Bin 17 [Note Bin 17 is the MIL On Bin]";
CM_ BO_ 2566592254 "NOx Tracking Active 100 Hour Engine Out NOx Mass Bins ";
CM_ SG_ 2566592254 NOxTAtv100HEOtNOxMssB1Tt "NOx Tracking Active 100 Hour Engine Out NOx Mass Bin 1 (Total): Accumulated Engine out NOx mass while all NOx sensors are active over the current 100 hour block for Bin 1 [Note Bin 1 is the total of Bins 2-14]";
CM_ SG_ 2566592254 NOxTrkngAtv100HrEngnOtNOxMssBn2 "NOx Tracking Active 100 Hour Engine Out NOx Mass Bin 2 : Accumulated Engine out NOx mass while all NOx sensors are active over the current 100 hour block for Bin 2 [Note Bin 2 is the 'idle' bin]";
CM_ SG_ 2566592254 NOxTrkngAtv100HrEngnOtNOxMssBn3 "NOx Tracking Active 100 Hour Engine Out NOx Mass Bin 3 : Accumulated Engine out NOx mass while all NOx sensors are active over the current 100 hour block for Bin 3. ";
CM_ SG_ 2566592254 NOxTrkngAtv100HrEngnOtNOxMssBn4 "NOx Tracking Active 100 Hour Engine Out NOx Mass Bin 4: Accumulated Engine out NOx mass while all NOx sensors are active over the current 100 hour block for Bin 4.";
CM_ SG_ 2566592254 NOxTrkngAtv100HrEngnOtNOxMssBn5 "NOx Tracking Active 100 Hour Engine Out NOx Mass Bin 5: Accumulated Engine out NOx mass while all NOx sensors are active over the current 100 hour block for Bin 5.";
CM_ SG_ 2566592254 NOxTrkngAtv100HrEngnOtNOxMssBn6 "NOx Tracking Active 100 Hour Engine Out NOx Mass Bin 6: Accumulated Engine out NOx mass while all NOx sensors are active over the current 100 hour block for Bin 6. ";
CM_ SG_ 2566592254 NOxTrkngAtv100HrEngnOtNOxMssBn7 "NOx Tracking Active 100 Hour Engine Out NOx Mass Bin 7: Accumulated Engine out NOx mass while all NOx sensors are active over the current 100 hour block for Bin 7. ";
CM_ SG_ 2566592254 NOxTrkngAtv100HrEngnOtNOxMssBn8 "NOx Tracking Active 100 Hour Engine Out NOx Mass Bin 8: Accumulated Engine out NOx mass while all NOx sensors are active over the current 100 hour block for Bin 8. ";
CM_ SG_ 2566592254 NOxTrkngAtv100HrEngnOtNOxMssBn9 "NOx Tracking Active 100 Hour Engine Out NOx Mass Bin 9: Accumulated Engine out NOx mass while all NOx sensors are active over the current 100 hour block for Bin 9";
CM_ SG_ 2566592254 NOxTAtv100HEOtNOxMssB10 "NOx Tracking Active 100 Hour Engine Out NOx Mass Bin 10: Accumulated Engine out NOx mass while all NOx sensors are active over the current 100 hour block for Bin 10";
CM_ SG_ 2566592254 NOxTAtv100HEOtNOxMssB11 "NOx Tracking Active 100 Hour Engine Out NOx Mass Bin 11: Accumulated Engine out NOx mass while all NOx sensors are active over the current 100 hour block for Bin 11";
CM_ SG_ 2566592254 NOxTAtv100HEOtNOxMssB12 "NOx Tracking Active 100 Hour Engine Out NOx Mass Bin 12: Accumulated Engine out NOx mass while all NOx sensors are active over the current 100 hour block for Bin 12";
CM_ SG_ 2566592254 NOxTAtv100HEOtNOxMssB13 "NOx Tracking Active 100 Hour Engine Out NOx Mass Bin 13: Accumulated Engine out NOx mass while all NOx sensors are active over the current 100 hour block for Bin 13";
CM_ SG_ 2566592254 NOxTAtv100HEOtNOxMssB14 "NOx Tracking Active 100 Hour Engine Out NOx Mass Bin 14 : Accumulated Engine out NOx mass while all NOx sensors are active over the current 100 hour block for Bin 14";
CM_ SG_ 2566592254 NOxTAtv100HEOtNOxMssB15NTEBIN "NOx Tracking Active 100 Hour Engine Out NOx Mass Bin 15 (NTE BIN) : Accumulated Engine out NOx mass while all NOx sensors are active over the current 100 hour block for Bin 15 [Note Bin 15 is the NTE Bin]";
CM_ SG_ 2566592254 NOxTAtv100HEOtNOxMssB16RB "NOx Tracking Active 100 Hour Engine Out NOx Mass Bin 16 (Regen Bin) : Accumulated Engine out NOx mass while all NOx sensors are active over the current 100 hour block for Bin 16 [Note Bin 16 is the Regen Bin]";
CM_ SG_ 2566592254 NOxTAtv100HEOtNOxMssB17MILOB "NOx Tracking Active 100 Hour Engine Out NOx Mass Bin 17 (MIL On Bin) : Accumulated Engine out NOx mass while all NOx sensors are active over the current 100 hour block for Bin 17 [Note Bin 17 the Mil On Bin]";
CM_ BO_ 2566592510 "NOx Tracking Active 100 Hour System Out NOx Mass Bins ";
CM_ SG_ 2566592510 NOxTAtv100HSstOtNOxMssB1Tt "NOx Tracking Active 100 Hour System Out NOx Mass Bin 1 (Total): Accumulated system out [SCR outlet] NOx mass while all NOx sensors are active over the current 100 hour block for Bin 1 [Note Bin 1 is the total of Bins 2-14]";
CM_ SG_ 2566592510 NOxTrkngAtv100HrSstmOtNOxMssBn2 "NOx Tracking Active 100 Hour System Out NOx Mass Bin 2 : Accumulated system out [SCR outlet] NOx mass while all NOx sensors are active over the current 100 hour block for Bin 2 [Note Bin 2 is the 'idle' bin]";
CM_ SG_ 2566592510 NOxTrkngAtv100HrSstmOtNOxMssBn3 "NOx Tracking Active 100 Hour System Out NOx Mass Bin 3 : Accumulated system out [SCR outlet] NOx mass while all NOx sensors are active over the current 100 hour block for Bin 3.";
CM_ SG_ 2566592510 NOxTrkngAtv100HrSstmOtNOxMssBn4 "NOx Tracking Active 100 Hour System Out NOx Mass Bin 4: Accumulated system out [SCR outlet] NOx mass while all NOx sensors are active over the current 100 hour block for Bin 4.";
CM_ SG_ 2566592510 NOxTrkngAtv100HrSstmOtNOxMssBn5 "NOx Tracking Active 100 Hour System Out NOx Mass Bin 5: Accumulated system out [SCR outlet] NOx mass while all NOx sensors are active over the current 100 hour block for Bin 5.";
CM_ SG_ 2566592510 NOxTrkngAtv100HrSstmOtNOxMssBn6 "NOx Tracking Active 100 Hour System Out NOx Mass Bin 6: Accumulated system out [SCR outlet] NOx mass while all NOx sensors are active over the current 100 hour block for Bin 6. ";
CM_ SG_ 2566592510 NOxTrkngAtv100HrSstmOtNOxMssBn7 "NOx Tracking Active 100 Hour System Out NOx Mass Bin 7: Accumulated system out [SCR outlet] NOx mass while all NOx sensors are active over the current 100 hour block for Bin 7. ";
CM_ SG_ 2566592510 NOxTrkngAtv100HrSstmOtNOxMssBn8 "NOx Tracking Active 100 Hour System Out NOx Mass Bin 8: Accumulated system out [SCR outlet] NOx mass while all NOx sensors are active over the current 100 hour block for Bin 8. ";
CM_ SG_ 2566592510 NOxTrkngAtv100HrSstmOtNOxMssBn9 "NOx Tracking Active 100 Hour System Out NOx Mass Bin 9: Accumulated system out [SCR outlet] NOx mass while all NOx sensors are active over the current 100 hour block for Bin 9";
CM_ SG_ 2566592510 NOxTAtv100HSstOtNOxMssB10 "NOx Tracking Active 100 Hour System Out NOx Mass Bin 10: Accumulated system out [SCR outlet] NOx mass while all NOx sensors are active over the current 100 hour block for Bin 10 ";
CM_ SG_ 2566592510 NOxTAtv100HSstOtNOxMssB11 "NOx Tracking Active 100 Hour System Out NOx Mass Bin 11: Accumulated system out [SCR outlet] NOx mass while all NOx sensors are active over the current 100 hour block for Bin 11";
CM_ SG_ 2566592510 NOxTAtv100HSstOtNOxMssB12 "NOx Tracking Active 100 Hour System Out NOx Mass Bin 12: Accumulated system out [SCR outlet] NOx mass while all NOx sensors are active over the current 100 hour block for Bin 12";
CM_ SG_ 2566592510 NOxTAtv100HSstOtNOxMssB13 "NOx Tracking Active 100 Hour System Out NOx Mass Bin 13: Accumulated system out [SCR outlet] NOx mass while all NOx sensors are active over the current 100 hour block for Bin 13";
CM_ SG_ 2566592510 NOxTAtv100HSstOtNOxMssB14 "NOx Tracking Active 100 Hour System Out NOx Mass Bin 14 : Accumulated system out [SCR outlet] NOx mass while all NOx sensors are active over the current 100 hour block for Bin 14";
CM_ SG_ 2566592510 NOxTAtv100HSstOtNOxMssB15NTEBIN "NOx Tracking Active 100 Hour System Out NOx Mass Bin 15 (NTE BIN) : Accumulated system out [SCR outlet] NOx mass while all NOx sensors are active over the current 100 hour block for Bin 15 [Note Bin 15 is the Regen Bin]";
CM_ SG_ 2566592510 NOxTAtv100HSstOtNOxMssB16RB "NOx Tracking Active 100 Hour System Out NOx Mass Bin 16 (Regen Bin) : Accumulated system out [SCR outlet] NOx mass while all NOx sensors are active over the current 100 hour block for Bin 16 [Note Bin 16 is the Regen Bin]";
CM_ SG_ 2566592510 NOxTAtv100HSstOtNOxMssB17MILOB "NOx Tracking Active 100 Hour System Out NOx Mass Bin 17 (MIL On Bin) : Accumulated system out [SCR outlet] NOx mass while all NOx sensors are active over the current 100 hour block for Bin 17 [Note Bin 17 is the MIL On Bin]";
CM_ BO_ 2365266174 "Motor/Generator 6 Inverter Control 2";
CM_ SG_ 2365266174 MtrGnrtr6InvrtrRtLmtsRqst2CRC "Motor/Generator 6 Inverter Rate Limits Request 2 CRC: The CRC is defined as follows:• Length: 8 bits• Polynomial: x^8+x^5+x^3+x^2+x+1• Initial Value: FFh• Input Data Reflection: Not reflected• Result Data Reflection: Not reflected• XOR value: FFhSAE ...";
CM_ SG_ 2365266174 MtrGnrtr6InvrtrRtLmtsRqst2Cntr "Motor/Generator 6 Inverter Rate Limits Request 2 Counter: The message counter is used to detect situations where the transmitting ECU malfunction repeats the same frame all the time. The receiver of the information may use the counter parameter to de...";
CM_ SG_ 2365266174 MtrGnrtr6InvrtrPIDCntrlAppllMd "Motor/Generator 6 Inverter PID Control Applicable Mode : Defines the Mode that the PID Gain parameters apply for this instance of the inverter.  See SPN 12172 [Control Setpoint Mode] for a definition of modes for control purposes.Applicable modes:000...";
CM_ SG_ 2365266174 MtGt6IvtPIDCtNzdDtG "Motor/Generator 6 Inverter PID Control Normalized Differential Gain: A PID controller can be parametrized by factors Kp, Ki and Kd. This parameter defines the normalized integral gain (Kin) for control applications in this inverter instance. The norm...";
CM_ SG_ 2365266174 MtGt6IvtPIDCtNzdItG "Motor/Generator 6 Inverter PID Control Normalized Integral Gain: A PID controller can be parametrized by factors Kp, Ki and Kd. This parameter defines the normalized integral gain (Kin) for control applications in this inverter instance. The normaliz...";
CM_ SG_ 2365266174 MtGt6IvtPIDCtNzdPptG "Motor/Generator 6 Inverter PID Control Normalized Proportional Gain: A PID controller can be parametrized by factors Kp, Ki and Kd. This parameter defines the normalized proportional gain (Kpn) for control applications in this inverter instance. The ...";
CM_ SG_ 2365266174 MtGt6IvtPIDCtFdFwdTq "Motor/Generator 6 Inverter PID Control Feed-Forward Torque: A PID controller can have a Feed-Forward Torque added to its output. This parameter defines the Feed-Forward Torque Setpoint for control applications in this inverter instance. The Setpoint ...";
CM_ BO_ 2566593022 "Motor/Generator 6 Inverter Limits Request Power";
CM_ SG_ 2566593022 MtrGnrtr6InvrtrLmtsRqstPwrCRC "Motor/Generator 6 Inverter Limits Request Power CRC: The CRC is defined as follows: • Length: 8 bits • Polynomial: x^8+x^5+x^3+x^2+x+1 • Initial Value: FFh • Input Data Reflection: Not reflected • Result Data Reflection: Not reflected • XOR value: FF...";
CM_ SG_ 2566593022 MtrGnrtr6InvrtrLmtsRqstPwrCntr "Motor/Generator 6 Inverter Limits Request Power Counter: The message counter is used to detect situations where the transmitting ECU malfunction repeats the same frame all the time. The receiver of the information may use the counter parameter to det...";
CM_ SG_ 2566593022 MtGt6IvtLtsRqstMPwMx "Motor/Generator 6 Inverter Limits Request Mechanical Power Maximum: This requests a maximum limit for the mechanical power.Refer to SPN 12177 [Reference Power] to convert % to kW. Request a value of FBFh to instruct the inverter to use its default va...";
CM_ SG_ 2566593022 MtGt6IvtLtsRqstMPwM "Motor/Generator 6 Inverter Limits Request Mechanical Power Minimum: This requests a minimum limit for the mechanical power.Refer to SPN 12177 [Reference Power] to convert % to kW. Request a value of FBFh to instruct the inverter to use its default va...";
CM_ SG_ 2566593022 MtGt6IvtLtsRqstDCSdPwMx "Motor/Generator 6 Inverter Limits Request DC Side Power Maximum: This requests a maximum limit for the DC Side power.Refer to SPN 12177 [Reference Power] to convert % to kW. Request a value of FBFh to instruct the inverter to use its default values.F...";
CM_ SG_ 2566593022 MtGt6IvtLtsRqstDCSdPwM "Motor/Generator 6 Inverter Limits Request DC Side Power Minimum: This requests a minimum limit for the DC Side power.Refer to SPN 12177 [Reference Power] to convert % to kW. Request a value of FBFh to instruct the inverter to use its default values.F...";
CM_ BO_ 2566593278 "Motor/Generator 6 Inverter Limits Request Mechanical";
CM_ SG_ 2566593278 MtrGnrtr6InvrtrLmtsRqstMhnlCRC "Motor/Generator 6 Inverter Limits Request Mechanical CRC: The CRC is defined as follows: • Length: 8 bits • Polynomial: x^8+x^5+x^3+x^2+x+1 • Initial Value: FFh • Input Data Reflection: Not reflected • Result Data Reflection: Not reflected • XOR valu...";
CM_ SG_ 2566593278 MtrGnrtr6InvrtrLmtsRqstMhnlCntr "Motor/Generator 6 Inverter Limits Request Mechanical Counter: The message counter is used to detect situations where the transmitting ECU malfunction repeats the same frame all the time. The receiver of the information may use the counter parameter t...";
CM_ SG_ 2566593278 MtrGnrtr6InvrtrLmtsRqstTrqMxmm "Motor/Generator 6 Inverter Limits Request Torque Maximum: This requests a maximum torque the inverter should command for this device.Refer to SPN 12175 [Reference Torque] to convert % to Nm. Request a value of FBFh to instruct the inverter to use its...";
CM_ SG_ 2566593278 MtrGnrtr6InvrtrLmtsRqstTrqMnmm "Motor/Generator 6 Inverter Limits Request Torque Minimum: This requests a minimum torque the inverter should command for this device.Refer to SPN 12175 [Reference Torque] to convert % to Nm. Request a value of FBFh to instruct the inverter to use its...";
CM_ SG_ 2566593278 MtrGnrtr6InvrtrLmtsRqstSpdMxmm "Motor/Generator 6 Inverter Limits Request Speed Maximum: This is a request to the inverter to set a maximum speed limit for this device.Refer to SPN 12176 [Reference Speed] to convert % to rpm. Request a value of FBFh to instruct the inverter to use ...";
CM_ SG_ 2566593278 MtrGnrtr6InvrtrLmtsRqstSpdMnmm "Motor/Generator 6 Inverter Limits Request Speed Minimum: This is a request to the inverter to set a minimum speed limit for this device.Refer to SPN 12176 [Reference Speed] to convert % to rpm. Request a value of FBFh to instruct the inverter to use ...";
CM_ BO_ 2566593534 "Motor/Generator 6 Inverter Limits Request DC Side";
CM_ SG_ 2566593534 MtrGnrtr6InvrtrLmtsRqstDCSdCRC "Motor/Generator 6 Inverter Limits Request DC Side CRC: The CRC is defined as follows: • Length: 8 bits • Polynomial: x^8+x^5+x^3+x^2+x+1 • Initial Value: FFh • Input Data Reflection: Not reflected • Result Data Reflection: Not reflected • XOR value: ...";
CM_ SG_ 2566593534 MtrGnrtr6InvrtrLmtsRqstDCSdCntr "Motor/Generator 6 Inverter Limits Request DC Side Counter: The message counter is used to detect situations where the transmitting ECU malfunction repeats the same frame all the time. The receiver of the information may use the counter parameter to d...";
CM_ SG_ 2566593534 MtGt6IvtLtsRqstDCSdVtMx "Motor/Generator 6 Inverter Limits Request DC Side Voltage Maximum: This is a request to the inverter to set a maximum DC Side Voltage limit for this device instance.Refer to SPN 12208 [Reference Voltage] to convert % to Volts. Request a value of FBFh...";
CM_ SG_ 2566593534 MtGt6IvtLtsRqstDCSdVtM "Motor/Generator 6 Inverter Limits Request DC Side Voltage Minimum: This is a request to the inverter to set a minimum DC Side Voltage limit for this device instance.Refer to SPN 12208 [Reference Voltage] to convert % to Volts. Request a value of FBFh...";
CM_ SG_ 2566593534 MtGt6IvtLtsRqstDCSdCtMx "Motor/Generator 6 Inverter Limits Request DC Side Current Maximum: This is a request to the inverter to set a maximum DC Side Current limit for this device instance.Refer to SPN 12207 [Reference Current] to convert % to Amps. Request a value of FBFh ...";
CM_ SG_ 2566593534 MtGt6IvtLtsRqstDCSdCtM "Motor/Generator 6 Inverter Limits Request DC Side Current Minimum: This is a request to the inverter to set a minimum DC Side Current limit for this device instance.Refer to SPN 12207 [Reference Current] to convert % to Amps. Request a value of FBFh ...";
CM_ BO_ 2566593790 "Motor/Generator 6 Inverter Isolation Integrity Request";
CM_ SG_ 2566593790 MtGt6IvtHVtBsAtvIstTstCd "Motor/Generator 6 Inverter High-Voltage Bus Active Isolation Test Command: Command for the inverter to perform an active electrical isolation test on the high voltage bus.An active isolation test might use a generated signal (e.g. an injected AC sign...";
CM_ SG_ 2566593790 MtGt6IvtHVtBsPssvIstTstCd "Motor/Generator 6 Inverter High-Voltage Bus Passive Isolation Test Command: Command for the inverter to perform a passive electrical isolation test on the high voltage bus.A passive isolation test uses additional circuitry (e.g. a high impedance netw...";
CM_ SG_ 2566593790 MtGt6IvtHVtBsHSdRsstCtRqst "Motor/Generator 6 Inverter High-Voltage Bus High Side Resistor Connect Request: This parameter is used to request connection of the inverter High-Voltage bus high side resistor in order to perform an isolation test. 00b = Connection not Requested01b ...";
CM_ SG_ 2566593790 MtGt6IvtHVtBsLwSdRsstCtRqst "Motor/Generator 6 Inverter High-Voltage Bus Low Side Resistor Connect Request: This parameter is used to request connection of the inverter High-Voltage bus low side resistor in order to perform an isolation test.  00b = Connection not Requested01b =...";
CM_ BO_ 2365267454 "Motor/Generator 5 Inverter Control 2";
CM_ SG_ 2365267454 MtrGnrtr5InvrtrRtLmtsRqst2CRC "Motor/Generator 5 Inverter Rate Limits Request 2 CRC: The CRC is defined as follows:• Length: 8 bits• Polynomial: x^8+x^5+x^3+x^2+x+1• Initial Value: FFh• Input Data Reflection: Not reflected• Result Data Reflection: Not reflected• XOR value: FFhSAE ...";
CM_ SG_ 2365267454 MtrGnrtr5InvrtrRtLmtsRqst2Cntr "Motor/Generator 5 Inverter Rate Limits Request 2 Counter: The message counter is used to detect situations where the transmitting ECU malfunction repeats the same frame all the time. The receiver of the information may use the counter parameter to de...";
CM_ SG_ 2365267454 MtrGnrtr5InvrtrPIDCntrlAppllMd "Motor/Generator 5 Inverter PID Control Applicable Mode : Defines the Mode that the PID Gain parameters apply for this instance of the inverter.  See SPN 12054 [Control Setpoint Mode] for a definition of modes for control purposes.Applicable modes:000...";
CM_ SG_ 2365267454 MtGt5IvtPIDCtNzdDtG "Motor/Generator 5 Inverter PID Control Normalized Differential Gain: A PID controller can be parametrized by factors Kp, Ki and Kd. This parameter defines the normalized integral gain (Kin) for control applications in this inverter instance. The norm...";
CM_ SG_ 2365267454 MtGt5IvtPIDCtNzdItG "Motor/Generator 5 Inverter PID Control Normalized Integral Gain: A PID controller can be parametrized by factors Kp, Ki and Kd. This parameter defines the normalized integral gain (Kin) for control applications in this inverter instance. The normaliz...";
CM_ SG_ 2365267454 MtGt5IvtPIDCtNzdPptG "Motor/Generator 5 Inverter PID Control Normalized Proportional Gain: A PID controller can be parametrized by factors Kp, Ki and Kd. This parameter defines the normalized proportional gain (Kpn) for control applications in this inverter instance. The ...";
CM_ SG_ 2365267454 MtGt5IvtPIDCtFdFwdTq "Motor/Generator 5 Inverter PID Control Feed-Forward Torque: A PID controller can have a Feed-Forward Torque added to its output. This parameter defines the Feed-Forward Torque Setpoint for control applications in this inverter instance. The Setpoint ...";
CM_ BO_ 2566594302 "Motor/Generator 5 Inverter Limits Request Power";
CM_ SG_ 2566594302 MtrGnrtr5InvrtrLmtsRqstPwrCRC "Motor/Generator 5 Inverter Limits Request Power CRC: The CRC is defined as follows: • Length: 8 bits • Polynomial: x^8+x^5+x^3+x^2+x+1 • Initial Value: FFh • Input Data Reflection: Not reflected • Result Data Reflection: Not reflected • XOR value: FF...";
CM_ SG_ 2566594302 MtrGnrtr5InvrtrLmtsRqstPwrCntr "Motor/Generator 5 Inverter Limits Request Power Counter: The message counter is used to detect situations where the transmitting ECU malfunction repeats the same frame all the time. The receiver of the information may use the counter parameter to det...";
CM_ SG_ 2566594302 MtGt5IvtLtsRqstMPwMx "Motor/Generator 5 Inverter Limits Request Mechanical Power Maximum: This requests a maximum limit for the mechanical power.Refer to SPN 12059 [Reference Power] to convert % to kW. Request a value of FBFh to instruct the inverter to use its default va...";
CM_ SG_ 2566594302 MtGt5IvtLtsRqstMPwM "Motor/Generator 5 Inverter Limits Request Mechanical Power Minimum: This requests a minimum limit for the mechanical power.Refer to SPN 12059 [Reference Power] to convert % to kW. Request a value of FBFh to instruct the inverter to use its default va...";
CM_ SG_ 2566594302 MtGt5IvtLtsRqstDCSdPwMx "Motor/Generator 5 Inverter Limits Request DC Side Power Maximum: This requests a maximum limit for the DC Side power.Refer to SPN 12059 [Reference Power] to convert % to kW. Request a value of FBFh to instruct the inverter to use its default values.F...";
CM_ SG_ 2566594302 MtGt5IvtLtsRqstDCSdPwM "Motor/Generator 5 Inverter Limits Request DC Side Power Minimum: This requests a minimum limit for the DC Side power.Refer to SPN 12059 [Reference Power] to convert % to kW. Request a value of FBFh to instruct the inverter to use its default values.F...";
CM_ BO_ 2566594558 "Motor/Generator 5 Inverter Limits Request Mechanical";
CM_ SG_ 2566594558 MtrGnrtr5InvrtrLmtsRqstMhnlCRC "Motor/Generator 5 Inverter Limits Request Mechanical CRC: The CRC is defined as follows: • Length: 8 bits • Polynomial: x^8+x^5+x^3+x^2+x+1 • Initial Value: FFh • Input Data Reflection: Not reflected • Result Data Reflection: Not reflected • XOR valu...";
CM_ SG_ 2566594558 MtrGnrtr5InvrtrLmtsRqstMhnlCntr "Motor/Generator 5 Inverter Limits Request Mechanical Counter: The message counter is used to detect situations where the transmitting ECU malfunction repeats the same frame all the time. The receiver of the information may use the counter parameter t...";
CM_ SG_ 2566594558 MtrGnrtr5InvrtrLmtsRqstTrqMxmm "Motor/Generator 5 Inverter Limits Request Torque Maximum: This requests a maximum torque the inverter should command for this device.Refer to SPN 12057 [Reference Torque] to convert % to Nm. Request a value of FBFh to instruct the inverter to use its...";
CM_ SG_ 2566594558 MtrGnrtr5InvrtrLmtsRqstTrqMnmm "Motor/Generator 5 Inverter Limits Request Torque Minimum: This requests a minimum torque the inverter should command for this device.Refer to SPN 12057 [Reference Torque] to convert % to Nm. Request a value of FBFh to instruct the inverter to use its...";
CM_ SG_ 2566594558 MtrGnrtr5InvrtrLmtsRqstSpdMxmm "Motor/Generator 5 Inverter Limits Request Speed Maximum: This is a request to the inverter to set a maximum speed limit for this device.Refer to SPN 12058 [Reference Speed] to convert % to rpm. Request a value of FBFh to instruct the inverter to use ...";
CM_ SG_ 2566594558 MtrGnrtr5InvrtrLmtsRqstSpdMnmm "Motor/Generator 5 Inverter Limits Request Speed Minimum: This is a request to the inverter to set a minimum speed limit for this device.Refer to SPN 12058 [Reference Speed] to convert % to rpm. Request a value of FBFh to instruct the inverter to use ...";
CM_ BO_ 2566594814 "Motor/Generator 5 Inverter Limits Request DC Side";
CM_ SG_ 2566594814 MtrGnrtr5InvrtrLmtsRqstDCSdCRC "Motor/Generator 5 Inverter Limits Request DC Side CRC: The CRC is defined as follows: • Length: 8 bits • Polynomial: x^8+x^5+x^3+x^2+x+1 • Initial Value: FFh • Input Data Reflection: Not reflected • Result Data Reflection: Not reflected • XOR value: ...";
CM_ SG_ 2566594814 MtrGnrtr5InvrtrLmtsRqstDCSdCntr "Motor/Generator 5 Inverter Limits Request DC Side Counter: The message counter is used to detect situations where the transmitting ECU malfunction repeats the same frame all the time. The receiver of the information may use the counter parameter to d...";
CM_ SG_ 2566594814 MtGt5IvtLtsRqstDCSdVtMx "Motor/Generator 5 Inverter Limits Request DC Side Voltage Maximum: This is a request to the inverter to set a maximum DC Side Voltage limit for this device instance.Refer to SPN 12090 [Reference Voltage] to convert % to Volts. Request a value of FBFh...";
CM_ SG_ 2566594814 MtGt5IvtLtsRqstDCSdVtM "Motor/Generator 5 Inverter Limits Request DC Side Voltage Minimum: This is a request to the inverter to set a minimum DC Side Voltage limit for this device instance.Refer to SPN 12090 [Reference Voltage] to convert % to Volts. Request a value of FBFh...";
CM_ SG_ 2566594814 MtGt5IvtLtsRqstDCSdCtMx "Motor/Generator 5 Inverter Limits Request DC Side Current Maximum: This is a request to the inverter to set a maximum DC Side Current limit for this device instance.Refer to SPN 12089 [Reference Current] to convert % to Amps. Request a value of FBFh ...";
CM_ SG_ 2566594814 MtGt5IvtLtsRqstDCSdCtM "Motor/Generator 5 Inverter Limits Request DC Side Current Minimum: This is a request to the inverter to set a minimum DC Side Current limit for this device instance.Refer to SPN 12089 [Reference Current] to convert % to Amps. Request a value of FBFh ...";
CM_ BO_ 2566595070 "Motor/Generator 5 Inverter Isolation Integrity Request";
CM_ SG_ 2566595070 MtGt5IvtHVtBsAtvIstTstCd "Motor/Generator 5 Inverter High-Voltage Bus Active Isolation Test Command: Command for the inverter to perform an active electrical isolation test on the high voltage bus.An active isolation test might use a generated signal (e.g. an injected AC sign...";
CM_ SG_ 2566595070 MtGt5IvtHVtBsPssvIstTstCd "Motor/Generator 5 Inverter High-Voltage Bus Passive Isolation Test Command: Command for the inverter to perform a passive electrical isolation test on the high voltage bus.A passive isolation test uses additional circuitry (e.g. a high impedance netw...";
CM_ SG_ 2566595070 MtGt5IvtHVtBsHSdRsstCtRqst "Motor/Generator 5 Inverter High-Voltage Bus High Side Resistor Connect Request: This parameter is used to request connection of the inverter High-Voltage bus high side resistor in order to perform an isolation test. 00b = Connection not Requested01b ...";
CM_ SG_ 2566595070 MtGt5IvtHVtBsLwSdRsstCtRqst "Motor/Generator 5 Inverter High-Voltage Bus Low Side Resistor Connect Request: This parameter is used to request connection of the inverter High-Voltage bus low side resistor in order to perform an isolation test.  00b = Connection not Requested01b =...";
CM_ BO_ 2365268734 "Motor/Generator 4 Inverter Control 2";
CM_ SG_ 2365268734 MtrGnrtr4InvrtrRtLmtsRqst2CRC "Motor/Generator 4 Inverter Rate Limits Request 2 CRC: The CRC is defined as follows:• Length: 8 bits• Polynomial: x^8+x^5+x^3+x^2+x+1• Initial Value: FFh• Input Data Reflection: Not reflected• Result Data Reflection: Not reflected• XOR value: FFhSAE ...";
CM_ SG_ 2365268734 MtrGnrtr4InvrtrRtLmtsRqst2Cntr "Motor/Generator 4 Inverter Rate Limits Request 2 Counter: The message counter is used to detect situations where the transmitting ECU malfunction repeats the same frame all the time. The receiver of the information may use the counter parameter to de...";
CM_ SG_ 2365268734 MtrGnrtr4InvrtrPIDCntrlAppllMd "Motor/Generator 4 Inverter PID Control Applicable Mode : Defines the Mode that the PID Gain parameters apply for this instance of the inverter.  See SPN 11936 [Control Setpoint Mode] for a definition of modes for control purposes.Applicable modes:000...";
CM_ SG_ 2365268734 MtGt4IvtPIDCtNzdDtG "Motor/Generator 4 Inverter PID Control Normalized Differential Gain: A PID controller can be parametrized by factors Kp, Ki and Kd. This parameter defines the normalized integral gain (Kin) for control applications in this inverter instance. The norm...";
CM_ SG_ 2365268734 MtGt4IvtPIDCtNzdItG "Motor/Generator 4 Inverter PID Control Normalized Integral Gain: A PID controller can be parametrized by factors Kp, Ki and Kd. This parameter defines the normalized integral gain (Kin) for control applications in this inverter instance. The normaliz...";
CM_ SG_ 2365268734 MtGt4IvtPIDCtNzdPptG "Motor/Generator 4 Inverter PID Control Normalized Proportional Gain: A PID controller can be parametrized by factors Kp, Ki and Kd. This parameter defines the normalized proportional gain (Kpn) for control applications in this inverter instance. The ...";
CM_ SG_ 2365268734 MtGt4IvtPIDCtFdFwdTq "Motor/Generator 4 Inverter PID Control Feed-Forward Torque: A PID controller can have a Feed-Forward Torque added to its output. This parameter defines the Feed-Forward Torque Setpoint for control applications in this inverter instance. The Setpoint ...";
CM_ BO_ 2566595582 "Motor/Generator 4 Inverter Limits Request Power";
CM_ SG_ 2566595582 MtrGnrtr4InvrtrLmtsRqstPwrCRC "Motor/Generator 4 Inverter Limits Request Power CRC: The CRC is defined as follows: • Length: 8 bits • Polynomial: x^8+x^5+x^3+x^2+x+1 • Initial Value: FFh • Input Data Reflection: Not reflected • Result Data Reflection: Not reflected • XOR value: FF...";
CM_ SG_ 2566595582 MtrGnrtr4InvrtrLmtsRqstPwrCntr "Motor/Generator 4 Inverter Limits Request Power Counter: The message counter is used to detect situations where the transmitting ECU malfunction repeats the same frame all the time. The receiver of the information may use the counter parameter to det...";
CM_ SG_ 2566595582 MtGt4IvtLtsRqstMPwMx "Motor/Generator 4 Inverter Limits Request Mechanical Power Maximum: This requests a maximum limit for the mechanical power.Refer to SPN 11941 [Reference Power] to convert % to kW. Request a value of FBFh to instruct the inverter to use its default va...";
CM_ SG_ 2566595582 MtGt4IvtLtsRqstMPwM "Motor/Generator 4 Inverter Limits Request Mechanical Power Minimum: This requests a minimum limit for the mechanical power.Refer to SPN 11941 [Reference Power] to convert % to kW. Request a value of FBFh to instruct the inverter to use its default va...";
CM_ SG_ 2566595582 MtGt4IvtLtsRqstDCSdPwMx "Motor/Generator 4 Inverter Limits Request DC Side Power Maximum: This requests a maximum limit for the DC Side power.Refer to SPN 11941 [Reference Power] to convert % to kW. Request a value of FBFh to instruct the inverter to use its default values.F...";
CM_ SG_ 2566595582 MtGt4IvtLtsRqstDCSdPwM "Motor/Generator 4 Inverter Limits Request DC Side Power Minimum: This requests a minimum limit for the DC Side power.Refer to SPN 11941 [Reference Power] to convert % to kW. Request a value of FBFh to instruct the inverter to use its default values.F...";
CM_ BO_ 2566595838 "Motor/Generator 4 Inverter Limits Request Mechanical";
CM_ SG_ 2566595838 MtrGnrtr4InvrtrLmtsRqstMhnlCRC "Motor/Generator 4 Inverter Limits Request Mechanical CRC: The CRC is defined as follows: • Length: 8 bits • Polynomial: x^8+x^5+x^3+x^2+x+1 • Initial Value: FFh • Input Data Reflection: Not reflected • Result Data Reflection: Not reflected • XOR valu...";
CM_ SG_ 2566595838 MtrGnrtr4InvrtrLmtsRqstMhnlCntr "Motor/Generator 4 Inverter Limits Request Mechanical Counter: The message counter is used to detect situations where the transmitting ECU malfunction repeats the same frame all the time. The receiver of the information may use the counter parameter t...";
CM_ SG_ 2566595838 MtrGnrtr4InvrtrLmtsRqstTrqMxmm "Motor/Generator 4 Inverter Limits Request Torque Maximum: This requests a maximum torque the inverter should command for this device.Refer to SPN 11939 [Reference Torque] to convert % to Nm. Request a value of FBFh to instruct the inverter to use its...";
CM_ SG_ 2566595838 MtrGnrtr4InvrtrLmtsRqstTrqMnmm "Motor/Generator 4 Inverter Limits Request Torque Minimum: This requests a minimum torque the inverter should command for this device.Refer to SPN 11939 [Reference Torque] to convert % to Nm. Request a value of FBFh to instruct the inverter to use its...";
CM_ SG_ 2566595838 MtrGnrtr4InvrtrLmtsRqstSpdMxmm "Motor/Generator 4 Inverter Limits Request Speed Maximum: This is a request to the inverter to set a maximum speed limit for this device.Refer to SPN 11940 [Reference Speed] to convert % to rpm. Request a value of FBFh to instruct the inverter to use ...";
CM_ SG_ 2566595838 MtrGnrtr4InvrtrLmtsRqstSpdMnmm "Motor/Generator 4 Inverter Limits Request Speed Minimum: This is a request to the inverter to set a minimum speed limit for this device.Refer to SPN 11940 [Reference Speed] to convert % to rpm. Request a value of FBFh to instruct the inverter to use ...";
CM_ BO_ 2566596094 "Motor/Generator 4 Inverter Limits Request DC Side";
CM_ SG_ 2566596094 MtrGnrtr4InvrtrLmtsRqstDCSdCRC "Motor/Generator 4 Inverter Limits Request DC Side CRC: The CRC is defined as follows: • Length: 8 bits • Polynomial: x^8+x^5+x^3+x^2+x+1 • Initial Value: FFh • Input Data Reflection: Not reflected • Result Data Reflection: Not reflected • XOR value: ...";
CM_ SG_ 2566596094 MtrGnrtr4InvrtrLmtsRqstDCSdCntr "Motor/Generator 4 Inverter Limits Request DC Side Counter: The message counter is used to detect situations where the transmitting ECU malfunction repeats the same frame all the time. The receiver of the information may use the counter parameter to d...";
CM_ SG_ 2566596094 MtGt4IvtLtsRqstDCSdVtMx "Motor/Generator 4 Inverter Limits Request DC Side Voltage Maximum: This is a request to the inverter to set a maximum DC Side Voltage limit for this device instance.Refer to SPN 11972 [Reference Voltage] to convert % to Volts. Request a value of FBFh...";
CM_ SG_ 2566596094 MtGt4IvtLtsRqstDCSdVtM "Motor/Generator 4 Inverter Limits Request DC Side Voltage Minimum: This is a request to the inverter to set a minimum DC Side Voltage limit for this device instance.Refer to SPN 11972 [Reference Voltage] to convert % to Volts. Request a value of FBFh...";
CM_ SG_ 2566596094 MtGt4IvtLtsRqstDCSdCtMx "Motor/Generator 4 Inverter Limits Request DC Side Current Maximum: This is a request to the inverter to set a maximum DC Side Current limit for this device instance.Refer to SPN 11971 [Reference Current] to convert % to Amps. Request a value of FBFh ...";
CM_ SG_ 2566596094 MtGt4IvtLtsRqstDCSdCtM "Motor/Generator 4 Inverter Limits Request DC Side Current Minimum: This is a request to the inverter to set a minimum DC Side Current limit for this device instance.Refer to SPN 11971 [Reference Current] to convert % to Amps. Request a value of FBFh ...";
CM_ BO_ 2566596350 "Motor/Generator 4 Inverter Isolation Integrity Request";
CM_ SG_ 2566596350 MtGt4IvtHVtBsAtvIstTstCd "Motor/Generator 4 Inverter High-Voltage Bus Active Isolation Test Command: Command for the inverter to perform an active electrical isolation test on the high voltage bus.An active isolation test might use a generated signal (e.g. an injected AC sign...";
CM_ SG_ 2566596350 MtGt4IvtHVtBsPssvIstTstCd "Motor/Generator 4 Inverter High-Voltage Bus Passive Isolation Test Command: Command for the inverter to perform a passive electrical isolation test on the high voltage bus.A passive isolation test uses additional circuitry (e.g. a high impedance netw...";
CM_ SG_ 2566596350 MtGt4IvtHVtBsHSdRsstCtRqst "Motor/Generator 4 Inverter High-Voltage Bus High Side Resistor Connect Request: This parameter is used to request connection of the inverter High-Voltage bus high side resistor in order to perform an isolation test. 00b = Connection not Requested01b ...";
CM_ SG_ 2566596350 MtGt4IvtHVtBsLwSdRsstCtRqst "Motor/Generator 4 Inverter High-Voltage Bus Low Side Resistor Connect Request: This parameter is used to request connection of the inverter High-Voltage bus low side resistor in order to perform an isolation test.  00b = Connection not Requested01b =...";
CM_ BO_ 2365270014 "Motor/Generator 3 Inverter Control 2";
CM_ SG_ 2365270014 MtrGnrtr3InvrtrRtLmtsRqst2CRC "Motor/Generator 3 Inverter Rate Limits Request 2 CRC: The CRC is defined as follows:• Length: 8 bits• Polynomial: x^8+x^5+x^3+x^2+x+1• Initial Value: FFh• Input Data Reflection: Not reflected• Result Data Reflection: Not reflected• XOR value: FFhSAE ...";
CM_ SG_ 2365270014 MtrGnrtr3InvrtrRtLmtsRqst2Cntr "Motor/Generator 3 Inverter Rate Limits Request 2 Counter: The message counter is used to detect situations where the transmitting ECU malfunction repeats the same frame all the time. The receiver of the information may use the counter parameter to de...";
CM_ SG_ 2365270014 MtrGnrtr3InvrtrPIDCntrlAppllMd "Motor/Generator 3 Inverter PID Control Applicable Mode : Defines the Mode that the PID Gain parameters apply for this instance of the inverter.  See SPN 11818 [Control Setpoint Mode] for a definition of modes for control purposes.Applicable modes:000...";
CM_ SG_ 2365270014 MtGt3IvtPIDCtNzdDtG "Motor/Generator 3 Inverter PID Control Normalized Differential Gain: A PID controller can be parametrized by factors Kp, Ki and Kd. This parameter defines the normalized integral gain (Kin) for control applications in this inverter instance. The norm...";
CM_ SG_ 2365270014 MtGt3IvtPIDCtNzdItG "Motor/Generator 3 Inverter PID Control Normalized Integral Gain: A PID controller can be parametrized by factors Kp, Ki and Kd. This parameter defines the normalized integral gain (Kin) for control applications in this inverter instance. The normaliz...";
CM_ SG_ 2365270014 MtGt3IvtPIDCtNzdPptG "Motor/Generator 3 Inverter PID Control Normalized Proportional Gain: A PID controller can be parametrized by factors Kp, Ki and Kd. This parameter defines the normalized proportional gain (Kpn) for control applications in this inverter instance. The ...";
CM_ SG_ 2365270014 MtGt3IvtPIDCtFdFwdTq "Motor/Generator 3 Inverter PID Control Feed-Forward Torque: A PID controller can have a Feed-Forward Torque added to its output. This parameter defines the Feed-Forward Torque Setpoint for control applications in this inverter instance. The Setpoint ...";
CM_ BO_ 2566596862 "Motor/Generator 3 Inverter Limits Request Power";
CM_ SG_ 2566596862 MtrGnrtr3InvrtrLmtsRqstPwrCRC "Motor/Generator 3 Inverter Limits Request Power CRC: The CRC is defined as follows: • Length: 8 bits • Polynomial: x^8+x^5+x^3+x^2+x+1 • Initial Value: FFh • Input Data Reflection: Not reflected • Result Data Reflection: Not reflected • XOR value: FF...";
CM_ SG_ 2566596862 MtrGnrtr3InvrtrLmtsRqstPwrCntr "Motor/Generator 3 Inverter Limits Request Power Counter: The message counter is used to detect situations where the transmitting ECU malfunction repeats the same frame all the time. The receiver of the information may use the counter parameter to det...";
CM_ SG_ 2566596862 MtGt3IvtLtsRqstMPwMx "Motor/Generator 3 Inverter Limits Request Mechanical Power Maximum: This requests a maximum limit for the mechanical power.Refer to SPN 11823 [Reference Power] to convert % to kW. Request a value of FBFh to instruct the inverter to use its default va...";
CM_ SG_ 2566596862 MtGt3IvtLtsRqstMPwM "Motor/Generator 3 Inverter Limits Request Mechanical Power Minimum: This requests a minimum limit for the mechanical power.Refer to SPN 11823 [Reference Power] to convert % to kW. Request a value of FBFh to instruct the inverter to use its default va...";
CM_ SG_ 2566596862 MtGt3IvtLtsRqstDCSdPwMx "Motor/Generator 3 Inverter Limits Request DC Side Power Maximum: This requests a maximum limit for the DC Side power.Refer to SPN 11823 [Reference Power] to convert % to kW. Request a value of FBFh to instruct the inverter to use its default values.F...";
CM_ SG_ 2566596862 MtGt3IvtLtsRqstDCSdPwM "Motor/Generator 3 Inverter Limits Request DC Side Power Minimum: This requests a minimum limit for the DC Side power.Refer to SPN 11823 [Reference Power] to convert % to kW. Request a value of FBFh to instruct the inverter to use its default values.F...";
CM_ BO_ 2566597118 "Motor/Generator 3 Inverter Limits Request Mechanical";
CM_ SG_ 2566597118 MtrGnrtr3InvrtrLmtsRqstMhnlCRC "Motor/Generator 3 Inverter Limits Request Mechanical CRC: The CRC is defined as follows: • Length: 8 bits • Polynomial: x^8+x^5+x^3+x^2+x+1 • Initial Value: FFh • Input Data Reflection: Not reflected • Result Data Reflection: Not reflected • XOR valu...";
CM_ SG_ 2566597118 MtrGnrtr3InvrtrLmtsRqstMhnlCntr "Motor/Generator 3 Inverter Limits Request Mechanical Counter: The message counter is used to detect situations where the transmitting ECU malfunction repeats the same frame all the time. The receiver of the information may use the counter parameter t...";
CM_ SG_ 2566597118 MtrGnrtr3InvrtrLmtsRqstTrqMxmm "Motor/Generator 3 Inverter Limits Request Torque Maximum: This requests a maximum torque the inverter should command for this device.Refer to SPN 11821 [Reference Torque] to convert % to Nm. Request a value of FBFh to instruct the inverter to use its...";
CM_ SG_ 2566597118 MtrGnrtr3InvrtrLmtsRqstTrqMnmm "Motor/Generator 3 Inverter Limits Request Torque Minimum: This requests a minimum torque the inverter should command for this device.Refer to SPN 11821 [Reference Torque] to convert % to Nm. Request a value of FBFh to instruct the inverter to use its...";
CM_ SG_ 2566597118 MtrGnrtr3InvrtrLmtsRqstSpdMxmm "Motor/Generator 3 Inverter Limits Request Speed Maximum: This is a request to the inverter to set a maximum speed limit for this device.Refer to SPN 11822 [Reference Speed] to convert % to rpm. Request a value of FBFh to instruct the inverter to use ...";
CM_ SG_ 2566597118 MtrGnrtr3InvrtrLmtsRqstSpdMnmm "Motor/Generator 3 Inverter Limits Request Speed Minimum: This is a request to the inverter to set a minimum speed limit for this device.Refer to SPN 11822 [Reference Speed] to convert % to rpm. Request a value of FBFh to instruct the inverter to use ...";
CM_ BO_ 2566597374 "Motor/Generator 3 Inverter Limits Request DC Side";
CM_ SG_ 2566597374 MtrGnrtr3InvrtrLmtsRqstDCSdCRC "Motor/Generator 3 Inverter Limits Request DC Side CRC: The CRC is defined as follows: • Length: 8 bits • Polynomial: x^8+x^5+x^3+x^2+x+1 • Initial Value: FFh • Input Data Reflection: Not reflected • Result Data Reflection: Not reflected • XOR value: ...";
CM_ SG_ 2566597374 MtrGnrtr3InvrtrLmtsRqstDCSdCntr "Motor/Generator 3 Inverter Limits Request DC Side Counter: The message counter is used to detect situations where the transmitting ECU malfunction repeats the same frame all the time. The receiver of the information may use the counter parameter to d...";
CM_ SG_ 2566597374 MtGt3IvtLtsRqstDCSdVtMx "Motor/Generator 3 Inverter Limits Request DC Side Voltage Maximum: This is a request to the inverter to set a maximum DC Side Voltage limit for this device instance.Refer to SPN 11854 [Reference Voltage] to convert % to Volts. Request a value of FBFh...";
CM_ SG_ 2566597374 MtGt3IvtLtsRqstDCSdVtM "Motor/Generator 3 Inverter Limits Request DC Side Voltage Minimum: This is a request to the inverter to set a minimum DC Side Voltage limit for this device instance.Refer to SPN 11854 [Reference Voltage] to convert % to Volts. Request a value of FBFh...";
CM_ SG_ 2566597374 MtGt3IvtLtsRqstDCSdCtMx "Motor/Generator 3 Inverter Limits Request DC Side Current Maximum: This is a request to the inverter to set a maximum DC Side Current limit for this device instance.Refer to SPN 11853 [Reference Current] to convert % to Amps. Request a value of FBFh ...";
CM_ SG_ 2566597374 MtGt3IvtLtsRqstDCSdCtM "Motor/Generator 3 Inverter Limits Request DC Side Current Minimum: This is a request to the inverter to set a minimum DC Side Current limit for this device instance.Refer to SPN 11853 [Reference Current] to convert % to Amps. Request a value of FBFh ...";
CM_ BO_ 2566597630 "Motor/Generator 3 Inverter Isolation Integrity Request";
CM_ SG_ 2566597630 MtGt3IvtHVtBsAtvIstTstCd "Motor/Generator 3 Inverter High-Voltage Bus Active Isolation Test Command: Command for the inverter to perform an active electrical isolation test on the high voltage bus.An active isolation test might use a generated signal (e.g. an injected AC sign...";
CM_ SG_ 2566597630 MtGt3IvtHVtBsPssvIstTstCd "Motor/Generator 3 Inverter High-Voltage Bus Passive Isolation Test Command: Command for the inverter to perform a passive electrical isolation test on the high voltage bus.A passive isolation test uses additional circuitry (e.g. a high impedance netw...";
CM_ SG_ 2566597630 MtGt3IvtHVtBsHSdRsstCtRqst "Motor/Generator 3 Inverter High-Voltage Bus High Side Resistor Connect Request: This parameter is used to request connection of the inverter High-Voltage bus high side resistor in order to perform an isolation test. 00b = Connection not Requested01b ...";
CM_ SG_ 2566597630 MtGt3IvtHVtBsLwSdRsstCtRqst "Motor/Generator 3 Inverter High-Voltage Bus Low Side Resistor Connect Request: This parameter is used to request connection of the inverter High-Voltage bus low side resistor in order to perform an isolation test.  00b = Connection not Requested01b =...";
CM_ BO_ 2566598142 "Turbocharger Information 8";
CM_ SG_ 2566598142 EngineTurbocharger5Speed "Engine Turbocharger 5 Speed: Rotational velocity of rotor in the turbocharger.";
CM_ SG_ 2566598142 EngineTurbocharger6Speed "Engine Turbocharger 6 Speed: Rotational velocity of rotor in the turbocharger.";
CM_ SG_ 2566598142 EngnTrhrgr5CmprssrIntkPrssr "Engine Turbocharger 5 Compressor Intake Pressure: Gage pressure of the air entering the compressor side of the turbocharger.";
CM_ SG_ 2566598142 EngnTrhrgr6CmprssrIntkPrssr "Engine Turbocharger 6 Compressor Intake Pressure: Gage pressure of the air entering the compressor side of the turbocharger.";
CM_ BO_ 2566598398 "Winch Information 2";
CM_ SG_ 2566598398 WinchLifetimeRevolutionCounter "Winch Lifetime Revolution Counter: Accumulated number of revolutions of winch motor during its operation. This includes both forward and reverse directions and may be used for maintenance purposes.";
CM_ BO_ 2365272062 "Motor/Generator 6 Inverter Reference 1";
CM_ SG_ 2365272062 MtrGnrtr6InvrtrRfrn1CRC "Motor/Generator 6 Inverter Reference 1 CRC: The CRC is defined as follows: • Length: 8 bits • Polynomial: x^8+x^5+x^3+x^2+x+1 • Initial Value: FFh • Input Data Reflection: Not reflected • Result Data Reflection: Not reflected • XOR value: FFhSAE make...";
CM_ SG_ 2365272062 MtrGnrtr6InvrtrRfrn1Cntr "Motor/Generator 6 Inverter Reference 1 Counter: The message counter is used to detect situations where the transmitting ECU malfunction repeats the same frame all the time. The receiver of the information may use the counter parameter to detect this ...";
CM_ SG_ 2365272062 MtrGnrtr6InvrtrRfrnTrq "Motor/Generator 6 Inverter Reference Torque: This value is used for converting torque in percent to units of Nm.Value in Nm = (Percent Value)/(100%) * (Reference Torque)For example, if this parameter has a value of 400 Nm and the percent value is equ...";
CM_ SG_ 2365272062 MtrGnrtr6InvrtrRfrnSpd "Motor/Generator 6 Inverter Reference Speed: This value is used for converting Speed in percent to units of rpm.Value in rpm = (Percent Value)/(100%) * (Reference Speed)For example, if this parameter has a value of 8192 rpm and the percent value is eq...";
CM_ SG_ 2365272062 MtrGnrtr6InvrtrRfrnPwr "Motor/Generator 6 Inverter Reference Power: This value is used for converting power in percent to units of kW.  It is applicable to both mechanical and electrical power.(Value in kW) = (Percent Value)/(100%) * (Reference Power)For example, if this pa...";
CM_ BO_ 2365272318 "Motor/Generator 6 Inverter Status 1";
CM_ SG_ 2365272318 MtrGnrtr6InvrtrStts1CRC "Motor/Generator 6 Inverter Status 1 CRC: The CRC is defined as follows: • Length: 8 bits • Polynomial: x^8+x^5+x^3+x^2+x+1 • Initial Value: FFh • Input Data Reflection: Not reflected • Result Data Reflection: Not reflected • XOR value: FFhSAE makes n...";
CM_ SG_ 2365272318 MtrGnrtr6InvrtrStts1Cntr "Motor/Generator 6 Inverter Status 1 Counter: The message counter is used to detect situations where the transmitting ECU malfunction repeats the same frame all the time. The receiver of the information may use the counter parameter to detect this sit...";
CM_ SG_ 2365272318 MotorGenerator6Torque "Motor/Generator 6 Torque: The measured or estimated motor torque.  This refers to the motor rotor output and excludes any gearbox that may be attached to the motor.Refer to SPN 12175 [Reference Torque] to convert % to Nm.The motor is generating when ...";
CM_ SG_ 2365272318 MotorGenerator6Speed "Motor/Generator 6 Speed: The measured or estimated motor speed.  This refers to the motor rotor output and excludes any gearbox that may be attached to the motor.   Refer to SPN 12176 [Reference Speed] to convert % to rpm.";
CM_ SG_ 2365272318 MtrGnrtr6InvrtrDCSdCrrnt "Motor/Generator 6 Inverter DC Side Current: This is the DC side current of the inverter.Refer to SPN 12207 [Reference Current] to convert % to Amps.While motoring, the current is defined as positive.  For example, in a hybrid propulsion system, posit...";
CM_ SG_ 2365272318 MtrGnrtr6InvrtrDCSdVltg "Motor/Generator 6 Inverter DC Side Voltage: The measured or estimated DC side voltage.  Refer to SPN 12208 [Reference Voltage] to convert % to Volts.";
BA_DEF_ SG_  "SPN" INT 0 524287;
BA_DEF_ BO_  "VFrameFormat" ENUM  "StandardCAN","ExtendedCAN","reserved","J1939PG";
BA_DEF_DEF_  "SPN" 0;
BA_DEF_DEF_  "VFrameFormat" "J1939PG";
BA_ "SPN" SG_ 2566587390 NOxTEAtvtLtERTB1Tt 12659;
BA_ "SPN" SG_ 2566587390 NOxTrkngEngnAtvtLftmEngnRnTmBn2 12660;
BA_ "SPN" SG_ 2566587390 NOxTrkngEngnAtvtLftmEngnRnTmBn3 12661;
BA_ "SPN" SG_ 2566587390 NOxTrkngEngnAtvtLftmEngnRnTmBn4 12662;
BA_ "SPN" SG_ 2566587390 NOxTrkngEngnAtvtLftmEngnRnTmBn5 12663;
BA_ "SPN" SG_ 2566587390 NOxTrkngEngnAtvtLftmEngnRnTmBn6 12664;
BA_ "SPN" SG_ 2566587390 NOxTrkngEngnAtvtLftmEngnRnTmBn7 12665;
BA_ "SPN" SG_ 2566587390 NOxTrkngEngnAtvtLftmEngnRnTmBn8 12666;
BA_ "SPN" SG_ 2566587390 NOxTrkngEngnAtvtLftmEngnRnTmBn9 12667;
BA_ "SPN" SG_ 2566587390 NOxTEAtvtLtERTB10 12668;
BA_ "SPN" SG_ 2566587390 NOxTEAtvtLtERTB11 12669;
BA_ "SPN" SG_ 2566587390 NOxTEAtvtLtERTB12 12670;
BA_ "SPN" SG_ 2566587390 NOxTEAtvtLtERTB13 12671;
BA_ "SPN" SG_ 2566587390 NOxTEAtvtLtERTB14 12672;
BA_ "SPN" SG_ 2566587390 NOxTEAtvtLtERTB15NTEBIN 12673;
BA_ "SPN" SG_ 2566587390 NOxTEAtvtLtERTB16RB 12674;
BA_ "SPN" SG_ 2566587390 NOxTEAtvtLtERTB17MILOB 12714;
BA_ "SPN" SG_ 2566587646 NOxTEAtvtLtVDstB1Tt 12643;
BA_ "SPN" SG_ 2566587646 NOxTrkngEngnAtvtLftmVhlDstnBn2 12644;
BA_ "SPN" SG_ 2566587646 NOxTrkngEngnAtvtLftmVhlDstnBn3 12645;
BA_ "SPN" SG_ 2566587646 NOxTrkngEngnAtvtLftmVhlDstnBn4 12646;
BA_ "SPN" SG_ 2566587646 NOxTrkngEngnAtvtLftmVhlDstnBn5 12647;
BA_ "SPN" SG_ 2566587646 NOxTrkngEngnAtvtLftmVhlDstnBn6 12648;
BA_ "SPN" SG_ 2566587646 NOxTrkngEngnAtvtLftmVhlDstnBn7 12649;
BA_ "SPN" SG_ 2566587646 NOxTrkngEngnAtvtLftmVhlDstnBn8 12650;
BA_ "SPN" SG_ 2566587646 NOxTrkngEngnAtvtLftmVhlDstnBn9 12651;
BA_ "SPN" SG_ 2566587646 NOxTrkngEngnAtvtLftmVhlDstnBn10 12652;
BA_ "SPN" SG_ 2566587646 NOxTrkngEngnAtvtLftmVhlDstnBn11 12653;
BA_ "SPN" SG_ 2566587646 NOxTrkngEngnAtvtLftmVhlDstnBn12 12654;
BA_ "SPN" SG_ 2566587646 NOxTrkngEngnAtvtLftmVhlDstnBn13 12655;
BA_ "SPN" SG_ 2566587646 NOxTrkngEngnAtvtLftmVhlDstnBn14 12656;
BA_ "SPN" SG_ 2566587646 NOxTEAtvtLtVDstB15NTEBIN 12657;
BA_ "SPN" SG_ 2566587646 NOxTEAtvtLtVDstB16RB 12658;
BA_ "SPN" SG_ 2566587646 NOxTEAtvtLtVDstB17MILOB 12728;
BA_ "SPN" SG_ 2566587902 NOxTEAtvtLtEOtptEB1Tt 12627;
BA_ "SPN" SG_ 2566587902 NOxTEAtvtLtEOtptEB2 12628;
BA_ "SPN" SG_ 2566587902 NOxTEAtvtLtEOtptEB3 12629;
BA_ "SPN" SG_ 2566587902 NOxTEAtvtLtEOtptEB4 12630;
BA_ "SPN" SG_ 2566587902 NOxTEAtvtLtEOtptEB5 12631;
BA_ "SPN" SG_ 2566587902 NOxTEAtvtLtEOtptEB6 12632;
BA_ "SPN" SG_ 2566587902 NOxTEAtvtLtEOtptEB7 12633;
BA_ "SPN" SG_ 2566587902 NOxTEAtvtLtEOtptEB8 12634;
BA_ "SPN" SG_ 2566587902 NOxTEAtvtLtEOtptEB9 12635;
BA_ "SPN" SG_ 2566587902 NOxTEAtvtLtEOtptEB10 12636;
BA_ "SPN" SG_ 2566587902 NOxTEAtvtLtEOtptEB11 12637;
BA_ "SPN" SG_ 2566587902 NOxTEAtvtLtEOtptEB12 12638;
BA_ "SPN" SG_ 2566587902 NOxTEAtvtLtEOtptEB13 12639;
BA_ "SPN" SG_ 2566587902 NOxTEAtvtLtEOtptEB14 12640;
BA_ "SPN" SG_ 2566587902 NOxTEAtvtLtEOtptEB15NTEBIN 12641;
BA_ "SPN" SG_ 2566587902 NOxTEAtvtLtEOtptEB16RB 12642;
BA_ "SPN" SG_ 2566587902 NOxTEAtvtLtEOtptEB17MILOB 12729;
BA_ "SPN" SG_ 2566588158 NOxTVdNOxLtFCsptB1Tt 12610;
BA_ "SPN" SG_ 2566588158 NOxTrkngVldNOxLftmFlCnsmptnBn2 12611;
BA_ "SPN" SG_ 2566588158 NOxTrkngVldNOxLftmFlCnsmptnBn3 12612;
BA_ "SPN" SG_ 2566588158 NOxTrkngVldNOxLftmFlCnsmptnBn4 12613;
BA_ "SPN" SG_ 2566588158 NOxTrkngVldNOxLftmFlCnsmptnBn5 12614;
BA_ "SPN" SG_ 2566588158 NOxTrkngVldNOxLftmFlCnsmptnBn6 12615;
BA_ "SPN" SG_ 2566588158 NOxTrkngVldNOxLftmFlCnsmptnBn7 12616;
BA_ "SPN" SG_ 2566588158 NOxTrkngVldNOxLftmFlCnsmptnBn8 12617;
BA_ "SPN" SG_ 2566588158 NOxTrkngVldNOxLftmFlCnsmptnBn9 12618;
BA_ "SPN" SG_ 2566588158 NOxTrkngVldNOxLftmFlCnsmptnBn10 12619;
BA_ "SPN" SG_ 2566588158 NOxTrkngVldNOxLftmFlCnsmptnBn11 12620;
BA_ "SPN" SG_ 2566588158 NOxTrkngVldNOxLftmFlCnsmptnBn12 12621;
BA_ "SPN" SG_ 2566588158 NOxTrkngVldNOxLftmFlCnsmptnBn13 12622;
BA_ "SPN" SG_ 2566588158 NOxTrkngVldNOxLftmFlCnsmptnBn14 12623;
BA_ "SPN" SG_ 2566588158 NOxTVdNOxLtFCsptB15NTEBIN 12624;
BA_ "SPN" SG_ 2566588158 NOxTVdNOxLtFCsptB16RB 12625;
BA_ "SPN" SG_ 2566588158 NOxTVdNOxLtFCsptB17MILOB 12626;
BA_ "SPN" SG_ 2566588414 NOxTVdNOxLtERTB1Tt 12593;
BA_ "SPN" SG_ 2566588414 NOxTrkngVldNOxLftmEngnRnTmBn2 12594;
BA_ "SPN" SG_ 2566588414 NOxTrkngVldNOxLftmEngnRnTmBn3 12595;
BA_ "SPN" SG_ 2566588414 NOxTrkngVldNOxLftmEngnRnTmBn4 12596;
BA_ "SPN" SG_ 2566588414 NOxTrkngVldNOxLftmEngnRnTmBn5 12597;
BA_ "SPN" SG_ 2566588414 NOxTrkngVldNOxLftmEngnRnTmBn6 12598;
BA_ "SPN" SG_ 2566588414 NOxTrkngVldNOxLftmEngnRnTmBn7 12599;
BA_ "SPN" SG_ 2566588414 NOxTrkngVldNOxLftmEngnRnTmBn8 12600;
BA_ "SPN" SG_ 2566588414 NOxTrkngVldNOxLftmEngnRnTmBn9 12601;
BA_ "SPN" SG_ 2566588414 NOxTrkngVldNOxLftmEngnRnTmBn10 12602;
BA_ "SPN" SG_ 2566588414 NOxTrkngVldNOxLftmEngnRnTmBn11 12603;
BA_ "SPN" SG_ 2566588414 NOxTrkngVldNOxLftmEngnRnTmBn12 12604;
BA_ "SPN" SG_ 2566588414 NOxTrkngVldNOxLftmEngnRnTmBn13 12605;
BA_ "SPN" SG_ 2566588414 NOxTrkngVldNOxLftmEngnRnTmBn14 12606;
BA_ "SPN" SG_ 2566588414 NOxTVdNOxLtERTB15NTEBIN 12607;
BA_ "SPN" SG_ 2566588414 NOxTVdNOxLtERTB16RB 12608;
BA_ "SPN" SG_ 2566588414 NOxTVdNOxLtERTB17MILOB 12609;
BA_ "SPN" SG_ 2566588670 NOxTrkngVldNOxLftmVhlDstnBn1Ttl 12576;
BA_ "SPN" SG_ 2566588670 NOxTrkngVldNOxLftmVhlDstnBn2 12577;
BA_ "SPN" SG_ 2566588670 NOxTrkngVldNOxLftmVhlDstnBn3 12578;
BA_ "SPN" SG_ 2566588670 NOxTrkngVldNOxLftmVhlDstnBn4 12579;
BA_ "SPN" SG_ 2566588670 NOxTrkngVldNOxLftmVhlDstnBn5 12580;
BA_ "SPN" SG_ 2566588670 NOxTrkngVldNOxLftmVhlDstnBn6 12581;
BA_ "SPN" SG_ 2566588670 NOxTrkngVldNOxLftmVhlDstnBn7 12582;
BA_ "SPN" SG_ 2566588670 NOxTrkngVldNOxLftmVhlDstnBn8 12583;
BA_ "SPN" SG_ 2566588670 NOxTrkngVldNOxLftmVhlDstnBn9 12584;
BA_ "SPN" SG_ 2566588670 NOxTrkngVldNOxLftmVhlDstnBn10 12585;
BA_ "SPN" SG_ 2566588670 NOxTrkngVldNOxLftmVhlDstnBn11 12586;
BA_ "SPN" SG_ 2566588670 NOxTrkngVldNOxLftmVhlDstnBn12 12587;
BA_ "SPN" SG_ 2566588670 NOxTrkngVldNOxLftmVhlDstnBn13 12588;
BA_ "SPN" SG_ 2566588670 NOxTrkngVldNOxLftmVhlDstnBn14 12589;
BA_ "SPN" SG_ 2566588670 NOxTVdNOxLtVDstB15NTEBIN 12590;
BA_ "SPN" SG_ 2566588670 NOxTVdNOxLtVDstB16RB 12591;
BA_ "SPN" SG_ 2566588670 NOxTVdNOxLtVDstB17MILOB 12592;
BA_ "SPN" SG_ 2566588926 NOxTVdNOxLtEOtptEB1Tt 12559;
BA_ "SPN" SG_ 2566588926 NOxTVdNOxLtEOtptEB2 12560;
BA_ "SPN" SG_ 2566588926 NOxTVdNOxLtEOtptEB3 12561;
BA_ "SPN" SG_ 2566588926 NOxTVdNOxLtEOtptEB4 12562;
BA_ "SPN" SG_ 2566588926 NOxTVdNOxLtEOtptEB5 12563;
BA_ "SPN" SG_ 2566588926 NOxTVdNOxLtEOtptEB6 12564;
BA_ "SPN" SG_ 2566588926 NOxTVdNOxLtEOtptEB7 12565;
BA_ "SPN" SG_ 2566588926 NOxTVdNOxLtEOtptEB8 12566;
BA_ "SPN" SG_ 2566588926 NOxTVdNOxLtEOtptEB9 12567;
BA_ "SPN" SG_ 2566588926 NOxTVdNOxLtEOtptEB10 12568;
BA_ "SPN" SG_ 2566588926 NOxTVdNOxLtEOtptEB11 12569;
BA_ "SPN" SG_ 2566588926 NOxTVdNOxLtEOtptEB12 12570;
BA_ "SPN" SG_ 2566588926 NOxTVdNOxLtEOtptEB13 12571;
BA_ "SPN" SG_ 2566588926 NOxTVdNOxLtEOtptEB14 12572;
BA_ "SPN" SG_ 2566588926 NOxTVdNOxLtEOtptEB15NTEBIN 12573;
BA_ "SPN" SG_ 2566588926 NOxTVdNOxLtEOtptEB16RB 12574;
BA_ "SPN" SG_ 2566588926 NOxTVdNOxLtEOtptEB17MILOB 12575;
BA_ "SPN" SG_ 2566589182 NOxTVdNOxLtEOtNOxMssB1Tt 12542;
BA_ "SPN" SG_ 2566589182 NOxTVdNOxLtEOtNOxMssB2 12543;
BA_ "SPN" SG_ 2566589182 NOxTVdNOxLtEOtNOxMssB3 12544;
BA_ "SPN" SG_ 2566589182 NOxTVdNOxLtEOtNOxMssB4 12545;
BA_ "SPN" SG_ 2566589182 NOxTVdNOxLtEOtNOxMssB5 12546;
BA_ "SPN" SG_ 2566589182 NOxTVdNOxLtEOtNOxMssB6 12547;
BA_ "SPN" SG_ 2566589182 NOxTVdNOxLtEOtNOxMssB7 12548;
BA_ "SPN" SG_ 2566589182 NOxTVdNOxLtEOtNOxMssB8 12549;
BA_ "SPN" SG_ 2566589182 NOxTVdNOxLtEOtNOxMssB9 12550;
BA_ "SPN" SG_ 2566589182 NOxTVdNOxLtEOtNOxMssB10 12551;
BA_ "SPN" SG_ 2566589182 NOxTVdNOxLtEOtNOxMssB11 12552;
BA_ "SPN" SG_ 2566589182 NOxTVdNOxLtEOtNOxMssB12 12553;
BA_ "SPN" SG_ 2566589182 NOxTVdNOxLtEOtNOxMssB13 12554;
BA_ "SPN" SG_ 2566589182 NOxTVdNOxLtEOtNOxMssB14 12555;
BA_ "SPN" SG_ 2566589182 NOxTVdNOxLtEOtNOxMssB15NTEBIN 12556;
BA_ "SPN" SG_ 2566589182 NOxTVdNOxLtEOtNOxMssB16RB 12557;
BA_ "SPN" SG_ 2566589182 NOxTVdNOxLtEOtNOxMssB17MILOB 12558;
BA_ "SPN" SG_ 2566589438 NOxTVdNOxLtSstOtNOxMssB1Tt 12525;
BA_ "SPN" SG_ 2566589438 NOxTVdNOxLtSstOtNOxMssB2 12526;
BA_ "SPN" SG_ 2566589438 NOxTVdNOxLtSstOtNOxMssB3 12527;
BA_ "SPN" SG_ 2566589438 NOxTVdNOxLtSstOtNOxMssB4 12528;
BA_ "SPN" SG_ 2566589438 NOxTVdNOxLtSstOtNOxMssB5 12529;
BA_ "SPN" SG_ 2566589438 NOxTVdNOxLtSstOtNOxMssB6 12530;
BA_ "SPN" SG_ 2566589438 NOxTVdNOxLtSstOtNOxMssB7 12531;
BA_ "SPN" SG_ 2566589438 NOxTVdNOxLtSstOtNOxMssB8 12532;
BA_ "SPN" SG_ 2566589438 NOxTVdNOxLtSstOtNOxMssB9 12533;
BA_ "SPN" SG_ 2566589438 NOxTVdNOxLtSstOtNOxMssB10 12534;
BA_ "SPN" SG_ 2566589438 NOxTVdNOxLtSstOtNOxMssB11 12535;
BA_ "SPN" SG_ 2566589438 NOxTVdNOxLtSstOtNOxMssB12 12536;
BA_ "SPN" SG_ 2566589438 NOxTVdNOxLtSstOtNOxMssB13 12537;
BA_ "SPN" SG_ 2566589438 NOxTVdNOxLtSstOtNOxMssB14 12538;
BA_ "SPN" SG_ 2566589438 NOxTVdNOxLtSstOtNOxMssB15NTEBIN 12539;
BA_ "SPN" SG_ 2566589438 NOxTVdNOxLtSstOtNOxMssB16RB 12540;
BA_ "SPN" SG_ 2566589438 NOxTVdNOxLtSstOtNOxMssB17MILOB 12541;
BA_ "SPN" SG_ 2566589694 NOxTStd100HFCsptB1Tt 12508;
BA_ "SPN" SG_ 2566589694 NOxTrkngStrd100HrFlCnsmptnBn2 12509;
BA_ "SPN" SG_ 2566589694 NOxTrkngStrd100HrFlCnsmptnBn3 12510;
BA_ "SPN" SG_ 2566589694 NOxTrkngStrd100HrFlCnsmptnBn4 12511;
BA_ "SPN" SG_ 2566589694 NOxTrkngStrd100HrFlCnsmptnBn5 12512;
BA_ "SPN" SG_ 2566589694 NOxTrkngStrd100HrFlCnsmptnBn6 12513;
BA_ "SPN" SG_ 2566589694 NOxTrkngStrd100HrFlCnsmptnBn7 12514;
BA_ "SPN" SG_ 2566589694 NOxTrkngStrd100HrFlCnsmptnBn8 12515;
BA_ "SPN" SG_ 2566589694 NOxTrkngStrd100HrFlCnsmptnBn9 12516;
BA_ "SPN" SG_ 2566589694 NOxTrkngStrd100HrFlCnsmptnBn10 12517;
BA_ "SPN" SG_ 2566589694 NOxTrkngStrd100HrFlCnsmptnBn11 12518;
BA_ "SPN" SG_ 2566589694 NOxTrkngStrd100HrFlCnsmptnBn12 12519;
BA_ "SPN" SG_ 2566589694 NOxTrkngStrd100HrFlCnsmptnBn13 12520;
BA_ "SPN" SG_ 2566589694 NOxTrkngStrd100HrFlCnsmptnBn14 12521;
BA_ "SPN" SG_ 2566589694 NOxTStd100HFCsptB15NTEBIN 12522;
BA_ "SPN" SG_ 2566589694 NOxTStd100HFCsptB16RB 12523;
BA_ "SPN" SG_ 2566589694 NOxTStd100HFCsptB17MILOB 12524;
BA_ "SPN" SG_ 2566589950 NOxTrkngStrd100HrEngnRnTmBn1Ttl 12491;
BA_ "SPN" SG_ 2566589950 NOxTrkngStrd100HrEngnRnTmBn2 12492;
BA_ "SPN" SG_ 2566589950 NOxTrkngStrd100HrEngnRnTmBn3 12493;
BA_ "SPN" SG_ 2566589950 NOxTrkngStrd100HrEngnRnTmBn4 12494;
BA_ "SPN" SG_ 2566589950 NOxTrkngStrd100HrEngnRnTmBn5 12495;
BA_ "SPN" SG_ 2566589950 NOxTrkngStrd100HrEngnRnTmBn6 12496;
BA_ "SPN" SG_ 2566589950 NOxTrkngStrd100HrEngnRnTmBn7 12497;
BA_ "SPN" SG_ 2566589950 NOxTrkngStrd100HrEngnRnTmBn8 12498;
BA_ "SPN" SG_ 2566589950 NOxTrkngStrd100HrEngnRnTmBn9 12499;
BA_ "SPN" SG_ 2566589950 NOxTrkngStrd100HrEngnRnTmBn10 12500;
BA_ "SPN" SG_ 2566589950 NOxTrkngStrd100HrEngnRnTmBn11 12501;
BA_ "SPN" SG_ 2566589950 NOxTrkngStrd100HrEngnRnTmBn12 12502;
BA_ "SPN" SG_ 2566589950 NOxTrkngStrd100HrEngnRnTmBn13 12503;
BA_ "SPN" SG_ 2566589950 NOxTrkngStrd100HrEngnRnTmBn14 12504;
BA_ "SPN" SG_ 2566589950 NOxTStd100HERTB15NTEBIN 12505;
BA_ "SPN" SG_ 2566589950 NOxTStd100HERTB16RB 12506;
BA_ "SPN" SG_ 2566589950 NOxTStd100HERTB17MILOB 12507;
BA_ "SPN" SG_ 2566590206 NOxTrkngStrd100HrVhlDstnBn1Ttl 12474;
BA_ "SPN" SG_ 2566590206 NOxTrkngStrd100HrVhlDstnBn2 12475;
BA_ "SPN" SG_ 2566590206 NOxTrkngStrd100HrVhlDstnBn3 12476;
BA_ "SPN" SG_ 2566590206 NOxTrkngStrd100HrVhlDstnBn4 12477;
BA_ "SPN" SG_ 2566590206 NOxTrkngStrd100HrVhlDstnBn5 12478;
BA_ "SPN" SG_ 2566590206 NOxTrkngStrd100HrVhlDstnBn6 12479;
BA_ "SPN" SG_ 2566590206 NOxTrkngStrd100HrVhlDstnBn7 12480;
BA_ "SPN" SG_ 2566590206 NOxTrkngStrd100HrVhlDstnBn8 12481;
BA_ "SPN" SG_ 2566590206 NOxTrkngStrd100HrVhlDstnBn9 12482;
BA_ "SPN" SG_ 2566590206 NOxTrkngStrd100HrVhlDstnBn10 12483;
BA_ "SPN" SG_ 2566590206 NOxTrkngStrd100HrVhlDstnBn11 12484;
BA_ "SPN" SG_ 2566590206 NOxTrkngStrd100HrVhlDstnBn12 12485;
BA_ "SPN" SG_ 2566590206 NOxTrkngStrd100HrVhlDstnBn13 12486;
BA_ "SPN" SG_ 2566590206 NOxTrkngStrd100HrVhlDstnBn14 12487;
BA_ "SPN" SG_ 2566590206 NOxTStd100HVDstB15NTEBIN 12488;
BA_ "SPN" SG_ 2566590206 NOxTStd100HVDstB16RB 12489;
BA_ "SPN" SG_ 2566590206 NOxTStd100HVDstB17MILOB 12490;
BA_ "SPN" SG_ 2566590462 NOxTStd100HEOtptEB1Tt 12457;
BA_ "SPN" SG_ 2566590462 NOxTStd100HEOtptEB2 12458;
BA_ "SPN" SG_ 2566590462 NOxTStd100HEOtptEB3 12459;
BA_ "SPN" SG_ 2566590462 NOxTStd100HEOtptEB4 12460;
BA_ "SPN" SG_ 2566590462 NOxTStd100HEOtptEB5 12461;
BA_ "SPN" SG_ 2566590462 NOxTStd100HEOtptEB6 12462;
BA_ "SPN" SG_ 2566590462 NOxTStd100HEOtptEB7 12463;
BA_ "SPN" SG_ 2566590462 NOxTStd100HEOtptEB8 12464;
BA_ "SPN" SG_ 2566590462 NOxTStd100HEOtptEB9 12465;
BA_ "SPN" SG_ 2566590462 NOxTStd100HEOtptEB10 12466;
BA_ "SPN" SG_ 2566590462 NOxTStd100HEOtptEB11 12467;
BA_ "SPN" SG_ 2566590462 NOxTStd100HEOtptEB12 12468;
BA_ "SPN" SG_ 2566590462 NOxTStd100HEOtptEB13 12469;
BA_ "SPN" SG_ 2566590462 NOxTStd100HEOtptEB14 12470;
BA_ "SPN" SG_ 2566590462 NOxTStd100HEOtptEB15NTEBIN 12471;
BA_ "SPN" SG_ 2566590462 NOxTStd100HEOtptEB16RB 12472;
BA_ "SPN" SG_ 2566590462 NOxTStd100HEOtptEB17MILOB 12473;
BA_ "SPN" SG_ 2566590718 NOxTStd100HEOtNOxMssB1Tt 12440;
BA_ "SPN" SG_ 2566590718 NOxTStd100HEOtNOxMssB2 12441;
BA_ "SPN" SG_ 2566590718 NOxTStd100HEOtNOxMssB3 12442;
BA_ "SPN" SG_ 2566590718 NOxTStd100HEOtNOxMssB4 12443;
BA_ "SPN" SG_ 2566590718 NOxTStd100HEOtNOxMssB5 12444;
BA_ "SPN" SG_ 2566590718 NOxTStd100HEOtNOxMssB6 12445;
BA_ "SPN" SG_ 2566590718 NOxTStd100HEOtNOxMssB7 12446;
BA_ "SPN" SG_ 2566590718 NOxTStd100HEOtNOxMssB8 12447;
BA_ "SPN" SG_ 2566590718 NOxTStd100HEOtNOxMssB9 12448;
BA_ "SPN" SG_ 2566590718 NOxTStd100HEOtNOxMssB10 12449;
BA_ "SPN" SG_ 2566590718 NOxTStd100HEOtNOxMssB11 12450;
BA_ "SPN" SG_ 2566590718 NOxTStd100HEOtNOxMssB12 12451;
BA_ "SPN" SG_ 2566590718 NOxTStd100HEOtNOxMssB13 12452;
BA_ "SPN" SG_ 2566590718 NOxTStd100HEOtNOxMssB14 12453;
BA_ "SPN" SG_ 2566590718 NOxTStd100HEOtNOxMssB15NTEBIN 12454;
BA_ "SPN" SG_ 2566590718 NOxTStd100HEOtNOxMssB16RB 12455;
BA_ "SPN" SG_ 2566590718 NOxTStd100HEOtNOxMssB17MILOB 12456;
BA_ "SPN" SG_ 2566590974 NOxTStd100HSstOtNOxMssB1Tt 12423;
BA_ "SPN" SG_ 2566590974 NOxTStd100HSstOtNOxMssB2 12424;
BA_ "SPN" SG_ 2566590974 NOxTStd100HSstOtNOxMssB3 12425;
BA_ "SPN" SG_ 2566590974 NOxTStd100HSstOtNOxMssB4 12426;
BA_ "SPN" SG_ 2566590974 NOxTStd100HSstOtNOxMssB5 12427;
BA_ "SPN" SG_ 2566590974 NOxTStd100HSstOtNOxMssB6 12428;
BA_ "SPN" SG_ 2566590974 NOxTStd100HSstOtNOxMssB7 12429;
BA_ "SPN" SG_ 2566590974 NOxTStd100HSstOtNOxMssB8 12430;
BA_ "SPN" SG_ 2566590974 NOxTStd100HSstOtNOxMssB9 12431;
BA_ "SPN" SG_ 2566590974 NOxTStd100HSstOtNOxMssB10 12432;
BA_ "SPN" SG_ 2566590974 NOxTStd100HSstOtNOxMssB11 12433;
BA_ "SPN" SG_ 2566590974 NOxTStd100HSstOtNOxMssB12 12434;
BA_ "SPN" SG_ 2566590974 NOxTStd100HSstOtNOxMssB13 12435;
BA_ "SPN" SG_ 2566590974 NOxTStd100HSstOtNOxMssB14 12436;
BA_ "SPN" SG_ 2566590974 NOxTStd100HSstOtNOxMssB15NTEBIN 12437;
BA_ "SPN" SG_ 2566590974 NOxTStd100HSstOtNOxMssB16RB 12438;
BA_ "SPN" SG_ 2566590974 NOxTStd100HSstOtNOxMssB17MILOB 12439;
BA_ "SPN" SG_ 2566591230 NOxTrkngAtv100HrFlCnsmptnBn1Ttl 12406;
BA_ "SPN" SG_ 2566591230 NOxTrkngAtv100HrFlCnsmptnBn2 12407;
BA_ "SPN" SG_ 2566591230 NOxTrkngAtv100HrFlCnsmptnBn3 12408;
BA_ "SPN" SG_ 2566591230 NOxTrkngAtv100HrFlCnsmptnBn4 12409;
BA_ "SPN" SG_ 2566591230 NOxTrkngAtv100HrFlCnsmptnBn5 12410;
BA_ "SPN" SG_ 2566591230 NOxTrkngAtv100HrFlCnsmptnBn6 12411;
BA_ "SPN" SG_ 2566591230 NOxTrkngAtv100HrFlCnsmptnBn7 12412;
BA_ "SPN" SG_ 2566591230 NOxTrkngAtv100HrFlCnsmptnBn8 12413;
BA_ "SPN" SG_ 2566591230 NOxTrkngAtv100HrFlCnsmptnBn9 12414;
BA_ "SPN" SG_ 2566591230 NOxTrkngAtv100HrFlCnsmptnBn10 12415;
BA_ "SPN" SG_ 2566591230 NOxTrkngAtv100HrFlCnsmptnBn11 12416;
BA_ "SPN" SG_ 2566591230 NOxTrkngAtv100HrFlCnsmptnBn12 12417;
BA_ "SPN" SG_ 2566591230 NOxTrkngAtv100HrFlCnsmptnBn13 12418;
BA_ "SPN" SG_ 2566591230 NOxTrkngAtv100HrFlCnsmptnBn14 12419;
BA_ "SPN" SG_ 2566591230 NOxTAtv100HFCsptB15NTEBIN 12420;
BA_ "SPN" SG_ 2566591230 NOxTAtv100HFCsptB16RB 12421;
BA_ "SPN" SG_ 2566591230 NOxTAtv100HFCsptB17MILOB 12422;
BA_ "SPN" SG_ 2566591486 NOxTrkngAtv100HrEngnRnTmBn1Ttl 12389;
BA_ "SPN" SG_ 2566591486 NOxTrkngAtv100HrEngnRnTmBn2 12390;
BA_ "SPN" SG_ 2566591486 NOxTrkngAtv100HrEngnRnTmBn3 12391;
BA_ "SPN" SG_ 2566591486 NOxTrkngAtv100HrEngnRnTmBn4 12392;
BA_ "SPN" SG_ 2566591486 NOxTrkngAtv100HrEngnRnTmBn5 12393;
BA_ "SPN" SG_ 2566591486 NOxTrkngAtv100HrEngnRnTmBn6 12394;
BA_ "SPN" SG_ 2566591486 NOxTrkngAtv100HrEngnRnTmBn7 12395;
BA_ "SPN" SG_ 2566591486 NOxTrkngAtv100HrEngnRnTmBn8 12396;
BA_ "SPN" SG_ 2566591486 NOxTrkngAtv100HrEngnRnTmBn9 12397;
BA_ "SPN" SG_ 2566591486 NOxTrkngAtv100HrEngnRnTmBn10 12398;
BA_ "SPN" SG_ 2566591486 NOxTrkngAtv100HrEngnRnTmBn11 12399;
BA_ "SPN" SG_ 2566591486 NOxTrkngAtv100HrEngnRnTmBn12 12400;
BA_ "SPN" SG_ 2566591486 NOxTrkngAtv100HrEngnRnTmBn13 12401;
BA_ "SPN" SG_ 2566591486 NOxTrkngAtv100HrEngnRnTmBn14 12402;
BA_ "SPN" SG_ 2566591486 NOxTAtv100HERTB15NTEBIN 12403;
BA_ "SPN" SG_ 2566591486 NOxTAtv100HERTB16RB 12404;
BA_ "SPN" SG_ 2566591486 NOxTAtv100HERTB17MILOB 12405;
BA_ "SPN" SG_ 2566591742 NOxTrkngAtv100HrVhlDstnBn1Ttl 12372;
BA_ "SPN" SG_ 2566591742 NOxTrkngAtv100HrVhlDstnBn2 12373;
BA_ "SPN" SG_ 2566591742 NOxTrkngAtv100HrVhlDstnBn3 12374;
BA_ "SPN" SG_ 2566591742 NOxTrkngAtv100HrVhlDstnBn4 12375;
BA_ "SPN" SG_ 2566591742 NOxTrkngAtv100HrVhlDstnBn5 12376;
BA_ "SPN" SG_ 2566591742 NOxTrkngAtv100HrVhlDstnBn6 12377;
BA_ "SPN" SG_ 2566591742 NOxTrkngAtv100HrVhlDstnBn7 12378;
BA_ "SPN" SG_ 2566591742 NOxTrkngAtv100HrVhlDstnBn8 12379;
BA_ "SPN" SG_ 2566591742 NOxTrkngAtv100HrVhlDstnBn9 12380;
BA_ "SPN" SG_ 2566591742 NOxTrkngAtv100HrVhlDstnBn10 12381;
BA_ "SPN" SG_ 2566591742 NOxTrkngAtv100HrVhlDstnBn11 12382;
BA_ "SPN" SG_ 2566591742 NOxTrkngAtv100HrVhlDstnBn12 12383;
BA_ "SPN" SG_ 2566591742 NOxTrkngAtv100HrVhlDstnBn13 12384;
BA_ "SPN" SG_ 2566591742 NOxTrkngAtv100HrVhlDstnBn14 12385;
BA_ "SPN" SG_ 2566591742 NOxTAtv100HVDstB15NTEBIN 12386;
BA_ "SPN" SG_ 2566591742 NOxTAtv100HVDstB16RB 12387;
BA_ "SPN" SG_ 2566591742 NOxTAtv100HVDstB17MILOB 12388;
BA_ "SPN" SG_ 2566591998 NOxTAtv100HEOtptEB1Tt 12355;
BA_ "SPN" SG_ 2566591998 NOxTrkngAtv100HrEngnOtptEnrgBn2 12356;
BA_ "SPN" SG_ 2566591998 NOxTrkngAtv100HrEngnOtptEnrgBn3 12357;
BA_ "SPN" SG_ 2566591998 NOxTrkngAtv100HrEngnOtptEnrgBn4 12358;
BA_ "SPN" SG_ 2566591998 NOxTrkngAtv100HrEngnOtptEnrgBn5 12359;
BA_ "SPN" SG_ 2566591998 NOxTrkngAtv100HrEngnOtptEnrgBn6 12360;
BA_ "SPN" SG_ 2566591998 NOxTrkngAtv100HrEngnOtptEnrgBn7 12361;
BA_ "SPN" SG_ 2566591998 NOxTrkngAtv100HrEngnOtptEnrgBn8 12362;
BA_ "SPN" SG_ 2566591998 NOxTrkngAtv100HrEngnOtptEnrgBn9 12363;
BA_ "SPN" SG_ 2566591998 NOxTAtv100HEOtptEB10 12364;
BA_ "SPN" SG_ 2566591998 NOxTAtv100HEOtptEB11 12365;
BA_ "SPN" SG_ 2566591998 NOxTAtv100HEOtptEB12 12366;
BA_ "SPN" SG_ 2566591998 NOxTAtv100HEOtptEB13 12367;
BA_ "SPN" SG_ 2566591998 NOxTAtv100HEOtptEB14 12368;
BA_ "SPN" SG_ 2566591998 NOxTAtv100HEOtptEB15NTEBIN 12369;
BA_ "SPN" SG_ 2566591998 NOxTAtv100HEOtptEB16RB 12370;
BA_ "SPN" SG_ 2566591998 NOxTAtv100HEOtptEB17MILOB 12371;
BA_ "SPN" SG_ 2566592254 NOxTAtv100HEOtNOxMssB1Tt 12338;
BA_ "SPN" SG_ 2566592254 NOxTrkngAtv100HrEngnOtNOxMssBn2 12339;
BA_ "SPN" SG_ 2566592254 NOxTrkngAtv100HrEngnOtNOxMssBn3 12340;
BA_ "SPN" SG_ 2566592254 NOxTrkngAtv100HrEngnOtNOxMssBn4 12341;
BA_ "SPN" SG_ 2566592254 NOxTrkngAtv100HrEngnOtNOxMssBn5 12342;
BA_ "SPN" SG_ 2566592254 NOxTrkngAtv100HrEngnOtNOxMssBn6 12343;
BA_ "SPN" SG_ 2566592254 NOxTrkngAtv100HrEngnOtNOxMssBn7 12344;
BA_ "SPN" SG_ 2566592254 NOxTrkngAtv100HrEngnOtNOxMssBn8 12345;
BA_ "SPN" SG_ 2566592254 NOxTrkngAtv100HrEngnOtNOxMssBn9 12346;
BA_ "SPN" SG_ 2566592254 NOxTAtv100HEOtNOxMssB10 12347;
BA_ "SPN" SG_ 2566592254 NOxTAtv100HEOtNOxMssB11 12348;
BA_ "SPN" SG_ 2566592254 NOxTAtv100HEOtNOxMssB12 12349;
BA_ "SPN" SG_ 2566592254 NOxTAtv100HEOtNOxMssB13 12350;
BA_ "SPN" SG_ 2566592254 NOxTAtv100HEOtNOxMssB14 12351;
BA_ "SPN" SG_ 2566592254 NOxTAtv100HEOtNOxMssB15NTEBIN 12352;
BA_ "SPN" SG_ 2566592254 NOxTAtv100HEOtNOxMssB16RB 12353;
BA_ "SPN" SG_ 2566592254 NOxTAtv100HEOtNOxMssB17MILOB 12354;
BA_ "SPN" SG_ 2566592510 NOxTAtv100HSstOtNOxMssB1Tt 12321;
BA_ "SPN" SG_ 2566592510 NOxTrkngAtv100HrSstmOtNOxMssBn2 12322;
BA_ "SPN" SG_ 2566592510 NOxTrkngAtv100HrSstmOtNOxMssBn3 12323;
BA_ "SPN" SG_ 2566592510 NOxTrkngAtv100HrSstmOtNOxMssBn4 12324;
BA_ "SPN" SG_ 2566592510 NOxTrkngAtv100HrSstmOtNOxMssBn5 12325;
BA_ "SPN" SG_ 2566592510 NOxTrkngAtv100HrSstmOtNOxMssBn6 12326;
BA_ "SPN" SG_ 2566592510 NOxTrkngAtv100HrSstmOtNOxMssBn7 12327;
BA_ "SPN" SG_ 2566592510 NOxTrkngAtv100HrSstmOtNOxMssBn8 12328;
BA_ "SPN" SG_ 2566592510 NOxTrkngAtv100HrSstmOtNOxMssBn9 12329;
BA_ "SPN" SG_ 2566592510 NOxTAtv100HSstOtNOxMssB10 12330;
BA_ "SPN" SG_ 2566592510 NOxTAtv100HSstOtNOxMssB11 12331;
BA_ "SPN" SG_ 2566592510 NOxTAtv100HSstOtNOxMssB12 12332;
BA_ "SPN" SG_ 2566592510 NOxTAtv100HSstOtNOxMssB13 12333;
BA_ "SPN" SG_ 2566592510 NOxTAtv100HSstOtNOxMssB14 12334;
BA_ "SPN" SG_ 2566592510 NOxTAtv100HSstOtNOxMssB15NTEBIN 12335;
BA_ "SPN" SG_ 2566592510 NOxTAtv100HSstOtNOxMssB16RB 12336;
BA_ "SPN" SG_ 2566592510 NOxTAtv100HSstOtNOxMssB17MILOB 12337;
BA_ "SPN" SG_ 2365266174 MtrGnrtr6InvrtrRtLmtsRqst2CRC 12266;
BA_ "SPN" SG_ 2365266174 MtrGnrtr6InvrtrRtLmtsRqst2Cntr 12267;
BA_ "SPN" SG_ 2365266174 MtrGnrtr6InvrtrPIDCntrlAppllMd 12268;
BA_ "SPN" SG_ 2365266174 MtGt6IvtPIDCtNzdDtG 12269;
BA_ "SPN" SG_ 2365266174 MtGt6IvtPIDCtNzdItG 12270;
BA_ "SPN" SG_ 2365266174 MtGt6IvtPIDCtNzdPptG 12271;
BA_ "SPN" SG_ 2365266174 MtGt6IvtPIDCtFdFwdTq 12272;
BA_ "SPN" SG_ 2566593022 MtrGnrtr6InvrtrLmtsRqstPwrCRC 12181;
BA_ "SPN" SG_ 2566593022 MtrGnrtr6InvrtrLmtsRqstPwrCntr 12182;
BA_ "SPN" SG_ 2566593022 MtGt6IvtLtsRqstMPwMx 12183;
BA_ "SPN" SG_ 2566593022 MtGt6IvtLtsRqstMPwM 12184;
BA_ "SPN" SG_ 2566593022 MtGt6IvtLtsRqstDCSdPwMx 12185;
BA_ "SPN" SG_ 2566593022 MtGt6IvtLtsRqstDCSdPwM 12186;
BA_ "SPN" SG_ 2566593278 MtrGnrtr6InvrtrLmtsRqstMhnlCRC 12193;
BA_ "SPN" SG_ 2566593278 MtrGnrtr6InvrtrLmtsRqstMhnlCntr 12194;
BA_ "SPN" SG_ 2566593278 MtrGnrtr6InvrtrLmtsRqstTrqMxmm 12195;
BA_ "SPN" SG_ 2566593278 MtrGnrtr6InvrtrLmtsRqstTrqMnmm 12196;
BA_ "SPN" SG_ 2566593278 MtrGnrtr6InvrtrLmtsRqstSpdMxmm 12197;
BA_ "SPN" SG_ 2566593278 MtrGnrtr6InvrtrLmtsRqstSpdMnmm 12198;
BA_ "SPN" SG_ 2566593534 MtrGnrtr6InvrtrLmtsRqstDCSdCRC 12209;
BA_ "SPN" SG_ 2566593534 MtrGnrtr6InvrtrLmtsRqstDCSdCntr 12210;
BA_ "SPN" SG_ 2566593534 MtGt6IvtLtsRqstDCSdVtMx 12211;
BA_ "SPN" SG_ 2566593534 MtGt6IvtLtsRqstDCSdVtM 12212;
BA_ "SPN" SG_ 2566593534 MtGt6IvtLtsRqstDCSdCtMx 12213;
BA_ "SPN" SG_ 2566593534 MtGt6IvtLtsRqstDCSdCtM 12214;
BA_ "SPN" SG_ 2566593790 MtGt6IvtHVtBsAtvIstTstCd 12232;
BA_ "SPN" SG_ 2566593790 MtGt6IvtHVtBsPssvIstTstCd 12233;
BA_ "SPN" SG_ 2566593790 MtGt6IvtHVtBsHSdRsstCtRqst 12234;
BA_ "SPN" SG_ 2566593790 MtGt6IvtHVtBsLwSdRsstCtRqst 12235;
BA_ "SPN" SG_ 2365267454 MtrGnrtr5InvrtrRtLmtsRqst2CRC 12148;
BA_ "SPN" SG_ 2365267454 MtrGnrtr5InvrtrRtLmtsRqst2Cntr 12149;
BA_ "SPN" SG_ 2365267454 MtrGnrtr5InvrtrPIDCntrlAppllMd 12150;
BA_ "SPN" SG_ 2365267454 MtGt5IvtPIDCtNzdDtG 12151;
BA_ "SPN" SG_ 2365267454 MtGt5IvtPIDCtNzdItG 12152;
BA_ "SPN" SG_ 2365267454 MtGt5IvtPIDCtNzdPptG 12153;
BA_ "SPN" SG_ 2365267454 MtGt5IvtPIDCtFdFwdTq 12154;
BA_ "SPN" SG_ 2566594302 MtrGnrtr5InvrtrLmtsRqstPwrCRC 12063;
BA_ "SPN" SG_ 2566594302 MtrGnrtr5InvrtrLmtsRqstPwrCntr 12064;
BA_ "SPN" SG_ 2566594302 MtGt5IvtLtsRqstMPwMx 12065;
BA_ "SPN" SG_ 2566594302 MtGt5IvtLtsRqstMPwM 12066;
BA_ "SPN" SG_ 2566594302 MtGt5IvtLtsRqstDCSdPwMx 12067;
BA_ "SPN" SG_ 2566594302 MtGt5IvtLtsRqstDCSdPwM 12068;
BA_ "SPN" SG_ 2566594558 MtrGnrtr5InvrtrLmtsRqstMhnlCRC 12075;
BA_ "SPN" SG_ 2566594558 MtrGnrtr5InvrtrLmtsRqstMhnlCntr 12076;
BA_ "SPN" SG_ 2566594558 MtrGnrtr5InvrtrLmtsRqstTrqMxmm 12077;
BA_ "SPN" SG_ 2566594558 MtrGnrtr5InvrtrLmtsRqstTrqMnmm 12078;
BA_ "SPN" SG_ 2566594558 MtrGnrtr5InvrtrLmtsRqstSpdMxmm 12079;
BA_ "SPN" SG_ 2566594558 MtrGnrtr5InvrtrLmtsRqstSpdMnmm 12080;
BA_ "SPN" SG_ 2566594814 MtrGnrtr5InvrtrLmtsRqstDCSdCRC 12091;
BA_ "SPN" SG_ 2566594814 MtrGnrtr5InvrtrLmtsRqstDCSdCntr 12092;
BA_ "SPN" SG_ 2566594814 MtGt5IvtLtsRqstDCSdVtMx 12093;
BA_ "SPN" SG_ 2566594814 MtGt5IvtLtsRqstDCSdVtM 12094;
BA_ "SPN" SG_ 2566594814 MtGt5IvtLtsRqstDCSdCtMx 12095;
BA_ "SPN" SG_ 2566594814 MtGt5IvtLtsRqstDCSdCtM 12096;
BA_ "SPN" SG_ 2566595070 MtGt5IvtHVtBsAtvIstTstCd 12114;
BA_ "SPN" SG_ 2566595070 MtGt5IvtHVtBsPssvIstTstCd 12115;
BA_ "SPN" SG_ 2566595070 MtGt5IvtHVtBsHSdRsstCtRqst 12116;
BA_ "SPN" SG_ 2566595070 MtGt5IvtHVtBsLwSdRsstCtRqst 12117;
BA_ "SPN" SG_ 2365268734 MtrGnrtr4InvrtrRtLmtsRqst2CRC 12030;
BA_ "SPN" SG_ 2365268734 MtrGnrtr4InvrtrRtLmtsRqst2Cntr 12031;
BA_ "SPN" SG_ 2365268734 MtrGnrtr4InvrtrPIDCntrlAppllMd 12032;
BA_ "SPN" SG_ 2365268734 MtGt4IvtPIDCtNzdDtG 12033;
BA_ "SPN" SG_ 2365268734 MtGt4IvtPIDCtNzdItG 12034;
BA_ "SPN" SG_ 2365268734 MtGt4IvtPIDCtNzdPptG 12035;
BA_ "SPN" SG_ 2365268734 MtGt4IvtPIDCtFdFwdTq 12036;
BA_ "SPN" SG_ 2566595582 MtrGnrtr4InvrtrLmtsRqstPwrCRC 11945;
BA_ "SPN" SG_ 2566595582 MtrGnrtr4InvrtrLmtsRqstPwrCntr 11946;
BA_ "SPN" SG_ 2566595582 MtGt4IvtLtsRqstMPwMx 11947;
BA_ "SPN" SG_ 2566595582 MtGt4IvtLtsRqstMPwM 11948;
BA_ "SPN" SG_ 2566595582 MtGt4IvtLtsRqstDCSdPwMx 11949;
BA_ "SPN" SG_ 2566595582 MtGt4IvtLtsRqstDCSdPwM 11950;
BA_ "SPN" SG_ 2566595838 MtrGnrtr4InvrtrLmtsRqstMhnlCRC 11957;
BA_ "SPN" SG_ 2566595838 MtrGnrtr4InvrtrLmtsRqstMhnlCntr 11958;
BA_ "SPN" SG_ 2566595838 MtrGnrtr4InvrtrLmtsRqstTrqMxmm 11959;
BA_ "SPN" SG_ 2566595838 MtrGnrtr4InvrtrLmtsRqstTrqMnmm 11960;
BA_ "SPN" SG_ 2566595838 MtrGnrtr4InvrtrLmtsRqstSpdMxmm 11961;
BA_ "SPN" SG_ 2566595838 MtrGnrtr4InvrtrLmtsRqstSpdMnmm 11962;
BA_ "SPN" SG_ 2566596094 MtrGnrtr4InvrtrLmtsRqstDCSdCRC 11973;
BA_ "SPN" SG_ 2566596094 MtrGnrtr4InvrtrLmtsRqstDCSdCntr 11974;
BA_ "SPN" SG_ 2566596094 MtGt4IvtLtsRqstDCSdVtMx 11975;
BA_ "SPN" SG_ 2566596094 MtGt4IvtLtsRqstDCSdVtM 11976;
BA_ "SPN" SG_ 2566596094 MtGt4IvtLtsRqstDCSdCtMx 11977;
BA_ "SPN" SG_ 2566596094 MtGt4IvtLtsRqstDCSdCtM 11978;
BA_ "SPN" SG_ 2566596350 MtGt4IvtHVtBsAtvIstTstCd 11996;
BA_ "SPN" SG_ 2566596350 MtGt4IvtHVtBsPssvIstTstCd 11997;
BA_ "SPN" SG_ 2566596350 MtGt4IvtHVtBsHSdRsstCtRqst 11998;
BA_ "SPN" SG_ 2566596350 MtGt4IvtHVtBsLwSdRsstCtRqst 11999;
BA_ "SPN" SG_ 2365270014 MtrGnrtr3InvrtrRtLmtsRqst2CRC 11912;
BA_ "SPN" SG_ 2365270014 MtrGnrtr3InvrtrRtLmtsRqst2Cntr 11913;
BA_ "SPN" SG_ 2365270014 MtrGnrtr3InvrtrPIDCntrlAppllMd 11914;
BA_ "SPN" SG_ 2365270014 MtGt3IvtPIDCtNzdDtG 11915;
BA_ "SPN" SG_ 2365270014 MtGt3IvtPIDCtNzdItG 11916;
BA_ "SPN" SG_ 2365270014 MtGt3IvtPIDCtNzdPptG 11917;
BA_ "SPN" SG_ 2365270014 MtGt3IvtPIDCtFdFwdTq 11918;
BA_ "SPN" SG_ 2566596862 MtrGnrtr3InvrtrLmtsRqstPwrCRC 11827;
BA_ "SPN" SG_ 2566596862 MtrGnrtr3InvrtrLmtsRqstPwrCntr 11828;
BA_ "SPN" SG_ 2566596862 MtGt3IvtLtsRqstMPwMx 11829;
BA_ "SPN" SG_ 2566596862 MtGt3IvtLtsRqstMPwM 11830;
BA_ "SPN" SG_ 2566596862 MtGt3IvtLtsRqstDCSdPwMx 11831;
BA_ "SPN" SG_ 2566596862 MtGt3IvtLtsRqstDCSdPwM 11832;
BA_ "SPN" SG_ 2566597118 MtrGnrtr3InvrtrLmtsRqstMhnlCRC 11839;
BA_ "SPN" SG_ 2566597118 MtrGnrtr3InvrtrLmtsRqstMhnlCntr 11840;
BA_ "SPN" SG_ 2566597118 MtrGnrtr3InvrtrLmtsRqstTrqMxmm 11841;
BA_ "SPN" SG_ 2566597118 MtrGnrtr3InvrtrLmtsRqstTrqMnmm 11842;
BA_ "SPN" SG_ 2566597118 MtrGnrtr3InvrtrLmtsRqstSpdMxmm 11843;
BA_ "SPN" SG_ 2566597118 MtrGnrtr3InvrtrLmtsRqstSpdMnmm 11844;
BA_ "SPN" SG_ 2566597374 MtrGnrtr3InvrtrLmtsRqstDCSdCRC 11855;
BA_ "SPN" SG_ 2566597374 MtrGnrtr3InvrtrLmtsRqstDCSdCntr 11856;
BA_ "SPN" SG_ 2566597374 MtGt3IvtLtsRqstDCSdVtMx 11857;
BA_ "SPN" SG_ 2566597374 MtGt3IvtLtsRqstDCSdVtM 11858;
BA_ "SPN" SG_ 2566597374 MtGt3IvtLtsRqstDCSdCtMx 11859;
BA_ "SPN" SG_ 2566597374 MtGt3IvtLtsRqstDCSdCtM 11860;
BA_ "SPN" SG_ 2566597630 MtGt3IvtHVtBsAtvIstTstCd 11878;
BA_ "SPN" SG_ 2566597630 MtGt3IvtHVtBsPssvIstTstCd 11879;
BA_ "SPN" SG_ 2566597630 MtGt3IvtHVtBsHSdRsstCtRqst 11880;
BA_ "SPN" SG_ 2566597630 MtGt3IvtHVtBsLwSdRsstCtRqst 11881;
BA_ "SPN" SG_ 2566598142 EngineTurbocharger5Speed 12313;
BA_ "SPN" SG_ 2566598142 EngineTurbocharger6Speed 12314;
BA_ "SPN" SG_ 2566598142 EngnTrhrgr5CmprssrIntkPrssr 12315;
BA_ "SPN" SG_ 2566598142 EngnTrhrgr6CmprssrIntkPrssr 12316;
BA_ "SPN" SG_ 2566598398 WinchLifetimeRevolutionCounter 12311;
BA_ "SPN" SG_ 2365272062 MtrGnrtr6InvrtrRfrn1CRC 12173;
BA_ "SPN" SG_ 2365272062 MtrGnrtr6InvrtrRfrn1Cntr 12174;
BA_ "SPN" SG_ 2365272062 MtrGnrtr6InvrtrRfrnTrq 12175;
BA_ "SPN" SG_ 2365272062 MtrGnrtr6InvrtrRfrnSpd 12176;
BA_ "SPN" SG_ 2365272062 MtrGnrtr6InvrtrRfrnPwr 12177;
BA_ "SPN" SG_ 2365272318 MtrGnrtr6InvrtrStts1CRC 12178;
BA_ "SPN" SG_ 2365272318 MtrGnrtr6InvrtrStts1Cntr 12179;
BA_ "SPN" SG_ 2365272318 MotorGenerator6Torque 12157;
BA_ "SPN" SG_ 2365272318 MotorGenerator6Speed 12155;
BA_ "SPN" SG_ 2365272318 MtrGnrtr6InvrtrDCSdCrrnt 12180;
BA_ "SPN" SG_ 2365272318 MtrGnrtr6InvrtrDCSdVltg 12158;
